VERSION "HNNBNNNYNNNNNNNNNNNNNNNNNNNNNNNNNNNNNNNNNN/4/%%%/4/'%**4NNN///"

NS_ :

BS_:

BU_: Airbag_D4 EPB_D4 ESP_D4 Gateway_D4C7 Getriebe_AL551_951_D4_C7 Getriebe_DL501_C7 Getriebe_VL381_C7 LWS_D4 Motor_EDC17_D4 Motor_ME17_BY Motor_MED17_SIMOS8_D4 Motor_Slave_D4 QSP_D4 SAK_C7 SCR_C7 SCU_D4

BO_ 3221225472 VECTOR__INDEPENDENT_SIG_MSG: 0 Vector__XXX
 SG_ AGA_Charisma_FahrPr : 0|4@1+ (1,0) [0|15] "" Vector__XXX
 SG_ AGA_Charisma_Status : 0|2@1+ (1,0) [0|3] "" Vector__XXX
 SG_ AGA_Verstaerker_Mute : 0|1@1+ (1,0) [0|1] "" Vector__XXX
 SG_ TPS_Airbag_Data : 0|56@1+ (1,0) [0|7.20575940379279E+016] "" Vector__XXX

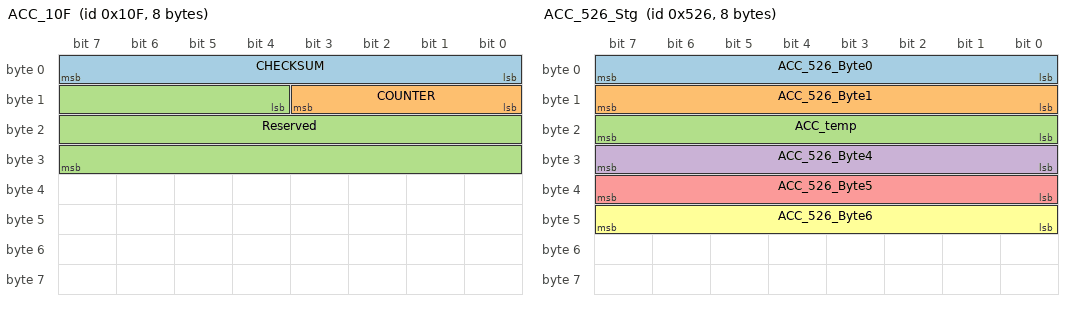
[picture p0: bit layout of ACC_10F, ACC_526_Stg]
BO_ 271 ACC_10F: 8 Gateway_B8
 SG_ CHECKSUM: 0|8@1+ (1,0) [0|255] "" J428
 SG_ COUNTER: 8|4@1+ (1,0) [0|15] "" J428
 SG_ Reserved: 12|20@1+ (1,0) [0|1048575] "" Antrieb

BO_ 785 ACC_311: 8 Gateway_B8
 SG_ CHECKSUM: 0|4@1+ (1,0) [0|15] "" J428
 SG_ COUNTER: 8|4@1+ (1,0) [0|15] "" J428
 SG_ ACC_311_Fahren1: 6|2@1+ (1,0) [0|3] "" J428
 SG_ ACC_311_Meldungen: 16|4@1+ (1,0) [0|15] "" J428
 SG_ ACC_311_Anzeige: 22|2@1+ (1,0) [0|3] "" J428
 SG_ ACC_311_Byte3: 0|8@1+ (1,0) [0|255] "" J428

BO_ 1318 ACC_526_Stg: 8 J428
 SG_ ACC_526_Byte0 : 0|8@1+ (1,0) [0|255] "" J428
 SG_ ACC_526_Byte1 : 8|8@1+ (1,0) [0|255] "" J428
 SG_ ACC_temp : 16|8@1+ (0.5,-30) [-30|90] "°C" J428
 SG_ ACC_526_Byte4 : 24|8@1+ (1,0) [0|255] "" J428
 SG_ ACC_526_Byte5 : 32|8@1+ (1,0) [0|255] "" J428
 SG_ ACC_526_Byte6 : 40|8@1+ (1,0) [0|255] "" J428

VAL_ 1318 ACC_526_Byte0 0 "Fernlicht" 1 "Ausschalten" 4 "Stand" 16 "Ueber_60_kmh" 20 "Unter_50_kmh" 128 "Anschalten";
VAL_ 1318 ACC_526_Byte4 16 "Kein_Objekt" 24 "Objekt_erkannt";

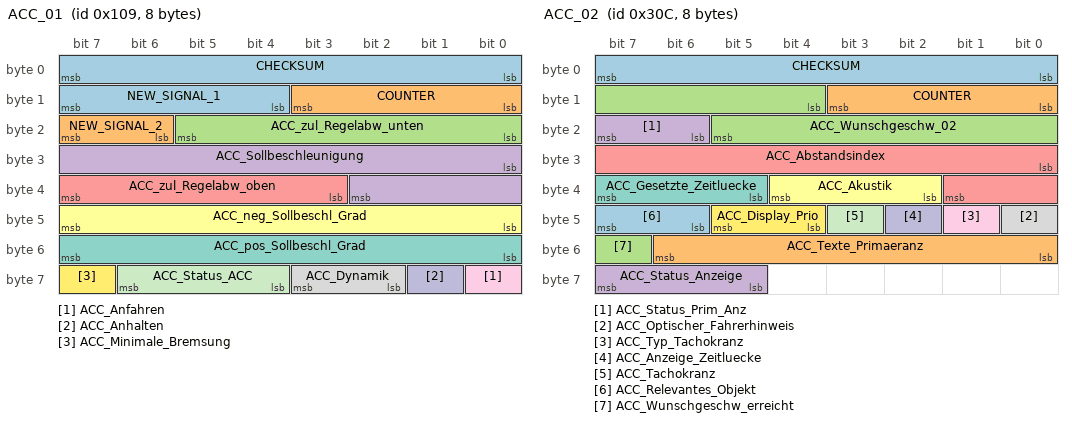
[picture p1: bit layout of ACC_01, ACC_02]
BO_ 265 ACC_01: 8 Gateway_B8
 SG_ CHECKSUM : 0|8@1+ (1,0) [0|255] ""  Magnetic_Ride_LB,Motor_MLB_AU48_AU416_Diesel,Motor_MLB_B8_Q5_Otto,Motor_MLB_Q5_Hybrid
 SG_ COUNTER : 8|4@1+ (1,0) [0|15] ""  Magnetic_Ride_LB,Motor_MLB_AU48_AU416_Diesel,Motor_MLB_B8_Q5_Otto,Motor_MLB_Q5_Hybrid
 SG_ ACC_zul_Regelabw_unten : 16|6@1+ (0.024,0) [0|1.512] "Unit_MeterPerSeconSquar"  Motor_MLB_AU48_AU416_Diesel,Motor_MLB_B8_Q5_Otto,Motor_MLB_Q5_Hybrid
 SG_ ACC_Sollbeschleunigung : 24|11@1+ (0.005,-7.22) [-7.22|3.01] "Unit_MeterPerSeconSquar"  Magnetic_Ride_LB,Motor_MLB_AU48_AU416_Diesel,Motor_MLB_B8_Q5_Otto,Motor_MLB_Q5_Hybrid
 SG_ ACC_zul_Regelabw_oben : 35|5@1+ (0.0625,0) [0|1.9375] "Unit_MeterPerSeconSquar"  Motor_MLB_AU48_AU416_Diesel,Motor_MLB_B8_Q5_Otto,Motor_MLB_Q5_Hybrid
 SG_ ACC_neg_Sollbeschl_Grad : 40|8@1+ (0.05,0) [0|12.7] "Unit_MeterPerCubicSecon"  Motor_MLB_AU48_AU416_Diesel,Motor_MLB_B8_Q5_Otto,Motor_MLB_Q5_Hybrid
 SG_ ACC_pos_Sollbeschl_Grad : 48|8@1+ (0.05,0) [0|12.7] "Unit_MeterPerCubicSecon"  Motor_MLB_AU48_AU416_Diesel,Motor_MLB_B8_Q5_Otto,Motor_MLB_Q5_Hybrid
 SG_ ACC_Dynamik : 58|2@1+ (1,0) [0|3] ""  Motor_MLB_AU48_AU416_Diesel,Motor_MLB_B8_Q5_Otto,Motor_MLB_Q5_Hybrid
 SG_ ACC_Anfahren : 56|1@1+ (1,0) [0|1] ""  XXX
 SG_ ACC_Anhalten : 57|1@1+ (1,0) [0|1] ""  XXX
 SG_ ACC_Status_ACC : 60|3@1+ (1,0) [0|7] ""  XXX
 SG_ ACC_Minimale_Bremsung : 63|1@1+ (1,0) [0|1] ""  Motor_MLB_AU48_AU416_Diesel,Motor_MLB_B8_Q5_Otto,Motor_MLB_Q5_Hybrid
 SG_ NEW_SIGNAL_1 : 15|4@0+ (1,0) [0|15] "" XXX
 SG_ NEW_SIGNAL_2 : 23|2@0+ (1,0) [0|3] "" XXX

BO_ 780 ACC_02: 8 Gateway_D4C7
 SG_ CHECKSUM : 0|8@1+ (1,0) [0|255] ""  HUD_C7,Kombi_D4
 SG_ COUNTER : 8|4@1+ (1,0) [0|15] ""  HUD_C7,Kombi_D4
 SG_ ACC_Wunschgeschw_02 : 12|10@1+ (0.32,0) [0.00|326.72] "Unit_KiloMeterPerHour"  HUD_C7,Kombi_D4
 SG_ ACC_Status_Prim_Anz : 22|2@1+ (1.0,0.0) [0.0|3] ""  HUD_C7,Kombi_D4
 SG_ ACC_Abstandsindex : 24|10@1+ (1,0) [1|1021] ""  HUD_C7,Kombi_D4
 SG_ ACC_Akustik : 34|3@1+ (1.0,0.0) [0.0|7] ""  Kombi_D4
 SG_ ACC_Gesetzte_Zeitluecke : 37|3@1+ (1.0,0.0) [0.0|7] ""  Kombi_D4
 SG_ ACC_Optischer_Fahrerhinweis : 40|1@1+ (1.0,0.0) [0.0|1] ""  Kombi_D4
 SG_ ACC_Typ_Tachokranz : 41|1@1+ (1.0,0.0) [0.0|1] ""  Kombi_D4
 SG_ ACC_Anzeige_Zeitluecke : 42|1@1+ (1.0,0.0) [0.0|1] ""  Kombi_D4
 SG_ ACC_Tachokranz : 43|1@1+ (1.0,0.0) [0.0|1] ""  Kombi_D4
 SG_ ACC_Display_Prio : 44|2@1+ (1.0,0.0) [0.0|3] ""  Vector__XXX
 SG_ ACC_Relevantes_Objekt : 46|2@1+ (1.0,0.0) [0.0|3] ""  HUD_C7,Kombi_D4
 SG_ ACC_Texte_Primaeranz : 48|7@1+ (1.0,0.0) [0.0|127] ""  HUD_C7,Kombi_D4
 SG_ ACC_Wunschgeschw_erreicht : 55|1@1+ (1.0,0.0) [0.0|1] ""  Kombi_D4
 SG_ ACC_Status_Anzeige : 61|3@1+ (1.0,0.0) [0.0|7] ""  APS_D4,Kombi_D4

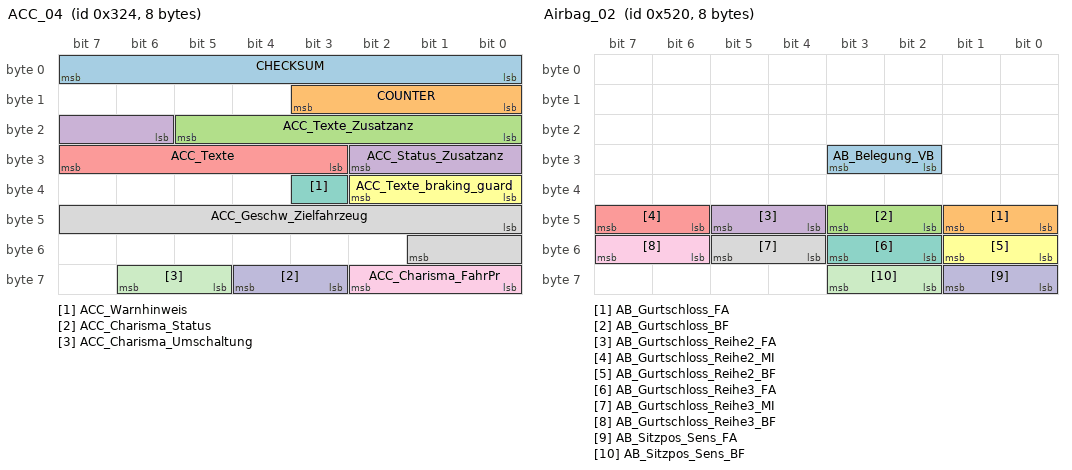
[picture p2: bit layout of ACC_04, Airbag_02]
BO_ 804 ACC_04: 8 Gateway_D4C7
 SG_ CHECKSUM : 0|8@1+ (1,0) [0|255] ""  HUD_C7,Kombi_D4
 SG_ COUNTER : 8|4@1+ (1,0) [0|15] ""  HUD_C7,Kombi_D4
 SG_ ACC_Texte_Zusatzanz : 16|6@1+ (1.0,0.0) [0.0|63] ""  Kombi_D4
 SG_ ACC_Status_Zusatzanz : 22|5@1+ (1.0,0.0) [0.0|31] ""  HUD_C7,Kombi_D4
 SG_ ACC_Texte : 27|5@1+ (1.0,0.0) [0.0|31] ""  Kombi_D4
 SG_ ACC_Texte_braking_guard : 32|3@1+ (1.0,0.0) [0.0|7] ""  HUD_C7,Kombi_D4
 SG_ ACC_Warnhinweis : 35|1@1+ (1.0,0.0) [0.0|1] ""  Vector__XXX
 SG_ ACC_Geschw_Zielfahrzeug : 40|10@1+ (0.32,0) [0.00|326.72] "Unit_KiloMeterPerHour"  Vector__XXX
 SG_ ACC_Charisma_FahrPr : 56|3@1+ (1.0,0.0) [0.0|7] ""  Vector__XXX
 SG_ ACC_Charisma_Status : 59|2@1+ (1.0,0.0) [0.0|3] ""  Vector__XXX
 SG_ ACC_Charisma_Umschaltung : 61|2@1+ (1.0,0.0) [0.0|3] ""  Vector__XXX

BO_ 269 ACC_05: 8 Gateway_D4C7
 SG_ CHECKSUM : 0|8@1+ (1,0) [0|255] ""  EPB_D4,Getriebe_AL551_951_D4_C7,Getriebe_DL501_C7,Getriebe_VL381_C7,Motor_EDC17_D4,Motor_ME17_BY,Motor_MED17_SIMOS8_D4
 SG_ COUNTER : 8|4@1+ (1,0) [0|15] ""  EPB_D4,Getriebe_AL551_951_D4_C7,Getriebe_DL501_C7,Getriebe_VL381_C7,Motor_EDC17_D4,Motor_ME17_BY,Motor_MED17_SIMOS8_D4
 SG_ ACC_Freigabe_Momentenanf : 12|1@1+ (1.0,0.0) [0.0|1] ""  Motor_EDC17_D4,Motor_ME17_BY,Motor_MED17_SIMOS8_D4
 SG_ ACC_Freigabe_Verzanf : 13|1@1+ (1.0,0.0) [0.0|1] ""  Getriebe_AL551_951_D4_C7,Getriebe_DL501_C7,Getriebe_VL381_C7
 SG_ ACC_Getriebestellung_P : 14|1@1+ (1.0,0.0) [0.0|1] ""  Getriebe_AL551_951_D4_C7,Getriebe_DL501_C7,Getriebe_VL381_C7
 SG_ ACC_limitierte_Anfahrdyn : 15|1@1+ (1.0,0.0) [0.0|1] ""  Motor_EDC17_D4,Motor_ME17_BY,Motor_MED17_SIMOS8_D4
 SG_ ACC_Momentenanforderung : 16|10@1+ (1,0) [0|1021] ""  Motor_EDC17_D4,Motor_ME17_BY,Motor_MED17_SIMOS8_D4
 SG_ ACC_zul_Regelabw : 26|6@1+ (0.024,0) [0.000|1.512] "Unit_MeterPerSeconSquar"  Getriebe_AL551_951_D4_C7,Getriebe_DL501_C7,Getriebe_VL381_C7
 SG_ ACC_Verz_anf : 32|11@1+ (0.005,-7.22) [-7.220|3.015] "Unit_MeterPerSeconSquar"  Vector__XXX
 SG_ ACC_Loeseanforderung : 43|1@1+ (1.0,0.0) [0.0|1] ""  Vector__XXX
 SG_ ACC_StartStopp_Info : 44|2@1+ (1.0,0.0) [0.0|3] ""  Motor_EDC17_D4,Motor_ME17_BY,Motor_MED17_SIMOS8_D4
 SG_ ACC_Vorbefuellung_Bremsanlage : 47|1@1+ (1.0,0.0) [0.0|1] ""  Vector__XXX
 SG_ ACC_ax_Getriebe : 48|9@1+ (0.024,-2.016) [-2.016|10.248] "Unit_MeterPerSeconSquar"  Getriebe_AL551_951_D4_C7,Getriebe_DL501_C7,Getriebe_VL381_C7
 SG_ ACC_Status_ACC : 57|3@1+ (1.0,0.0) [0.0|7] ""  EPB_D4,Motor_EDC17_D4,Motor_ME17_BY,Motor_MED17_SIMOS8_D4
 SG_ ACC_Betaetigung_EPB : 60|1@1+ (1.0,0.0) [0.0|1] ""  EPB_D4,Motor_EDC17_D4,Motor_ME17_BY,Motor_MED17_SIMOS8_D4
 SG_ ACC_Beeinflussung_ESP : 61|1@1+ (1.0,0.0) [0.0|1] ""  Vector__XXX
 SG_ ACC_Anhalten : 62|1@1+ (1.0,0.0) [0.0|1] ""  Vector__XXX
 SG_ ACC_KD_Fehler : 63|1@1+ (1.0,0.0) [0.0|1] ""  Vector__XXX

BO_ 64 Airbag_01: 8 Airbag_D4
 SG_ Airbag_01_CHK : 0|8@1+ (1,0) [0|255] ""  Gateway_D4C7,Motor_EDC17_D4,Motor_ME17_BY,Motor_MED17_SIMOS8_D4
 SG_ Airbag_01_BZ : 8|4@1+ (1,0) [0|15] ""  Gateway_D4C7,Motor_EDC17_D4,Motor_ME17_BY,Motor_MED17_SIMOS8_D4
 SG_ AB_RGS_Anst : 12|4@1+ (1.0,0.0) [0.0|15] ""  Gateway_D4C7
 SG_ AB_Front_Crash : 16|1@1+ (1.0,0.0) [0.0|1] ""  Gateway_D4C7
 SG_ AB_Heck_Crash : 17|1@1+ (1.0,0.0) [0.0|1] ""  Gateway_D4C7
 SG_ AB_SF_Crash : 18|1@1+ (1.0,0.0) [0.0|1] ""  Gateway_D4C7
 SG_ AB_SB_Crash : 19|1@1+ (1.0,0.0) [0.0|1] ""  Gateway_D4C7
 SG_ AB_Rollover_Crash : 20|1@1+ (1.0,0.0) [0.0|1] ""  Gateway_D4C7
 SG_ AB_Crash_Int : 21|3@1+ (1.0,0.0) [0.0|7] ""  Gateway_D4C7,Motor_EDC17_D4,Motor_ME17_BY,Motor_MED17_SIMOS8_D4
 SG_ AB_Lampe : 24|1@1+ (1.0,0.0) [0.0|1] ""  Gateway_D4C7
 SG_ AB_Deaktiviert : 25|1@1+ (1.0,0.0) [0.0|1] ""  Gateway_D4C7
 SG_ AB_VB_deaktiviert : 26|1@1+ (1.0,0.0) [0.0|1] ""  Gateway_D4C7
 SG_ AB_Systemfehler : 27|1@1+ (1.0,0.0) [0.0|1] ""  Gateway_D4C7
 SG_ AB_Diagnose : 28|1@1+ (1.0,0.0) [0.0|1] ""  Gateway_D4C7
 SG_ AB_Stellgliedtest : 29|1@1+ (1.0,0.0) [0.0|1] ""  Gateway_D4C7,Motor_EDC17_D4,Motor_ME17_BY,Motor_MED17_SIMOS8_D4
 SG_ AB_Erh_Auf_VB : 30|2@1+ (1.0,0.0) [0.0|3] ""  Gateway_D4C7
 SG_ AB_Gurtwarn_VF : 32|1@1+ (1.0,0.0) [0.0|1] ""  Gateway_D4C7
 SG_ AB_Gurtwarn_VB : 33|1@1+ (1.0,0.0) [0.0|1] ""  Gateway_D4C7
 SG_ AB_Anzeige_Fussg : 34|2@1+ (1.0,0.0) [0.0|3] ""  Gateway_D4C7
 SG_ AB_Texte_AKS : 36|2@1+ (1.0,0.0) [0.0|3] ""  Gateway_D4C7
 SG_ AB_PAO_Leuchte_Anf : 38|1@1+ (1.0,0.0) [0.0|1] ""  Gateway_D4C7
 SG_ AB_MKB_gueltig : 39|1@1+ (1.0,0.0) [0.0|1] ""  Gateway_D4C7
 SG_ AB_MKB_Anforderung : 40|1@1+ (1.0,0.0) [0.0|1] ""  Gateway_D4C7
 SG_ AB_Versorgungsspannung : 41|1@1+ (1.0,0.0) [0.0|1] ""  Gateway_D4C7
 SG_ AB_KD_Fehler : 63|1@1+ (1.0,0.0) [0.0|1] ""  Gateway_D4C7

BO_ 1312 Airbag_02: 8 Airbag_D4
 SG_ AB_Belegung_VB : 26|2@1+ (1.0,0.0) [0.0|3] ""  Gateway_D4C7
 SG_ AB_Gurtschloss_FA : 40|2@1+ (1.0,0.0) [0.0|3] ""  EPB_D4,Gateway_D4C7,Motor_EDC17_D4,Motor_ME17_BY,Motor_MED17_SIMOS8_D4
 SG_ AB_Gurtschloss_BF : 42|2@1+ (1.0,0.0) [0.0|3] ""  Gateway_D4C7
 SG_ AB_Gurtschloss_Reihe2_FA : 44|2@1+ (1.0,0.0) [0.0|3] ""  Gateway_D4C7
 SG_ AB_Gurtschloss_Reihe2_MI : 46|2@1+ (1.0,0.0) [0.0|3] ""  Gateway_D4C7
 SG_ AB_Gurtschloss_Reihe2_BF : 48|2@1+ (1.0,0.0) [0.0|3] ""  Gateway_D4C7
 SG_ AB_Gurtschloss_Reihe3_FA : 50|2@1+ (1.0,0.0) [0.0|3] ""  Gateway_D4C7
 SG_ AB_Gurtschloss_Reihe3_MI : 52|2@1+ (1.0,0.0) [0.0|3] ""  Gateway_D4C7
 SG_ AB_Gurtschloss_Reihe3_BF : 54|2@1+ (1.0,0.0) [0.0|3] ""  Gateway_D4C7
 SG_ AB_Sitzpos_Sens_FA : 56|2@1+ (1.0,0.0) [0.0|3] ""  Gateway_D4C7
 SG_ AB_Sitzpos_Sens_BF : 58|2@1+ (1.0,0.0) [0.0|3] ""  Gateway_D4C7

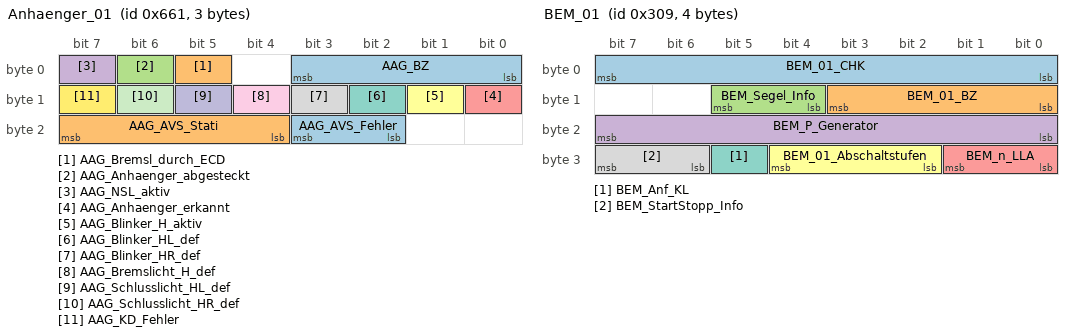
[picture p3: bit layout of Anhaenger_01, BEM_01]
BO_ 1633 Anhaenger_01: 3 Gateway_D4C7
 SG_ AAG_BZ : 0|4@1+ (1,0) [0|15] ""  Getriebe_AL551_951_D4_C7,Motor_EDC17_D4,Motor_ME17_BY,Motor_MED17_SIMOS8_D4
 SG_ AAG_Bremsl_durch_ECD : 5|1@1+ (1.0,0.0) [0.0|1] ""  Motor_EDC17_D4,Motor_ME17_BY,Motor_MED17_SIMOS8_D4
 SG_ AAG_Anhaenger_abgesteckt : 6|1@1+ (1.0,0.0) [0.0|1] ""  Vector__XXX
 SG_ AAG_NSL_aktiv : 7|1@1+ (1.0,0.0) [0.0|1] ""  Vector__XXX
 SG_ AAG_Anhaenger_erkannt : 8|1@1+ (1.0,0.0) [0.0|1] ""  Getriebe_AL551_951_D4_C7,Getriebe_DL501_C7,Getriebe_VL381_C7,Motor_EDC17_D4,Motor_ME17_BY,Motor_MED17_SIMOS8_D4
 SG_ AAG_Blinker_H_aktiv : 9|1@1+ (1.0,0.0) [0.0|1] ""  Vector__XXX
 SG_ AAG_Blinker_HL_def : 10|1@1+ (1.0,0.0) [0.0|1] ""  Vector__XXX
 SG_ AAG_Blinker_HR_def : 11|1@1+ (1.0,0.0) [0.0|1] ""  Vector__XXX
 SG_ AAG_Bremslicht_H_def : 12|1@1+ (1.0,0.0) [0.0|1] ""  Motor_EDC17_D4,Motor_ME17_BY,Motor_MED17_SIMOS8_D4
 SG_ AAG_Schlusslicht_HL_def : 13|1@1+ (1.0,0.0) [0.0|1] ""  Vector__XXX
 SG_ AAG_Schlusslicht_HR_def : 14|1@1+ (1.0,0.0) [0.0|1] ""  Vector__XXX
 SG_ AAG_KD_Fehler : 15|1@1+ (1.0,0.0) [0.0|1] ""  Vector__XXX
 SG_ AAG_AVS_Fehler : 18|2@1+ (1.0,0.0) [0.0|3] ""  Vector__XXX
 SG_ AAG_AVS_Stati : 20|4@1+ (1.0,0.0) [0.0|15] ""  Vector__XXX

BO_ 777 BEM_01: 4 Gateway_D4C7
 SG_ BEM_01_CHK : 0|8@1+ (1,0) [0|255] ""  Motor_EDC17_D4,Motor_ME17_BY,Motor_MED17_SIMOS8_D4
 SG_ BEM_01_BZ : 8|4@1+ (1,0) [0|15] ""  Motor_EDC17_D4,Motor_ME17_BY,Motor_MED17_SIMOS8_D4
 SG_ BEM_Segel_Info : 12|2@1+ (1.0,0.0) [0.0|3] ""  Vector__XXX
 SG_ BEM_P_Generator : 16|8@1+ (50,0) [0|12700] "Unit_Watt"  Motor_EDC17_D4,Motor_ME17_BY,Motor_MED17_SIMOS8_D4
 SG_ BEM_n_LLA : 24|2@1+ (1.0,0.0) [0.0|3] ""  Motor_EDC17_D4,Motor_ME17_BY,Motor_MED17_SIMOS8_D4
 SG_ BEM_01_Abschaltstufen : 26|3@1+ (1.0,0.0) [0.0|7] ""  Vector__XXX
 SG_ BEM_Anf_KL : 29|1@1+ (1.0,0.0) [0.0|1] ""  Motor_EDC17_D4,Motor_ME17_BY,Motor_MED17_SIMOS8_D4
 SG_ BEM_StartStopp_Info : 30|2@1+ (1.0,0.0) [0.0|3] ""  Motor_EDC17_D4,Motor_ME17_BY,Motor_MED17_SIMOS8_D4

BO_ 1635 BEM_02: 8 Gateway
 SG_ BEM_02_Abschaltstufen : 0|3@1+ (1,0) [0|7] "" Vector__XXX
 SG_ BEM_STH_Zielzeit : 3|4@1+ (5,0) [0|60] "Unit_Minut" Vector__XXX
 SG_ BEM_MMI_Vorwarnung : 7|1@1+ (1,0) [0|1] "" Vector__XXX
 SG_ BEM_HL_Kontingentierung : 8|6@1+ (50,-1000) [-1000|1000] "Unit_Watt" Vector__XXX
 SG_ NVEM_Anf_SD_schalten : 15|1@1+ (1,0) [0|1] "" Vector__XXX
 SG_ BEM_Generatordiagnose : 16|2@1+ (1,0) [0|3] "" Vector__XXX
 SG_ BEM_Red_Innengeblaese : 18|2@1+ (1,0) [0|3] "" Vector__XXX
 SG_ BEM_STH_Einschaltverbot : 20|1@1+ (1,0) [0|1] "" Vector__XXX
 SG_ BEM_HL_Regelung_Status : 21|3@1+ (1,0) [0|7] ""  Motor_MLB_AU64_AU57_Diesel
 SG_ BEM_Ladezustand : 24|4@1+ (10,0) [0|100] "Unit_PerCent" Vector__XXX
 SG_ BEM_Batteriediagnose : 28|3@1+ (1,0) [0|7] "" Vector__XXX
 SG_ MIB_Stromsparmodus : 31|1@1+ (1,0) [0|1] "" Vector__XXX
 SG_ BEM_DFM : 32|5@1+ (3.225,0.025) [0.025|100] "" Vector__XXX
 SG_ BEM_REK_aktiv : 37|1@1+ (1,0) [0|1] ""  Motor_MLB_AU64_AU57_Diesel
 SG_ BEM_EMLIN_ungueltig : 38|1@1+ (1,0) [0|1] "" Vector__XXX
 SG_ BEM_Batt_Ab : 39|1@1+ (1,0) [0|1] "" Vector__XXX
 SG_ BEM_UBDM : 40|8@1+ (0.05,5) [5.05|17.7] "Unit_Volt" Vector__XXX
 SG_ BEM_UGenSoll : 48|6@1+ (0.1,10.6) [10.6|16] "Unit_Volt" Vector__XXX
 SG_ BEM_Anf_KL15_schalten : 54|2@1+ (1,0) [0|3] "" Vector__XXX

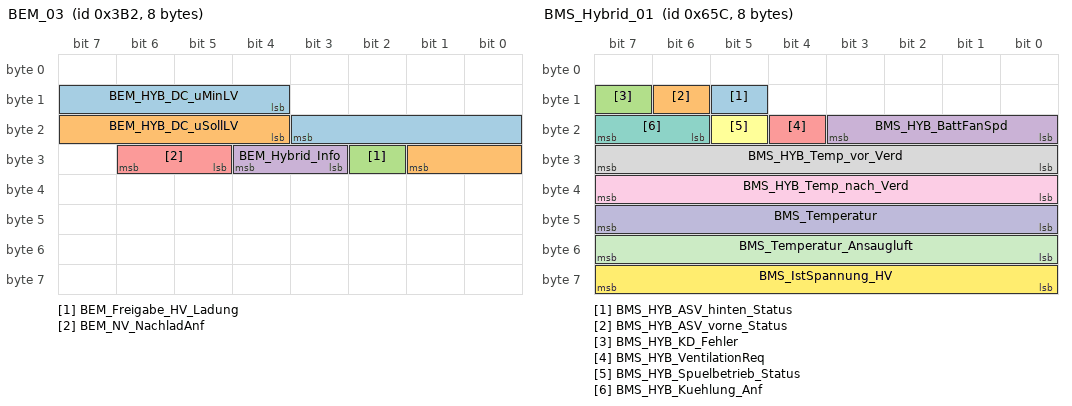
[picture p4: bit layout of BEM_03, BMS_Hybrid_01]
BO_ 946 BEM_03: 8 Gateway
 SG_ BEM_HYB_DC_uMinLV : 12|8@1+ (0.1,0) [0|25.3] "Unit_Volt"  LEH_Hybrid
 SG_ BEM_HYB_DC_uSollLV : 20|6@1+ (0.1,10.6) [10.6|16] "Unit_Volt"  LEH_Hybrid
 SG_ BEM_Freigabe_HV_Ladung : 26|1@1+ (1,0) [0|1] ""  Motor_MLB_C7_PHEV,Motor_MLB_D4_C7_Hybrid
 SG_ BEM_Hybrid_Info : 27|2@1+ (1,0) [0|3] ""  Motor_MLB_C7_PHEV,Motor_MLB_D4_C7_Hybrid
 SG_ BEM_NV_NachladAnf : 29|2@1+ (1,0) [0|3] "" Vector__XXX

BO_ 1628 BMS_Hybrid_01: 8 BMS_Hybrid
 SG_ BMS_HYB_ASV_hinten_Status : 13|1@1+ (1,0) [0|1] ""  Gateway
 SG_ BMS_HYB_ASV_vorne_Status : 14|1@1+ (1,0) [0|1] ""  Gateway
 SG_ BMS_HYB_KD_Fehler : 15|1@1+ (1,0) [0|1] ""  Gateway
 SG_ BMS_HYB_BattFanSpd : 16|4@1+ (10,0) [0|100] "Unit_PerCent"  Gateway
 SG_ BMS_HYB_VentilationReq : 20|1@1+ (1,0) [0|1] ""  Gateway
 SG_ BMS_HYB_Spuelbetrieb_Status : 21|1@1+ (1,0) [0|1] ""  Gateway
 SG_ BMS_HYB_Kuehlung_Anf : 22|2@1+ (1,0) [0|3] ""  Gateway
 SG_ BMS_HYB_Temp_vor_Verd : 24|8@1+ (0.5,-40) [-40|86.5] "Unit_DegreCelsi"  Gateway
 SG_ BMS_HYB_Temp_nach_Verd : 32|8@1+ (0.5,-40) [-40|86.5] "Unit_DegreCelsi"  Gateway
 SG_ BMS_Temperatur : 40|8@1+ (0.5,-40) [-40|86.5] "Unit_DegreCelsi"  Gateway
 SG_ BMS_Temperatur_Ansaugluft : 48|8@1+ (0.5,-40) [-40|86.5] "Unit_DegreCelsi"  Gateway
 SG_ BMS_IstSpannung_HV : 56|8@1+ (1,100) [100|350] "Unit_Volt"  Gateway

BO_ 917 LWR_AFS_01: 8 AFS_MLB
 SG_ AFS_Abbiegelicht_li_Anf : 0|1@1+ (1,0) [0|1] ""  Gateway_B8
 SG_ AFS_Abbiegelicht_re_Anf : 1|1@1+ (1,0) [0|1] ""  Gateway_B8
 SG_ AFS_Abbiegelicht_Dimm_Anf : 2|1@1+ (1,0) [0|1] ""  Gateway_B8
 SG_ AFS_Verfuegbarkeit_GLW : 3|1@1+ (1,0) [0|1] ""  Gateway_B8
 SG_ AFS_Status_adaptive_LV : 4|1@1+ (1,0) [0|1] ""  Gateway_B8
 SG_ AFS_Fernlicht_li_defekt : 5|1@1+ (1,0) [0|1] ""  Gateway_B8
 SG_ AFS_Fernlicht_re_defekt : 6|1@1+ (1,0) [0|1] ""  Gateway_B8
 SG_ AFS_Fernlicht_Status : 7|1@1+ (1,0) [0|1] ""  Gateway_B8
 SG_ LWR_AFS_01_BZ : 8|4@1+ (1,0) [0|15] ""  Gateway_B8
 SG_ AFS_Lampe : 12|1@1+ (1,0) [0|1] ""  Gateway_B8
 SG_ LWR_Lampe : 13|1@1+ (1,0) [0|1] ""  Gateway_B8
 SG_ AFS_Fehlertext : 14|1@1+ (1,0) [0|1] ""  Gateway_B8
 SG_ AFS_LED_Blinkmode : 15|1@1+ (1,0) [0|1] ""  Gateway_B8
 SG_ LWR_Touristenmodus_aktiv : 16|1@1+ (1,0) [0|1] ""  Gateway_B8
 SG_ AFS_Charisma_FahrPr : 17|3@1+ (1,0) [0|7] ""  Gateway_B8
 SG_ AFS_Charisma_Status : 20|2@1+ (1,0) [0|3] ""  Gateway_B8
 SG_ AFS_Charisma_Umschaltung : 22|2@1+ (1,0) [0|3] ""  Gateway_B8
 SG_ AFS_Allwetterlicht : 24|1@1+ (1,0) [0|1] ""  Gateway_B8
 SG_ LWR_Touristenmodus_verbaut : 25|1@1+ (1,0) [0|1] ""  Gateway_B8
 SG_ AFS_adaptive_LV_verbaut : 26|1@1+ (1,0) [0|1] ""  Gateway_B8
 SG_ LWR_Reisemodus_Texte : 27|2@1+ (1,0) [0|3] ""  Gateway_B8
 SG_ GLW_Sensor_blockiert : 29|1@1+ (1,0) [0|1] ""  Gateway_B8
 SG_ LWR_Pos_Schrittmotor : 32|8@1+ (0.4,0) [0|100] "Unit_PerCent"  Gateway_B8
 SG_ LWR_Hoehenwert_VL : 40|8@1+ (1,-127) [-127|126] ""  Gateway_B8
 SG_ LWR_Hoehenwert_HL : 48|8@1+ (1,-127) [-127|126] ""  Gateway_B8
 SG_ AFS_Ersatzlicht_Links : 56|1@1+ (1,0) [0|1] ""  Gateway_B8
 SG_ AFS_Ersatzlicht_Rechts : 57|1@1+ (1,0) [0|1] ""  Gateway_B8
 SG_ LWR_AFS_Grundeinstellung : 58|1@1+ (1,0) [0|1] ""  Gateway_B8
 SG_ LWR_AFS_Parametrisierung : 59|1@1+ (1,0) [0|1] ""  Gateway_B8
 SG_ LWR_Initialisierungslauf : 60|1@1+ (1,0) [0|1] ""  Gateway_B8
 SG_ LWR_Sicherheitsposition : 61|1@1+ (1,0) [0|1] ""  Gateway_B8
 SG_ LWR_Modus : 62|1@1+ (1,0) [0|1] ""  Gateway_B8
 SG_ LWR_KD_Fehler : 63|1@1+ (1,0) [0|1] ""  Gateway_B8

BO_ 867 Blinkmodi_01: 4 Gateway_D4C7
 SG_ BM_ZV_auf : 0|1@1+ (1.0,0.0) [0.0|1] ""  Vector__XXX
 SG_ BM_ZV_zu : 1|1@1+ (1.0,0.0) [0.0|1] ""  Vector__XXX
 SG_ BM_DWA_ein : 2|1@1+ (1.0,0.0) [0.0|1] ""  Vector__XXX
 SG_ BM_DWA_Alarm : 3|1@1+ (1.0,0.0) [0.0|1] ""  Vector__XXX
 SG_ BM_Crash : 4|1@1+ (1.0,0.0) [0.0|1] ""  Vector__XXX
 SG_ BM_Panik : 5|1@1+ (1.0,0.0) [0.0|1] ""  Vector__XXX
 SG_ BM_Not_Bremsung : 6|1@1+ (1.0,0.0) [0.0|1] ""  Vector__XXX
 SG_ BM_GDO : 7|1@1+ (1.0,0.0) [0.0|1] ""  Vector__XXX
 SG_ BM_links : 8|1@1+ (1.0,0.0) [0.0|1] ""  Vector__XXX
 SG_ BM_rechts : 9|1@1+ (1.0,0.0) [0.0|1] ""  Vector__XXX
 SG_ BM_Warnblinken : 10|1@1+ (1.0,0.0) [0.0|1] ""  Vector__XXX
 SG_ BM_Autobahn : 11|1@1+ (1.0,0.0) [0.0|1] ""  Vector__XXX
 SG_ BM_Taxi_Notalarm : 12|1@1+ (1.0,0.0) [0.0|1] ""  Vector__XXX
 SG_ BM_Telematik : 13|1@1+ (1.0,0.0) [0.0|1] ""  Vector__XXX
 SG_ BM_HD_Oeffnung_angelernt : 14|1@1+ (1.0,0.0) [0.0|1] ""  Vector__XXX
 SG_ BM_WBT_Beleuchtung : 15|1@1+ (1.0,0.0) [0.0|1] ""  Vector__XXX
 SG_ Blinken_li_Fzg_Takt : 16|1@1+ (1.0,0.0) [0.0|1] ""  Vector__XXX
 SG_ Blinken_re_Fzg_Takt : 17|1@1+ (1.0,0.0) [0.0|1] ""  Vector__XXX
 SG_ Blinken_li_Kombi_Takt : 18|1@1+ (1.0,0.0) [0.0|1] ""  Kombi_D4
 SG_ Blinken_re_Kombi_Takt : 19|1@1+ (1.0,0.0) [0.0|1] ""  Kombi_D4
 SG_ BM_NBA_n_codiert_n_aktiv : 20|1@1+ (1.0,0.0) [0.0|1] ""  Vector__XXX
 SG_ BM_NBA_Status : 21|2@1+ (1.0,0.0) [0.0|3] ""  Vector__XXX
 SG_ Blinken_FWB_aktiv : 23|1@1+ (1.0,0.0) [0.0|1] ""  Vector__XXX

BO_ 1409 BCM2_02: 8 Gateway
 SG_ BCM_FH_Freigabe : 0|1@1+ (1,0) [0|1] "" Vector__XXX
 SG_ BCM_Komfortfkt_Freigabe : 1|1@1+ (1,0) [0|1] "" Vector__XXX
 SG_ BCM_HSK_Freigabe : 2|1@1+ (1,0) [0|1] "" Vector__XXX
 SG_ BCM_Verdeck_Freigabe : 3|1@1+ (1,0) [0|1] "" Vector__XXX
 SG_ BCM2_Status_Timer_KL15_Abschalt : 4|1@1+ (1,0) [0|1] "" Vector__XXX
 SG_ BCM2_Anford_AbschaltfreigabeKL15 : 5|1@1+ (1,0) [0|1] "" Vector__XXX
 SG_ BCM2_Unterdr_Zuendungsmeldung : 6|1@1+ (1,0) [0|1] "" Vector__XXX
 SG_ BCM2_KL15_Absch_FT : 7|1@1+ (1,0) [0|1] "" Vector__XXX
 SG_ ZV_ist_Zustand_verfuegbar : 8|1@1+ (1,0) [0|1] "" Vector__XXX
 SG_ BCM2_P_verriegelt : 9|1@1+ (1,0) [0|1] "" Vector__XXX
 SG_ ZV_verriegelt_intern_ist : 10|1@1+ (1,0) [0|1] "" Vector__XXX
 SG_ ZV_verriegelt_extern_ist : 11|1@1+ (1,0) [0|1] "" Vector__XXX
 SG_ ZV_verriegelt_intern_soll : 12|1@1+ (1,0) [0|1] "" Vector__XXX
 SG_ ZV_verriegelt_extern_soll : 13|1@1+ (1,0) [0|1] ""  Motor_MLB_C7_PHEV
 SG_ ZV_gesafet_extern_ist : 14|1@1+ (1,0) [0|1] "" Vector__XXX
 SG_ ZV_gesafet_extern_soll : 15|1@1+ (1,0) [0|1] "" Vector__XXX
 SG_ ZV_FT_offen : 16|1@1+ (1,0) [0|1] "" Vector__XXX
 SG_ ZV_BT_offen : 17|1@1+ (1,0) [0|1] "" Vector__XXX
 SG_ ZV_HL_offen : 18|1@1+ (1,0) [0|1] "" Vector__XXX
 SG_ ZV_HR_offen : 19|1@1+ (1,0) [0|1] "" Vector__XXX
 SG_ ZV_HD_offen : 20|1@1+ (1,0) [0|1] "" Vector__XXX
 SG_ ZV_Turen_HD_zu : 21|1@1+ (1,0) [0|1] "" Vector__XXX
 SG_ ZV_Einzeltuerentriegelung : 22|1@1+ (1,0) [0|1] "" Vector__XXX
 SG_ ZV_Heckeinzelentriegelung : 23|1@1+ (1,0) [0|1] "" Vector__XXX
 SG_ BCM_ValetTaster_Fkts_LED : 24|1@1+ (1,0) [0|1] "" Vector__XXX
 SG_ BCM_HHS_aktiv : 25|1@1+ (1,0) [0|1] "" Vector__XXX
 SG_ BCM_Spg_Hzg_Ein : 26|1@1+ (1,0) [0|1] "" Vector__XXX
 SG_ ZV_HS_offen : 27|1@1+ (1,0) [0|1] "" Vector__XXX
 SG_ ZZH_Endlage_oben : 28|1@1+ (1,0) [0|1] "" Vector__XXX
 SG_ ZZH_Endlage_unten : 29|1@1+ (1,0) [0|1] "" Vector__XXX
 SG_ ZZH_Endlage_unplausibel : 30|1@1+ (1,0) [0|1] "" Vector__XXX
 SG_ BCM2_KD_Fehler : 31|1@1+ (1,0) [0|1] "" Vector__XXX
 SG_ NGS_aktiv : 32|1@1+ (1,0) [0|1] "" Vector__XXX
 SG_ IRUE_aktiv : 33|1@1+ (1,0) [0|1] "" Vector__XXX
 SG_ DWA_aktiv : 34|1@1+ (1,0) [0|1] "" Vector__XXX
 SG_ Komp_Schutz_aktiv : 35|1@1+ (1,0) [0|1] "" Vector__XXX
 SG_ NGS_Taster_Fkts_LED : 36|1@1+ (1,0) [0|1] "" Vector__XXX
 SG_ IRUE_Taster_Fkts_LED : 37|1@1+ (1,0) [0|1] "" Vector__XXX
 SG_ HD_Drehfalle_S1 : 38|1@1+ (1,0) [0|1] "" Vector__XXX
 SG_ HD_Sperrklinke_S2 : 39|1@1+ (1,0) [0|1] "" Vector__XXX
 SG_ BCM_Verbau_Heckrollo : 40|1@1+ (1,0) [0|1] "" Vector__XXX
 SG_ BCM2_EZS_gedrueckt : 41|1@1+ (1,0) [0|1] "" Vector__XXX
 SG_ BCM2_SST_gedrueckt : 42|1@1+ (1,0) [0|1] "" Vector__XXX
 SG_ LIM_alt : 43|1@1+ (1,0) [0|1] "" Vector__XXX
 SG_ LIM_Innenbeleuchtung_V_aktiv : 44|1@1+ (1,0) [0|1] "" Vector__XXX
 SG_ LIM_Innenbeleuchtung_aktiv : 45|1@1+ (1,0) [0|1] "" Vector__XXX
 SG_ LIM_Taster_Rollolicht_hl : 46|1@1+ (1,0) [0|1] "" Vector__XXX
 SG_ LIM_Taster_Rollolicht_hr : 47|1@1+ (1,0) [0|1] "" Vector__XXX
 SG_ BCM_Sperrklinke_FT : 48|1@1+ (1,0) [0|1] ""  EPB_MLB
 SG_ LIM_Taster_Rollolicht_V : 49|1@1+ (1,0) [0|1] "" Vector__XXX
 SG_ BCM_Tankwunsch : 50|2@1+ (1,0) [0|3] "" Vector__XXX
 SG_ ZV_Tankklappe_offen : 52|1@1+ (1,0) [0|1] ""  Motor_MLB_C7_PHEV
 SG_ BCM_Tankklappensteller_Fehler : 53|1@1+ (1,0) [0|1] ""  Motor_MLB_C7_PHEV
 SG_ KST_Fahrer_Hinweise : 56|3@1+ (1,0) [0|7] "" Vector__XXX
 SG_ KST_Warn_P1_ZST_def : 59|1@1+ (1,0) [0|1] "" Vector__XXX
 SG_ KST_Warn_P2_ZST_def : 60|1@1+ (1,0) [0|1] "" Vector__XXX
 SG_ KST_Prio_Warn_03 : 61|1@1+ (1,0) [0|1] "" Vector__XXX
 SG_ KST_Prio_Warn_04 : 62|1@1+ (1,0) [0|1] "" Vector__XXX
 SG_ KST_Prio_Warn_05 : 63|1@1+ (1,0) [0|1] "" Vector__XXX

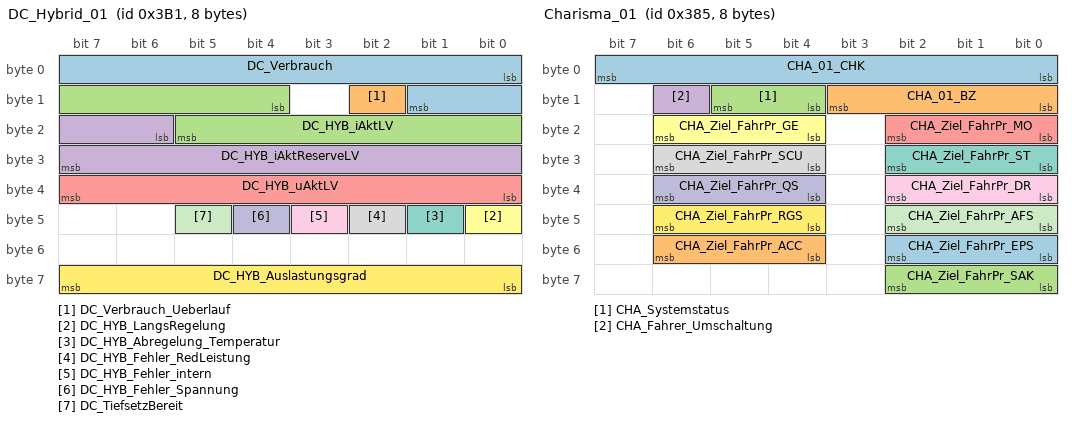
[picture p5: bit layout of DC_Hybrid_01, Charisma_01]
BO_ 945 DC_Hybrid_01: 8 LEH_Hybrid
 SG_ DC_Verbrauch : 0|10@1+ (1,0) [0|1023] "Unit_WattSecond" Vector__XXX
 SG_ DC_Verbrauch_Ueberlauf : 10|1@1+ (1,0) [0|1] "" Vector__XXX
 SG_ DC_HYB_iAktLV : 12|10@1+ (1,-511) [-511|510] "Unit_Amper"  Gateway
 SG_ DC_HYB_iAktReserveLV : 22|10@1+ (1,-511) [-511|510] "Unit_Amper"  Gateway
 SG_ DC_HYB_uAktLV : 32|8@1+ (0.1,0) [0|25.3] "Unit_Volt"  Gateway
 SG_ DC_HYB_LangsRegelung : 40|1@1+ (1,0) [0|1] ""  Gateway
 SG_ DC_HYB_Abregelung_Temperatur : 41|1@1+ (1,0) [0|1] ""  Gateway
 SG_ DC_HYB_Fehler_RedLeistung : 42|1@1+ (1,0) [0|1] ""  Gateway
 SG_ DC_HYB_Fehler_intern : 43|1@1+ (1,0) [0|1] ""  Gateway
 SG_ DC_HYB_Fehler_Spannung : 44|1@1+ (1,0) [0|1] ""  Gateway
 SG_ DC_TiefsetzBereit : 45|1@1+ (1,0) [0|1] "" Vector__XXX
 SG_ DC_HYB_Auslastungsgrad : 56|8@1+ (0.4,0) [0|100] "Unit_PerCent" Vector__XXX

BO_ 482 CCP_GE_CR0_01: 8 Gateway_D4C7
 SG_ CCP_GE_CRO_01_Data : 0|64@1+ (1,0) [0|1] ""  Getriebe_AL551_951_D4_C7,Getriebe_DL501_C7,Getriebe_VL381_C7

BO_ 490 CCP_GE_DTO_01: 8 Getriebe_AL551_951_D4_C7
 SG_ CCP_GE_DTO_01_Data : 0|64@1+ (1,0) [0|1] ""  Gateway_D4C7

BO_ 480 CCP_MO_CRO_01: 8 Gateway_D4C7
 SG_ CCP_MO_CRO_01_Data : 0|64@1+ (1,0) [0|1] ""  Motor_EDC17_D4,Motor_ME17_BY,Motor_MED17_SIMOS8_D4

BO_ 2616986624 CCP_MO_CRO_02: 8 Vector__XXX
 SG_ CCP_MO_CRO_02_Data : 0|64@1+ (1,0) [0|1] ""  Motor_EDC17_D4,Motor_ME17_BY,Motor_MED17_SIMOS8_D4

BO_ 488 CCP_MO_DTO_01: 8 Motor_EDC17_D4
 SG_ CCP_MO_DTO_01_Data : 0|64@1+ (1,0) [0|1] ""  Gateway_D4C7

BO_ 2616986625 CCP_MO_DTO_02: 8 Motor_EDC17_D4
 SG_ CCP_MO_DTO_02_Data : 0|64@1+ (1,0) [0|1] ""  Vector__XXX

BO_ 481 CCP_MOS_CRO_01: 8 Gateway_D4C7
 SG_ CCP_MOS_CRO_01_Data : 0|64@1+ (1,0) [0|1] ""  Motor_Slave_D4

BO_ 2616986629 CCP_MOS_CRO_02: 8 Vector__XXX
 SG_ CCP_MOS_CRO_02_Data : 0|64@1+ (1,0) [0|1] ""  Motor_Slave_D4

BO_ 489 CCP_MOS_DTO_01: 8 Motor_Slave_D4
 SG_ CCP_MOS_DTO_01_Data : 0|64@1+ (1,0) [0|1] ""  Gateway_D4C7

BO_ 2616986630 CCP_MOS_DTO_02: 8 Motor_Slave_D4
 SG_ CCP_MOS_DTO_02_Data : 0|64@1+ (1,0) [0|1] ""  Vector__XXX

BO_ 2617042432 CCP_Soundaktor_CRO_01: 8 Vector__XXX
 SG_ CCP_Soundaktor_CRO_01_Data : 0|64@1+ (1.0,0.0) [0.0|18446744073709551615] ""  SAK_C7

BO_ 2617042433 CCP_Soundaktor_DTO_01: 8 SAK_C7
 SG_ CCP_Soundaktor_DTO_01_Data : 0|64@1+ (1.0,0.0) [0.0|18446744073709551615] ""  Vector__XXX

BO_ 901 Charisma_01: 8 Gateway_D4C7
 SG_ CHA_01_CHK : 0|8@1+ (1,0) [0|255] ""  Getriebe_AL551_951_D4_C7,Getriebe_DL501_C7,Getriebe_VL381_C7,Motor_EDC17_D4,Motor_ME17_BY,Motor_MED17_SIMOS8_D4,SCU_D4
 SG_ CHA_01_BZ : 8|4@1+ (1,0) [0|15] ""  Motor_EDC17_D4,Motor_ME17_BY,Motor_MED17_SIMOS8_D4
 SG_ CHA_Systemstatus : 12|2@1+ (1.0,0.0) [0.0|3] ""  Getriebe_AL551_951_D4_C7,Getriebe_DL501_C7,Getriebe_VL381_C7,Motor_EDC17_D4,Motor_ME17_BY,Motor_MED17_SIMOS8_D4,SCU_D4
 SG_ CHA_Fahrer_Umschaltung : 14|1@1+ (1.0,0.0) [0.0|1] ""  Vector__XXX
 SG_ CHA_Ziel_FahrPr_MO : 16|3@1+ (1.0,0.0) [0.0|7] ""  Motor_EDC17_D4,Motor_ME17_BY,Motor_MED17_SIMOS8_D4
 SG_ CHA_Ziel_FahrPr_GE : 20|3@1+ (1.0,0.0) [0.0|7] ""  Getriebe_AL551_951_D4_C7,Getriebe_DL501_C7,Getriebe_VL381_C7
 SG_ CHA_Ziel_FahrPr_ST : 24|3@1+ (1.0,0.0) [0.0|7] ""  Vector__XXX
 SG_ CHA_Ziel_FahrPr_SCU : 28|3@1+ (1.0,0.0) [0.0|7] ""  SCU_D4
 SG_ CHA_Ziel_FahrPr_DR : 32|3@1+ (1.0,0.0) [0.0|7] ""  Vector__XXX
 SG_ CHA_Ziel_FahrPr_QS : 36|3@1+ (1.0,0.0) [0.0|7] ""  Vector__XXX
 SG_ CHA_Ziel_FahrPr_AFS : 40|3@1+ (1.0,0.0) [0.0|7] ""  Vector__XXX
 SG_ CHA_Ziel_FahrPr_RGS : 44|3@1+ (1.0,0.0) [0.0|7] ""  Vector__XXX
 SG_ CHA_Ziel_FahrPr_EPS : 48|3@1+ (1.0,0.0) [0.0|7] ""  Vector__XXX
 SG_ CHA_Ziel_FahrPr_ACC : 52|3@1+ (1.0,0.0) [0.0|7] ""  Vector__XXX
 SG_ CHA_Ziel_FahrPr_SAK : 56|3@1+ (1.0,0.0) [0.0|7] ""  Vector__XXX

BO_ 2617027072 DEV_Airbag_01: 4 Airbag_D4
 SG_ DEV_Airbag_01 : 0|32@1+ (1.0,0.0) [0.0|4294967295] ""  Vector__XXX

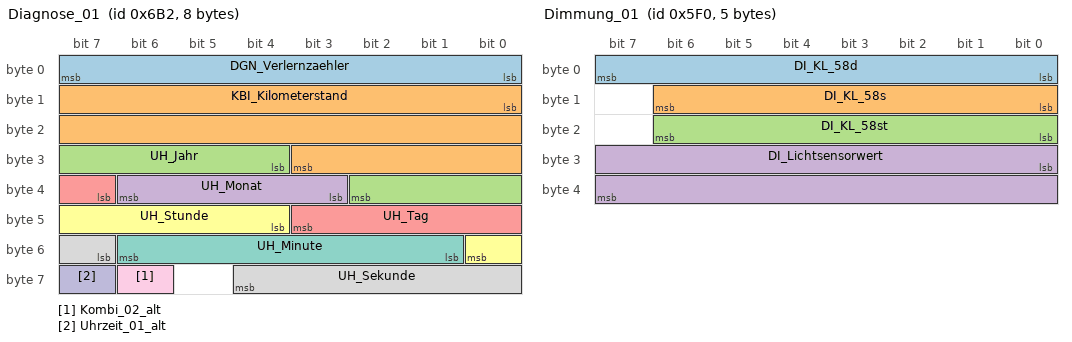
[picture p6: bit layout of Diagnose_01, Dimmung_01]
BO_ 1714 Diagnose_01: 8 Gateway_D4C7
 SG_ DGN_Verlernzaehler : 0|8@1+ (1,0) [0|254] ""  Airbag_D4,EPB_D4,Getriebe_AL551_951_D4_C7,SAK_C7,SCR_C7,SCU_D4
 SG_ KBI_Kilometerstand : 8|20@1+ (1,0) [0|1048573] "Unit_KiloMeter"  Airbag_D4,EPB_D4,Getriebe_AL551_951_D4_C7,Getriebe_DL501_C7,Getriebe_VL381_C7,Motor_EDC17_D4,Motor_ME17_BY,Motor_MED17_SIMOS8_D4,SAK_C7,SCR_C7,SCU_D4
 SG_ UH_Jahr : 28|7@1+ (1,2000) [2000|2127] "Unit_Year"  Airbag_D4,EPB_D4,Getriebe_AL551_951_D4_C7,Getriebe_DL501_C7,Getriebe_VL381_C7,Motor_EDC17_D4,Motor_ME17_BY,Motor_MED17_SIMOS8_D4,SAK_C7,SCR_C7,SCU_D4
 SG_ UH_Monat : 35|4@1+ (1,0) [1|12] "Unit_Month"  Airbag_D4,EPB_D4,Getriebe_AL551_951_D4_C7,Getriebe_DL501_C7,Getriebe_VL381_C7,Motor_EDC17_D4,Motor_ME17_BY,Motor_MED17_SIMOS8_D4,SAK_C7,SCR_C7,SCU_D4
 SG_ UH_Tag : 39|5@1+ (1,0) [1|31] "Unit_Day"  Airbag_D4,EPB_D4,Getriebe_AL551_951_D4_C7,Getriebe_DL501_C7,Getriebe_VL381_C7,Motor_EDC17_D4,Motor_ME17_BY,Motor_MED17_SIMOS8_D4,SAK_C7,SCR_C7,SCU_D4
 SG_ UH_Stunde : 44|5@1+ (1,0) [0|23] "Unit_Hours"  Airbag_D4,EPB_D4,Getriebe_AL551_951_D4_C7,Getriebe_DL501_C7,Getriebe_VL381_C7,Motor_EDC17_D4,Motor_ME17_BY,Motor_MED17_SIMOS8_D4,SAK_C7,SCR_C7,SCU_D4
 SG_ UH_Minute : 49|6@1+ (1,0) [0|59] "Unit_Minut"  Airbag_D4,EPB_D4,Getriebe_AL551_951_D4_C7,Getriebe_DL501_C7,Getriebe_VL381_C7,Motor_EDC17_D4,Motor_ME17_BY,Motor_MED17_SIMOS8_D4,SAK_C7,SCR_C7,SCU_D4
 SG_ UH_Sekunde : 55|6@1+ (1,0) [0|59] "Unit_Secon"  Airbag_D4,EPB_D4,Getriebe_AL551_951_D4_C7,Getriebe_DL501_C7,Getriebe_VL381_C7,Motor_EDC17_D4,Motor_ME17_BY,Motor_MED17_SIMOS8_D4,SAK_C7,SCR_C7,SCU_D4
 SG_ Kombi_02_alt : 62|1@1+ (1.0,0.0) [0.0|1] ""  Airbag_D4,Getriebe_AL551_951_D4_C7,Getriebe_DL501_C7,Getriebe_VL381_C7,SCR_C7,SCU_D4
 SG_ Uhrzeit_01_alt : 63|1@1+ (1.0,0.0) [0.0|1] ""  Airbag_D4,Getriebe_AL551_951_D4_C7,Getriebe_DL501_C7,Getriebe_VL381_C7,SCR_C7,SCU_D4

BO_ 1520 Dimmung_01: 5 Gateway_D4C7
 SG_ DI_KL_58d : 0|8@1+ (1,0) [0|253] ""  Airbag_D4,Getriebe_AL551_951_D4_C7
 SG_ DI_KL_58s : 8|7@1+ (1,0) [0|100] "Unit_PerCent"  Getriebe_AL551_951_D4_C7
 SG_ DI_KL_58st : 16|7@1+ (1,0) [0|100] "Unit_PerCent"  Getriebe_AL551_951_D4_C7
 SG_ DI_Lichtsensorwert : 24|16@1+ (1,0) [0|65535] ""  Airbag_D4,Getriebe_AL551_951_D4_C7

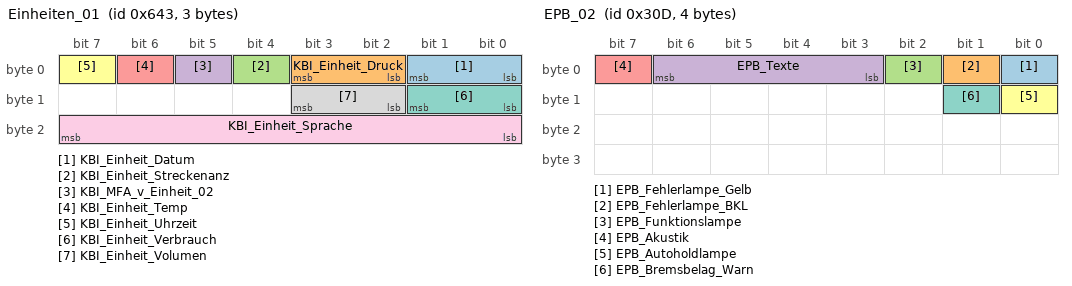
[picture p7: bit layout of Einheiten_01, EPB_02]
BO_ 1603 Einheiten_01: 3 Gateway_D4C7
 SG_ KBI_Einheit_Datum : 0|2@1+ (1.0,0.0) [0.0|3] ""  Vector__XXX
 SG_ KBI_Einheit_Druck : 2|2@1+ (1.0,0.0) [0.0|3] ""  Vector__XXX
 SG_ KBI_Einheit_Streckenanz : 4|1@1+ (1.0,0.0) [0.0|1] ""  Motor_EDC17_D4
 SG_ KBI_MFA_v_Einheit_02 : 5|1@1+ (1.0,0.0) [0.0|1] ""  Vector__XXX
 SG_ KBI_Einheit_Temp : 6|1@1+ (1.0,0.0) [0.0|1] ""  Vector__XXX
 SG_ KBI_Einheit_Uhrzeit : 7|1@1+ (1.0,0.0) [0.0|1] ""  Vector__XXX
 SG_ KBI_Einheit_Verbrauch : 8|2@1+ (1.0,0.0) [0.0|3] ""  Vector__XXX
 SG_ KBI_Einheit_Volumen : 10|2@1+ (1.0,0.0) [0.0|3] ""  Vector__XXX
 SG_ KBI_Einheit_Sprache : 16|8@1+ (1,0) [0|255] ""  Vector__XXX

BO_ 1627 EM_Hybrid_01: 8 LEH_Hybrid
 SG_ EM_HYB_KD_Fehler : 15|1@1+ (1,0) [0|1] ""  Gateway

BO_ 260 EPB_01: 8 EPB_D4
 SG_ EPB_01_CHK : 0|8@1+ (1,0) [0|255] ""  Gateway_D4C7,Motor_EDC17_D4,Motor_ME17_BY,Motor_MED17_SIMOS8_D4
 SG_ EPB_01_BZ : 8|4@1+ (1,0) [0|15] ""  Gateway_D4C7,Motor_EDC17_D4,Motor_ME17_BY,Motor_MED17_SIMOS8_D4
 SG_ EPB_QBit_Laengsbeschleunigung : 12|1@1+ (1.0,0.0) [0.0|1] ""  Gateway_D4C7
 SG_ EPB_QBit_Pedalweg_Kuppl : 13|1@1+ (1.0,0.0) [0.0|1] ""  Gateway_D4C7,Motor_EDC17_D4,Motor_ME17_BY,Motor_MED17_SIMOS8_D4
 SG_ EPB_BCM2_Motor_Wakeup : 14|1@1+ (1.0,0.0) [0.0|1] ""  Gateway_D4C7
 SG_ EPB_Freig_Verzoeg_Anf : 15|1@1+ (1.0,0.0) [0.0|1] ""  Gateway_D4C7,Getriebe_AL551_951_D4_C7,Motor_EDC17_D4,Motor_ME17_BY,Motor_MED17_SIMOS8_D4
 SG_ EPB_Verzoeg_Anf : 16|8@1+ (0.048,-7.968) [-7.968|4.224] "Unit_MeterPerSeconSquar"  Gateway_D4C7
 SG_ EPB_Laengsbeschleunigung : 24|8@1+ (1,-128) [-128|126] "Unit_PerCentOfForceOfGravi"  Gateway_D4C7
 SG_ EPB_Pedalweg_Kuppl : 32|8@1+ (0.4,0) [8.0|92.0] "Unit_PerCent"  Gateway_D4C7,Motor_EDC17_D4,Motor_ME17_BY,Motor_MED17_SIMOS8_D4
 SG_ EPB_Anfahrwunsch_erkannt : 48|1@1+ (1.0,0.0) [0.0|1] ""  Gateway_D4C7
 SG_ EPB_DAA_Randbed_erf : 49|1@1+ (1.0,0.0) [0.0|1] ""  Gateway_D4C7
 SG_ EPB_Fehlerstatus : 50|2@1+ (1.0,0.0) [0.0|3] ""  Gateway_D4C7
 SG_ EPB_Schalterposition : 52|2@1+ (1.0,0.0) [0.0|3] ""  Gateway_D4C7,Getriebe_AL551_951_D4_C7,Motor_EDC17_D4,Motor_ME17_BY,Motor_MED17_SIMOS8_D4
 SG_ EPB_QBit_Schalterpos : 54|1@1+ (1.0,0.0) [0.0|1] ""  Gateway_D4C7,Getriebe_AL551_951_D4_C7,Motor_EDC17_D4,Motor_ME17_BY,Motor_MED17_SIMOS8_D4
 SG_ EPB_Konsistenz_ACC : 55|1@1+ (1.0,0.0) [0.0|1] ""  Gateway_D4C7
 SG_ EPB_Spannkraft : 56|5@1+ (1,0) [0|29] "Unit_KiloNewto"  Gateway_D4C7,Getriebe_AL551_951_D4_C7,Getriebe_DL501_C7,Getriebe_VL381_C7
 SG_ EPB_Status : 61|2@1+ (1.0,0.0) [0.0|3] ""  Gateway_D4C7,Getriebe_AL551_951_D4_C7,Getriebe_DL501_C7,Motor_EDC17_D4,Motor_ME17_BY,Motor_MED17_SIMOS8_D4
 SG_ EPB_KD_Fehler : 63|1@1+ (1.0,0.0) [0.0|1] ""  Gateway_D4C7

BO_ 781 EPB_02: 4 EPB_D4
 SG_ EPB_Fehlerlampe_Gelb : 0|1@1+ (1.0,0.0) [0.0|1] ""  Gateway_D4C7
 SG_ EPB_Fehlerlampe_BKL : 1|1@1+ (1.0,0.0) [0.0|1] ""  Gateway_D4C7
 SG_ EPB_Funktionslampe : 2|1@1+ (1.0,0.0) [0.0|1] ""  Gateway_D4C7
 SG_ EPB_Texte : 3|4@1+ (1.0,0.0) [0.0|15] ""  Gateway_D4C7
 SG_ EPB_Akustik : 7|1@1+ (1.0,0.0) [0.0|1] ""  Gateway_D4C7
 SG_ EPB_Autoholdlampe : 8|1@1+ (1.0,0.0) [0.0|1] ""  Gateway_D4C7
 SG_ EPB_Bremsbelag_Warn : 9|1@1+ (1.0,0.0) [0.0|1] ""  Gateway_D4C7

BO_ 256 ESP_01: 8 Gateway_D4C7
 SG_ ESP_01_CHK : 0|8@1+ (1,0) [0|255] ""  Airbag_D4,EPB_D4,Getriebe_AL551_951_D4_C7,Getriebe_DL501_C7,Getriebe_VL381_C7,Motor_EDC17_D4,Motor_ME17_BY,Motor_MED17_SIMOS8_D4
 SG_ COUNTER : 8|4@1+ (1,0) [0|15] ""  Airbag_D4,EPB_D4,Getriebe_AL551_951_D4_C7,Getriebe_DL501_C7,Getriebe_VL381_C7,Motor_EDC17_D4,Motor_ME17_BY,Motor_MED17_SIMOS8_D4
 SG_ ASR_Moment_langsam : 12|10@1+ (1,0) [0|1021] ""  Airbag_D4,Getriebe_AL551_951_D4_C7,Getriebe_DL501_C7,Motor_EDC17_D4,Motor_ME17_BY,Motor_MED17_SIMOS8_D4
 SG_ ASR_MSR_Moment_schnell : 22|10@1+ (1,0) [0|1021] ""  Airbag_D4,Getriebe_AL551_951_D4_C7,Getriebe_DL501_C7,Motor_EDC17_D4,Motor_ME17_BY,Motor_MED17_SIMOS8_D4
 SG_ ESP_v_Signal : 32|16@1+ (0.01,0) [0.00|655.32] "Unit_KiloMeterPerHour"  Airbag_D4,Getriebe_AL551_951_D4_C7,Getriebe_DL501_C7,Getriebe_VL381_C7,Motor_EDC17_D4,Motor_ME17_BY,Motor_MED17_SIMOS8_D4,SAK_C7,SCR_C7
 SG_ ASR_Tastung_passiv : 48|1@1+ (1.0,0.0) [0.0|1] ""  Airbag_D4,Getriebe_AL551_951_D4_C7,Getriebe_DL501_C7,Getriebe_VL381_C7,Motor_EDC17_D4,Motor_ME17_BY,Motor_MED17_SIMOS8_D4
 SG_ ESP_Tastung_passiv : 49|1@1+ (1.0,0.0) [0.0|1] ""  Airbag_D4,Getriebe_AL551_951_D4_C7,Getriebe_DL501_C7,Getriebe_VL381_C7,Motor_EDC17_D4,Motor_ME17_BY,Motor_MED17_SIMOS8_D4
 SG_ ESP_Systemstatus : 50|1@1+ (1.0,0.0) [0.0|1] ""  Airbag_D4,Motor_EDC17_D4,Motor_ME17_BY,Motor_MED17_SIMOS8_D4
 SG_ ASR_Schalteingriff : 51|2@1+ (1.0,0.0) [0.0|3] ""  Airbag_D4,Getriebe_AL551_951_D4_C7,Getriebe_DL501_C7,Getriebe_VL381_C7
 SG_ OBD_Schlechtweg : 53|1@1+ (1.0,0.0) [0.0|1] ""  Motor_ME17_BY,Motor_MED17_SIMOS8_D4
 SG_ OBD_QBit_Schlechtweg : 54|1@1+ (1.0,0.0) [0.0|1] ""  Motor_ME17_BY,Motor_MED17_SIMOS8_D4
 SG_ ESP_QBit_v_Signal : 55|1@1+ (1.0,0.0) [0.0|1] ""  Airbag_D4,Getriebe_AL551_951_D4_C7,Getriebe_DL501_C7,Getriebe_VL381_C7,Motor_EDC17_D4,Motor_ME17_BY,Motor_MED17_SIMOS8_D4,SCR_C7
 SG_ ABS_Bremsung : 56|1@1+ (1.0,0.0) [0.0|1] ""  Airbag_D4,EPB_D4,Getriebe_AL551_951_D4_C7,Getriebe_DL501_C7,Getriebe_VL381_C7,Motor_EDC17_D4,Motor_ME17_BY,Motor_MED17_SIMOS8_D4
 SG_ ASR_Anf : 57|1@1+ (1.0,0.0) [0.0|1] ""  Airbag_D4,Getriebe_AL551_951_D4_C7,Getriebe_DL501_C7,Getriebe_VL381_C7,Motor_EDC17_D4,Motor_ME17_BY,Motor_MED17_SIMOS8_D4
 SG_ MSR_Anf : 58|1@1+ (1.0,0.0) [0.0|1] ""  Airbag_D4,Getriebe_VL381_C7,Motor_EDC17_D4,Motor_ME17_BY,Motor_MED17_SIMOS8_D4
 SG_ EBV_Eingriff : 59|1@1+ (1.0,0.0) [0.0|1] ""  Airbag_D4,Getriebe_AL551_951_D4_C7,Getriebe_DL501_C7,Motor_EDC17_D4,Motor_ME17_BY,Motor_MED17_SIMOS8_D4
 SG_ EDS_Eingriff : 60|1@1+ (1.0,0.0) [0.0|1] ""  Airbag_D4,Getriebe_AL551_951_D4_C7,Getriebe_DL501_C7,Getriebe_VL381_C7,Motor_EDC17_D4,Motor_ME17_BY,Motor_MED17_SIMOS8_D4
 SG_ ESP_Eingriff : 61|1@1+ (1.0,0.0) [0.0|1] ""  Airbag_D4,Getriebe_AL551_951_D4_C7,Getriebe_DL501_C7,Getriebe_VL381_C7,Motor_EDC17_D4,Motor_ME17_BY,Motor_MED17_SIMOS8_D4
 SG_ ESP_ASP : 62|1@1+ (1.0,0.0) [0.0|1] ""  Motor_EDC17_D4,Motor_ME17_BY,Motor_MED17_SIMOS8_D4
 SG_ ESP_KD_Fehler : 63|1@1+ (1.0,0.0) [0.0|1] ""  Vector__XXX

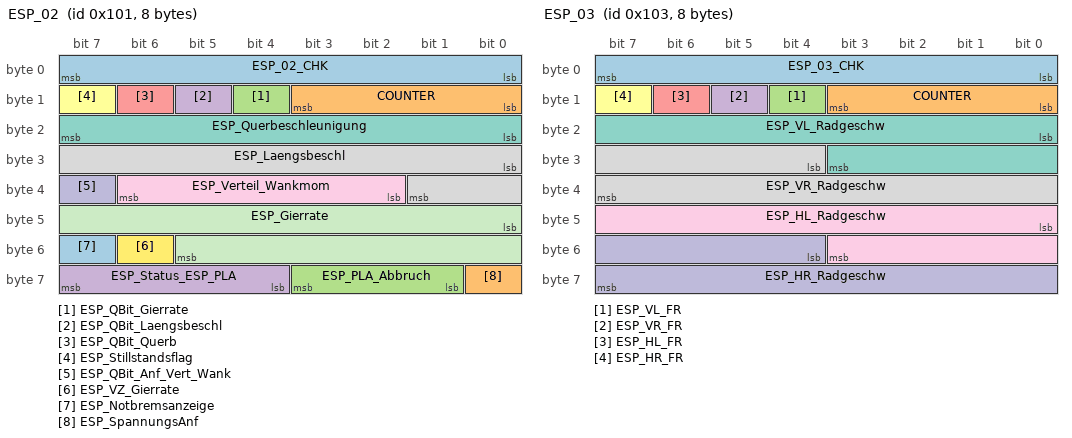
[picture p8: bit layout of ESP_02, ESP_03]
BO_ 257 ESP_02: 8 Gateway_D4C7
 SG_ ESP_02_CHK : 0|8@1+ (1,0) [0|255] ""  Airbag_D4,EPB_D4,Getriebe_AL551_951_D4_C7,Getriebe_DL501_C7,Getriebe_VL381_C7,Motor_EDC17_D4,Motor_ME17_BY,Motor_MED17_SIMOS8_D4
 SG_ COUNTER : 8|4@1+ (1,0) [0|15] ""  Airbag_D4,EPB_D4,Getriebe_AL551_951_D4_C7,Getriebe_DL501_C7,Getriebe_VL381_C7,Motor_EDC17_D4,Motor_ME17_BY,Motor_MED17_SIMOS8_D4
 SG_ ESP_QBit_Gierrate : 12|1@1+ (1.0,0.0) [0.0|1] ""  Airbag_D4
 SG_ ESP_QBit_Laengsbeschl : 13|1@1+ (1.0,0.0) [0.0|1] ""  Airbag_D4,EPB_D4,Getriebe_AL551_951_D4_C7,Getriebe_DL501_C7,Getriebe_VL381_C7,Motor_EDC17_D4,Motor_ME17_BY,Motor_MED17_SIMOS8_D4
 SG_ ESP_QBit_Querb : 14|1@1+ (1.0,0.0) [0.0|1] ""  Airbag_D4,Getriebe_AL551_951_D4_C7,Getriebe_DL501_C7,Motor_EDC17_D4,Motor_ME17_BY,Motor_MED17_SIMOS8_D4
 SG_ ESP_Stillstandsflag : 15|1@1+ (1.0,0.0) [0.0|1] ""  Motor_EDC17_D4,Motor_ME17_BY,Motor_MED17_SIMOS8_D4
 SG_ ESP_Querbeschleunigung : 16|8@1+ (0.01,-1.27) [-1.27|1.27] "Unit_ForceOfGravi"  Airbag_D4,Getriebe_AL551_951_D4_C7,Getriebe_DL501_C7,Motor_EDC17_D4,Motor_ME17_BY,Motor_MED17_SIMOS8_D4
 SG_ ESP_Laengsbeschl : 24|10@1+ (0.03125,-16) [-16.00000|15.90625] "Unit_MeterPerSeconSquar"  Airbag_D4,EPB_D4,Getriebe_AL551_951_D4_C7,Getriebe_DL501_C7,Getriebe_VL381_C7,Motor_EDC17_D4,Motor_ME17_BY,Motor_MED17_SIMOS8_D4
 SG_ ESP_Verteil_Wankmom : 34|5@1+ (0.1,-1) [-1.0|1.0] ""  Vector__XXX
 SG_ ESP_QBit_Anf_Vert_Wank : 39|1@1+ (1.0,0.0) [0.0|1] ""  Vector__XXX
 SG_ ESP_Gierrate : 40|14@1+ (0.01,0) [0.00|163.82] "Unit_DegreOfArcPerSecon"  Airbag_D4
 SG_ ESP_VZ_Gierrate : 54|1@1+ (1.0,0.0) [0.0|1] ""  Airbag_D4
 SG_ ESP_Notbremsanzeige : 55|1@1+ (1.0,0.0) [0.0|1] ""  Vector__XXX
 SG_ ESP_SpannungsAnf : 56|1@1+ (1.0,0.0) [0.0|1] ""  Vector__XXX
 SG_ ESP_PLA_Abbruch : 57|3@1+ (1.0,0.0) [0.0|7] ""  Vector__XXX
 SG_ ESP_Status_ESP_PLA : 60|4@1+ (1.0,0.0) [0.0|15] ""  Vector__XXX

BO_ 259 ESP_03: 8 Gateway_D4C7
 SG_ ESP_03_CHK : 0|8@1+ (1,0) [0|255] ""  Airbag_D4,EPB_D4,Getriebe_AL551_951_D4_C7,Getriebe_DL501_C7,Getriebe_VL381_C7,LWS_D4,Motor_EDC17_D4,Motor_ME17_BY,Motor_MED17_SIMOS8_D4,SCU_D4
 SG_ COUNTER : 8|4@1+ (1,0) [0|15] ""  Airbag_D4,EPB_D4,Getriebe_AL551_951_D4_C7,Getriebe_DL501_C7,Getriebe_VL381_C7,LWS_D4,Motor_EDC17_D4,Motor_ME17_BY,Motor_MED17_SIMOS8_D4,SCU_D4
 SG_ ESP_VL_FR : 12|1@1+ (1.0,0.0) [0.0|1] ""  Airbag_D4,EPB_D4,Getriebe_AL551_951_D4_C7,Getriebe_DL501_C7,Motor_EDC17_D4,Motor_ME17_BY,Motor_MED17_SIMOS8_D4,SCU_D4
 SG_ ESP_VR_FR : 13|1@1+ (1.0,0.0) [0.0|1] ""  Airbag_D4,EPB_D4,Getriebe_AL551_951_D4_C7,Getriebe_DL501_C7,Motor_EDC17_D4,Motor_ME17_BY,Motor_MED17_SIMOS8_D4,SCU_D4
 SG_ ESP_HL_FR : 14|1@1+ (1.0,0.0) [0.0|1] ""  Airbag_D4,EPB_D4,Getriebe_AL551_951_D4_C7,Getriebe_DL501_C7,Motor_EDC17_D4,Motor_ME17_BY,Motor_MED17_SIMOS8_D4,SCU_D4
 SG_ ESP_HR_FR : 15|1@1+ (1.0,0.0) [0.0|1] ""  Airbag_D4,EPB_D4,Getriebe_AL551_951_D4_C7,Getriebe_DL501_C7,Motor_EDC17_D4,Motor_ME17_BY,Motor_MED17_SIMOS8_D4,SCU_D4
 SG_ ESP_VL_Radgeschw : 16|12@1+ (0.1,0) [0.0|409.2] "Unit_KiloMeterPerHour"  Airbag_D4,EPB_D4,Getriebe_AL551_951_D4_C7,Getriebe_DL501_C7,Getriebe_VL381_C7,LWS_D4,SCU_D4
 SG_ ESP_VR_Radgeschw : 28|12@1+ (0.1,0) [0.0|409.2] "Unit_KiloMeterPerHour"  Airbag_D4,EPB_D4,Getriebe_AL551_951_D4_C7,Getriebe_DL501_C7,Getriebe_VL381_C7,LWS_D4,SCU_D4
 SG_ ESP_HL_Radgeschw : 40|12@1+ (0.1,0) [0.0|409.2] "Unit_KiloMeterPerHour"  Airbag_D4,EPB_D4,Getriebe_AL551_951_D4_C7,Getriebe_DL501_C7,Getriebe_VL381_C7,LWS_D4,SCU_D4
 SG_ ESP_HR_Radgeschw : 52|12@1+ (0.1,0) [0.0|409.2] "Unit_KiloMeterPerHour"  Airbag_D4,EPB_D4,Getriebe_AL551_951_D4_C7,Getriebe_DL501_C7,Getriebe_VL381_C7,LWS_D4,SCU_D4

BO_ 776 ESP_04: 8 Gateway_D4C7
 SG_ ESP_Meldungen : 0|3@1+ (1.0,0.0) [0.0|7] ""  Vector__XXX
 SG_ ESP_HDC_FktLampe : 3|1@1+ (1.0,0.0) [0.0|1] ""  Vector__XXX
 SG_ ESP_Lampe : 4|1@1+ (1.0,0.0) [0.0|1] ""  Vector__XXX
 SG_ ABS_Lampe : 5|1@1+ (1.0,0.0) [0.0|1] ""  Vector__XXX
 SG_ BK_Lampe : 6|1@1+ (1.0,0.0) [0.0|1] ""  Vector__XXX
 SG_ ESP_Akustik : 7|2@1+ (1.0,0.0) [0.0|3] ""  Vector__XXX
 SG_ ESP_Diagnose : 9|1@1+ (1.0,0.0) [0.0|1] ""  SCU_D4
 SG_ ESP_Textanzeigen_02 : 10|5@1+ (1.0,0.0) [0.0|31] ""  Vector__XXX
 SG_ ESP_Off_Lampe : 15|1@1+ (1.0,0.0) [0.0|1] ""  Vector__XXX
 SG_ ESP_m_Raddrehz : 16|15@1+ (0.002,0) [0.000|65.278] "Unit_Hertz"  Vector__XXX
 SG_ ESP_ASR_Lampe : 31|1@1+ (1.0,0.0) [0.0|1] ""  Vector__XXX
 SG_ ESP_Wegimp_VA : 32|11@1+ (1,0) [0|2047] ""  Vector__XXX
 SG_ ESP_Fehlerstatus_Wegimp : 43|1@1+ (1.0,0.0) [0.0|1] ""  Vector__XXX
 SG_ ESP_Wegimp_Ueberlauf : 44|1@1+ (1.0,0.0) [0.0|1] ""  Vector__XXX
 SG_ ESP_QBit_Wegimp_VA : 45|1@1+ (1.0,0.0) [0.0|1] ""  Vector__XXX
 SG_ ESP_Displaywarnungen : 46|2@1+ (1.0,0.0) [0.0|3] ""  Vector__XXX
 SG_ ESP_HDC_Regelgeschw : 48|7@1+ (0.32,0) [0.32|39.68] "Unit_KiloMeterPerHour"  Vector__XXX
 SG_ ESP_BKV_Warnung : 55|1@1+ (1.0,0.0) [0.0|1] ""  Vector__XXX
 SG_ ESP_Zaehnezahl : 56|8@1+ (1,0) [0|255] ""  Vector__XXX

BO_ 262 ESP_05: 8 Gateway_D4C7
 SG_ ESP_05_CHK : 0|8@1+ (1,0) [0|255] ""  EPB_D4,Getriebe_AL551_951_D4_C7,Getriebe_DL501_C7,Getriebe_VL381_C7,Motor_EDC17_D4,Motor_ME17_BY,Motor_MED17_SIMOS8_D4,SCU_D4
 SG_ COUNTER : 8|4@1+ (1,0) [0|15] ""  EPB_D4,Getriebe_AL551_951_D4_C7,Getriebe_DL501_C7,Getriebe_VL381_C7,Motor_EDC17_D4,Motor_ME17_BY,Motor_MED17_SIMOS8_D4,SCU_D4
 SG_ ESP_QBit_Bremsdruck : 12|1@1+ (1.0,0.0) [0.0|1] ""  EPB_D4,Getriebe_AL551_951_D4_C7,Getriebe_DL501_C7,Motor_EDC17_D4,Motor_ME17_BY,Motor_MED17_SIMOS8_D4
 SG_ ESP_QBit_Fahrer_bremst : 13|1@1+ (1.0,0.0) [0.0|1] ""  Motor_EDC17_D4,Motor_ME17_BY,Motor_MED17_SIMOS8_D4
 SG_ ESP_Schwelle_Unterdruck : 14|2@1+ (1.0,0.0) [0.0|3] ""  Vector__XXX
 SG_ ESP_Bremsdruck : 16|10@1+ (0.3,-30) [-30.0|276.6] "Unit_Bar"  EPB_D4,Getriebe_AL551_951_D4_C7,Getriebe_DL501_C7,Motor_EDC17_D4,Motor_ME17_BY,Motor_MED17_SIMOS8_D4
 SG_ ESP_Fahrer_bremst : 26|1@1+ (1.0,0.0) [0.0|1] ""  Motor_EDC17_D4,Motor_ME17_BY,Motor_MED17_SIMOS8_D4
 SG_ ESP_Verz_TSK_aktiv : 27|1@1+ (1.0,0.0) [0.0|1] ""  Getriebe_AL551_951_D4_C7,Motor_EDC17_D4,Motor_ME17_BY,Motor_MED17_SIMOS8_D4
 SG_ ESP_Lenkeingriff_ADS : 28|1@1+ (1.0,0.0) [0.0|1] ""  Motor_EDC17_D4,Motor_ME17_BY,Motor_MED17_SIMOS8_D4,SCU_D4
 SG_ ESP_Konsistenz_TSK : 29|1@1+ (1.0,0.0) [0.0|1] ""  Motor_EDC17_D4,Motor_ME17_BY,Motor_MED17_SIMOS8_D4
 SG_ ESP_Bremsruck_AWV2 : 30|1@1+ (1.0,0.0) [0.0|1] ""  Vector__XXX
 SG_ ESP_Konsistenz_AWV2 : 31|1@1+ (1.0,0.0) [0.0|1] ""  Vector__XXX
 SG_ ECD_Fehler : 32|1@1+ (1.0,0.0) [0.0|1] ""  Motor_EDC17_D4,Motor_ME17_BY,Motor_MED17_SIMOS8_D4
 SG_ ECD_nicht_verfuegbar : 33|1@1+ (1.0,0.0) [0.0|1] ""  Motor_EDC17_D4,Motor_ME17_BY,Motor_MED17_SIMOS8_D4
 SG_ ESP_Status_Bremsentemp : 34|1@1+ (1.0,0.0) [0.0|1] ""  Motor_EDC17_D4,Motor_ME17_BY,Motor_MED17_SIMOS8_D4
 SG_ ESP_Autohold_Standby : 35|1@1+ (1.0,0.0) [0.0|1] ""  EPB_D4,Getriebe_AL551_951_D4_C7
 SG_ ESP_HDC_Standby : 36|1@1+ (1.0,0.0) [0.0|1] ""  Vector__XXX
 SG_ ESP_HBA_aktiv : 37|1@1+ (1.0,0.0) [0.0|1] ""  Vector__XXX
 SG_ ESP_Prefill_ausgeloest : 38|1@1+ (1.0,0.0) [0.0|1] ""  Vector__XXX
 SG_ ESP_Rueckwaertsfahrt_erkannt : 39|1@1+ (1.0,0.0) [0.0|1] ""  Motor_EDC17_D4,Motor_ME17_BY,Motor_MED17_SIMOS8_D4
 SG_ ESP_Status_Anfahrhilfe : 40|1@1+ (1.0,0.0) [0.0|1] ""  Motor_EDC17_D4,Motor_MED17_SIMOS8_D4
 SG_ ESP_HDC_aktiv : 41|1@1+ (1.0,0.0) [0.0|1] ""  Vector__XXX
 SG_ ESP_StartStopp_Info : 42|2@1+ (1.0,0.0) [0.0|3] ""  Motor_EDC17_D4,Motor_ME17_BY,Motor_MED17_SIMOS8_D4
 SG_ ESP_Eingr_HL : 44|1@1+ (1.0,0.0) [0.0|1] ""  Vector__XXX
 SG_ ESP_Eingr_HR : 45|1@1+ (1.0,0.0) [0.0|1] ""  Vector__XXX
 SG_ ESP_Eingr_VL : 46|1@1+ (1.0,0.0) [0.0|1] ""  Vector__XXX
 SG_ ESP_Eingr_VR : 47|1@1+ (1.0,0.0) [0.0|1] ""  Vector__XXX
 SG_ ESP_BKV_Unterdruck : 48|8@1+ (4,0) [0|1012] "Unit_MilliBar"  Motor_EDC17_D4,Motor_ME17_BY,Motor_MED17_SIMOS8_D4
 SG_ ESP_Autohold_aktiv : 56|1@1+ (1.0,0.0) [0.0|1] ""  EPB_D4,Getriebe_AL551_951_D4_C7,Getriebe_DL501_C7,Getriebe_VL381_C7,Motor_EDC17_D4,Motor_ME17_BY,Motor_MED17_SIMOS8_D4
 SG_ ESP_FStatus_Anfahrhilfe : 57|1@1+ (1.0,0.0) [0.0|1] ""  Vector__XXX
 SG_ ESP_Verz_EPB_aktiv : 58|1@1+ (1.0,0.0) [0.0|1] ""  EPB_D4,Getriebe_AL551_951_D4_C7
 SG_ ECD_Bremslicht : 59|1@1+ (1.0,0.0) [0.0|1] ""  Motor_EDC17_D4,Motor_ME17_BY,Motor_MED17_SIMOS8_D4
 SG_ ESP_Verzoeg_EPB_verf : 60|1@1+ (1.0,0.0) [0.0|1] ""  EPB_D4
 SG_ ESP_Status_Bremsdruck : 61|1@1+ (1.0,0.0) [0.0|1] ""  EPB_D4,Motor_EDC17_D4,Motor_ME17_BY,Motor_MED17_SIMOS8_D4
 SG_ ESP_Anforderung_EPB : 62|2@1+ (1.0,0.0) [0.0|3] ""  EPB_D4

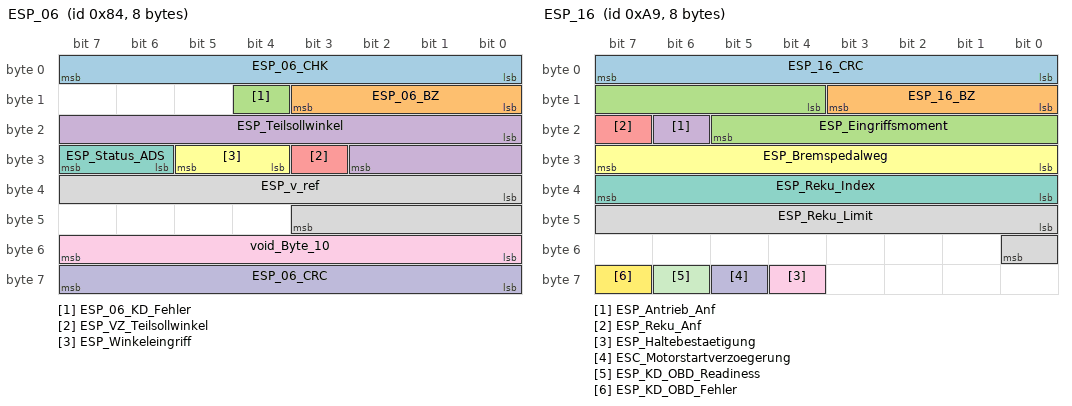
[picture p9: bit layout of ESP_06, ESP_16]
BO_ 132 ESP_06: 8 ESP_D4
 SG_ ESP_06_CHK : 0|8@1+ (1,0) [0|255] ""  SCU_D4
 SG_ ESP_06_BZ : 8|4@1+ (1,0) [0|15] ""  Airbag_D4,SCU_D4
 SG_ ESP_06_KD_Fehler : 12|1@1+ (1.0,0.0) [0.0|1] ""  Gateway_D4C7
 SG_ ESP_Teilsollwinkel : 16|11@1+ (0.1,0) [0.0|204.7] "Unit_DegreOfArc"  SCU_D4
 SG_ ESP_VZ_Teilsollwinkel : 27|1@1+ (1.0,0.0) [0.0|1] ""  SCU_D4
 SG_ ESP_Winkeleingriff : 28|2@1+ (1.0,0.0) [0.0|3] ""  SCU_D4
 SG_ ESP_Status_ADS : 30|2@1+ (1.0,0.0) [0.0|3] ""  SCU_D4
 SG_ ESP_v_ref : 32|12@1+ (0.125,0) [0.000|511.500] "Unit_KiloMeterPerHour"  Airbag_D4
 SG_ void_Byte_10 : 48|8@1+ (1,0) [0|255] ""  Vector__XXX
 SG_ ESP_06_CRC : 56|8@1+ (1,0) [0|255] ""  Airbag_D4,SCU_D4

BO_ 914 ESP_07_FR: 8 Gateway_D4C7
 SG_ ESP_07_CHK : 0|8@1+ (1,0) [0|255] ""  LWS_D4,Motor_EDC17_D4,Motor_ME17_BY,Motor_MED17_SIMOS8_D4
 SG_ ESP_07_BZ : 8|4@1+ (1,0) [0|15] ""  LWS_D4,Motor_EDC17_D4,Motor_ME17_BY,Motor_MED17_SIMOS8_D4
 SG_ ESP_ACC_LDE : 12|1@1+ (1.0,0.0) [0.0|1] ""  Vector__XXX
 SG_ ESP_Quattro_Antrieb : 13|1@1+ (1.0,0.0) [0.0|1] ""  Vector__XXX
 SG_ ESP_Codierung_ADS : 14|2@1+ (1.0,0.0) [0.0|3] ""  LWS_D4
 SG_ ESP_RTA_HL : 16|8@1+ (0.048828125,-6.20117) [-6.201170000|6.152345625] "Unit_PerCent"  Vector__XXX
 SG_ ESP_RTA_HR : 24|8@1+ (0.048828125,-6.20117) [-6.201170000|6.152345625] "Unit_PerCent"  Vector__XXX
 SG_ ESP_RTA_VR : 32|8@1+ (0.048828125,-6.20117) [-6.201170000|6.152345625] "Unit_PerCent"  Vector__XXX
 SG_ OBD_Fehler_Radsensor_HL : 40|4@1+ (1.0,0.0) [0.0|15] ""  Motor_EDC17_D4,Motor_ME17_BY,Motor_MED17_SIMOS8_D4
 SG_ OBD_Fehler_Radsensor_HR : 44|4@1+ (1.0,0.0) [0.0|15] ""  Motor_EDC17_D4,Motor_ME17_BY,Motor_MED17_SIMOS8_D4
 SG_ OBD_Fehler_Radsensor_VL : 48|4@1+ (1.0,0.0) [0.0|15] ""  Motor_EDC17_D4,Motor_ME17_BY,Motor_MED17_SIMOS8_D4
 SG_ OBD_Fehler_Radsensor_VR : 52|4@1+ (1.0,0.0) [0.0|15] ""  Motor_EDC17_D4,Motor_ME17_BY,Motor_MED17_SIMOS8_D4
 SG_ ESP_Qualifizierung_Antriebsart : 56|1@1+ (1.0,0.0) [0.0|1] ""  Vector__XXX
 SG_ ESP_Offroad_Modus : 57|1@1+ (1.0,0.0) [0.0|1] ""  Vector__XXX
 SG_ ESP_MKB_ausloesbar : 58|1@1+ (1.0,0.0) [0.0|1] ""  Vector__XXX
 SG_ ESP_MKB_Status : 59|1@1+ (1.0,0.0) [0.0|1] ""  Vector__XXX
 SG_ ESP_CM_Variante : 60|1@1+ (1.0,0.0) [0.0|1] ""  Vector__XXX
 SG_ ESP_OBD_Status : 61|1@1+ (1.0,0.0) [0.0|1] ""  Vector__XXX

BO_ 169 ESP_16: 8 Gateway
 SG_ ESP_16_CRC : 0|8@1+ (1,0) [0|255] ""  Motor_MLB_C7_PHEV,Motor_MLB_D4_C7_Hybrid
 SG_ ESP_16_BZ : 8|4@1+ (1,0) [0|15] ""  Motor_MLB_C7_PHEV,Motor_MLB_D4_C7_Hybrid
 SG_ ESP_Eingriffsmoment : 12|10@1+ (1,-509) [-509|509] ""  Motor_MLB_C7_PHEV,Motor_MLB_D4_C7_Hybrid
 SG_ ESP_Antrieb_Anf : 22|1@1+ (1,0) [0|1] "" Vector__XXX
 SG_ ESP_Reku_Anf : 23|1@1+ (1,0) [0|1] "" Vector__XXX
 SG_ ESP_Bremspedalweg : 24|8@1+ (0.4,-0.4) [0|100] "Unit_PerCent" Vector__XXX
 SG_ ESP_Reku_Index : 32|8@1+ (1,0) [0|255] ""  Motor_MLB_C7_PHEV,Motor_MLB_D4_C7_Hybrid
 SG_ ESP_Reku_Limit : 40|9@1+ (1,-509) [-509|0] "Unit_NewtoMeter" Vector__XXX
 SG_ ESP_Haltebestaetigung : 60|1@1+ (1,0) [0|1] ""  Motor_MLB_AU64_AU57_Diesel,Motor_MLB_BY_Otto,Motor_MLB_C7_PHEV,Motor_MLB_D4_C7_Hybrid,Motor_MLB_D4_C7_Otto
 SG_ ESC_Motorstartverzoegerung : 61|1@1+ (1,0) [0|1] ""  Motor_MLB_AU64_AU57_Diesel,Motor_MLB_BY_Otto,Motor_MLB_C7_PHEV,Motor_MLB_D4_C7_Hybrid,Motor_MLB_D4_C7_Otto
 SG_ ESP_KD_OBD_Readiness : 62|1@1+ (1,0) [0|1] ""  Motor_MLB_C7_PHEV,Motor_MLB_D4_C7_Hybrid
 SG_ ESP_KD_OBD_Fehler : 63|1@1+ (1,0) [0|1] ""  Motor_MLB_C7_PHEV,Motor_MLB_D4_C7_Hybrid

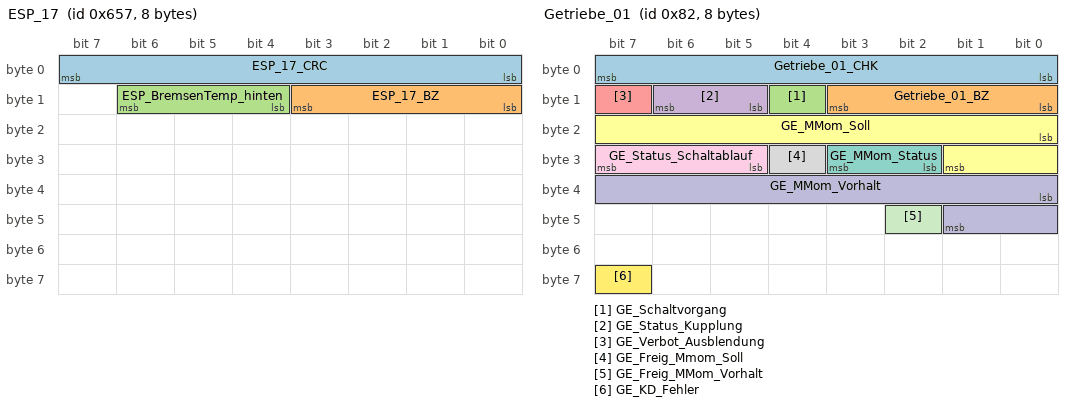
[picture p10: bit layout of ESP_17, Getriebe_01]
BO_ 1623 ESP_17: 8 ESP_D4
 SG_ ESP_17_CRC : 0|8@1+ (1,0) [0|255] ""  EPB_D4
 SG_ ESP_17_BZ : 8|4@1+ (1,0) [0|15] ""  EPB_D4
 SG_ ESP_BremsenTemp_hinten : 12|3@1+ (1.0,0.0) [0.0|7] ""  EPB_D4

BO_ 924 Gateway_05: 8 Gateway_D4C7
 SG_ BCM1_02_alt : 0|1@1+ (1.0,0.0) [0.0|1] ""  Motor_EDC17_D4,Motor_ME17_BY,Motor_MED17_SIMOS8_D4
 SG_ Wischer_01_alt : 1|1@1+ (1.0,0.0) [0.0|1] ""  Motor_EDC17_D4,Motor_ME17_BY,Motor_MED17_SIMOS8_D4
 SG_ Klima_02_alt : 2|1@1+ (1.0,0.0) [0.0|1] ""  Vector__XXX
 SG_ BCM1_01_alt : 3|1@1+ (1.0,0.0) [0.0|1] ""  EPB_D4,Motor_EDC17_D4,Motor_ME17_BY,Motor_MED17_SIMOS8_D4
 SG_ ESP_07_alt : 4|1@1+ (1.0,0.0) [0.0|1] ""  Airbag_D4,Motor_EDC17_D4,Motor_ME17_BY,Motor_MED17_SIMOS8_D4
 SG_ TSG_BT_1_alt : 5|1@1+ (1.0,0.0) [0.0|1] ""  Motor_EDC17_D4,Motor_ME17_BY,Motor_MED17_SIMOS8_D4
 SG_ TSG_HL_1_alt : 6|1@1+ (1.0,0.0) [0.0|1] ""  Motor_EDC17_D4,Motor_ME17_BY,Motor_MED17_SIMOS8_D4
 SG_ TSG_HR_1_alt : 7|1@1+ (1.0,0.0) [0.0|1] ""  Motor_EDC17_D4,Motor_ME17_BY,Motor_MED17_SIMOS8_D4
 SG_ Motor_02_alt : 8|1@1+ (1.0,0.0) [0.0|1] ""  Vector__XXX
 SG_ Klima_Sensor_02_alt : 9|1@1+ (1.0,0.0) [0.0|1] ""  Motor_EDC17_D4,Motor_ME17_BY,Motor_MED17_SIMOS8_D4,SCR_C7
 SG_ TSG_FT_1_alt : 10|1@1+ (1.0,0.0) [0.0|1] ""  Getriebe_AL551_951_D4_C7,Motor_EDC17_D4,Motor_ME17_BY,Motor_MED17_SIMOS8_D4
 SG_ Motor_05_alt : 11|1@1+ (1.0,0.0) [0.0|1] ""  Vector__XXX
 SG_ QSP_01_alt : 12|1@1+ (1.0,0.0) [0.0|1] ""  Motor_EDC17_D4,Motor_ME17_BY,Motor_MED17_SIMOS8_D4
 SG_ Parkhilfe_01_alt : 13|1@1+ (1.0,0.0) [0.0|1] ""  Motor_EDC17_D4,Motor_ME17_BY,Motor_MED17_SIMOS8_D4
 SG_ Fahrwerk_02_alt : 14|1@1+ (1.0,0.0) [0.0|1] ""  Motor_EDC17_D4,Motor_ME17_BY,Motor_MED17_SIMOS8_D4
 SG_ GW_05_va_27 : 15|1@1+ (1,0) [0|1] ""  Vector__XXX
 SG_ BCM1_MH_WIV_Schalter : 16|1@1+ (1.0,0.0) [0.0|1] ""  Motor_EDC17_D4,Motor_ME17_BY,Motor_MED17_SIMOS8_D4
 SG_ Wischer_vorne_aktiv : 17|1@1+ (1.0,0.0) [0.0|1] ""  Motor_EDC17_D4,Motor_ME17_BY,Motor_MED17_SIMOS8_D4
 SG_ BCM1_Rueckfahrlicht_Schalter : 18|1@1+ (1.0,0.0) [0.0|1] ""  EPB_D4,Motor_EDC17_D4,Motor_ME17_BY,Motor_MED17_SIMOS8_D4
 SG_ MO_Status_Normalbetrieb_01 : 19|1@1+ (1.0,0.0) [0.0|1] ""  Vector__XXX
 SG_ KL_Zuheizer_Freigabe : 20|1@1+ (1.0,0.0) [0.0|1] ""  Vector__XXX
 SG_ BCM1_Vorwaertsgang_eingelegt : 21|1@1+ (1.0,0.0) [0.0|1] ""  EPB_D4
 SG_ ESP_Codierung_ADS : 22|2@1+ (1.0,0.0) [0.0|3] ""  Airbag_D4,Motor_EDC17_D4,Motor_ME17_BY,Motor_MED17_SIMOS8_D4
 SG_ QSP_StartStopp_Info : 24|2@1+ (1.0,0.0) [0.0|3] ""  Motor_EDC17_D4,Motor_ME17_BY,Motor_MED17_SIMOS8_D4
 SG_ FA_StartStopp_Info : 26|2@1+ (1.0,0.0) [0.0|3] ""  Motor_EDC17_D4,Motor_ME17_BY,Motor_MED17_SIMOS8_D4
 SG_ PH_StartStopp_Info : 28|2@1+ (1.0,0.0) [0.0|3] ""  Motor_EDC17_D4,Motor_ME17_BY,Motor_MED17_SIMOS8_D4
 SG_ KL_Beschlagsgefahr : 30|1@1+ (1.0,0.0) [0.0|1] ""  Vector__XXX
 SG_ BCM1_GLW_Fernlicht_Anf : 31|1@1+ (1.0,0.0) [0.0|1] ""  Vector__XXX
 SG_ BCM1_RFahrlicht_Fzg_Anf : 32|1@1+ (1.0,0.0) [0.0|1] ""  Vector__XXX
 SG_ FT_Tuer_geoeffnet : 33|1@1+ (1.0,0.0) [0.0|1] ""  Getriebe_AL551_951_D4_C7,Motor_EDC17_D4,Motor_ME17_BY,Motor_MED17_SIMOS8_D4
 SG_ MO_Handshake_STH : 34|1@1+ (1.0,0.0) [0.0|1] ""  Vector__XXX
 SG_ FT_Sperrklinke : 35|1@1+ (1.0,0.0) [0.0|1] ""  Motor_EDC17_D4,Motor_ME17_BY,Motor_MED17_SIMOS8_D4
 SG_ BCM1_OBD_FStatus_ATemp : 36|4@1+ (1.0,0.0) [0.0|15] ""  Airbag_D4,Motor_EDC17_D4,Motor_ME17_BY,Motor_MED17_SIMOS8_D4,SCR_C7
 SG_ BCM1_Aussen_Temp_ungef : 40|8@1+ (0.5,-50) [-50.0|76.0] "Unit_DegreCelsi"  Airbag_D4,Motor_EDC17_D4,Motor_ME17_BY,Motor_MED17_SIMOS8_D4,SCR_C7
 SG_ BCM1_Oeldruck_Schalter : 48|1@1+ (1.0,0.0) [0.0|1] ""  Vector__XXX
 SG_ BCM1_Oeldruck_Schalter_2 : 49|1@1+ (1.0,0.0) [0.0|1] ""  Vector__XXX
 SG_ BT_Tuer_geoeffnet : 50|1@1+ (1.0,0.0) [0.0|1] ""  Motor_EDC17_D4,Motor_ME17_BY,Motor_MED17_SIMOS8_D4
 SG_ HL_Tuer_geoeffnet : 51|1@1+ (1.0,0.0) [0.0|1] ""  Motor_EDC17_D4,Motor_ME17_BY,Motor_MED17_SIMOS8_D4
 SG_ HR_Tuer_geoeffnet : 52|1@1+ (1.0,0.0) [0.0|1] ""  Motor_EDC17_D4,Motor_ME17_BY,Motor_MED17_SIMOS8_D4
 SG_ BCM1_Adaptive_Lichtvert_Anf : 53|1@1+ (1.0,0.0) [0.0|1] ""  Vector__XXX
 SG_ BCM1_Gleitende_Leuchtw_Anf : 54|1@1+ (1.0,0.0) [0.0|1] ""  Vector__XXX
 SG_ BCM1_Schalter_StartStopp : 55|1@1+ (1.0,0.0) [0.0|1] ""  Motor_EDC17_D4,Motor_ME17_BY,Motor_MED17_SIMOS8_D4
 SG_ ESP_Offroad_Modus : 56|1@1+ (1.0,0.0) [0.0|1] ""  Vector__XXX
 SG_ MO_Freig_Reku : 57|2@1+ (1.0,0.0) [0.0|3] ""  Vector__XXX

BO_ 1604 Gateway_11: 8 Gateway_D4C7
 SG_ SMLS_01_alt : 0|1@1+ (1.0,0.0) [0.0|1] ""  Motor_EDC17_D4,Motor_ME17_BY,Motor_MED17_SIMOS8_D4
 SG_ HUD_01_alt : 1|1@1+ (1,0) [0|1] ""  Vector__XXX
 SG_ BCM1_01_alt : 2|1@1+ (1.0,0.0) [0.0|1] ""  Vector__XXX
 SG_ BCM1_02_alt : 3|1@1+ (1.0,0.0) [0.0|1] ""  Motor_EDC17_D4,Motor_ME17_BY,Motor_MED17_SIMOS8_D4
 SG_ BCM2_02_alt : 4|1@1+ (1.0,0.0) [0.0|1] ""  Getriebe_VL381_C7
 SG_ HYB_Anf_E_Mode_alt : 5|1@1+ (1.0,0.0) [0.0|1] ""  Vector__XXX
 SG_ BCM1_04_alt : 6|1@1+ (1,0) [0|1] ""  Vector__XXX
 SG_ ESP_04_alt : 7|1@1+ (1.0,0.0) [0.0|1] ""  SCU_D4
 SG_ GW_11_va_20 : 8|1@1+ (1,0) [0|1] ""  Vector__XXX
 SG_ GW_11_va_21 : 9|1@1+ (1,0) [0|1] ""  Vector__XXX
 SG_ GW_11_va_22 : 10|1@1+ (1,0) [0|1] ""  Vector__XXX
 SG_ GW_11_va_23 : 11|1@1+ (1,0) [0|1] ""  Vector__XXX
 SG_ GW_11_va_24 : 12|1@1+ (1,0) [0|1] ""  Vector__XXX
 SG_ GW_11_va_25 : 13|1@1+ (1,0) [0|1] ""  Vector__XXX
 SG_ GW_11_va_26 : 14|1@1+ (1,0) [0|1] ""  Vector__XXX
 SG_ GW_11_va_27 : 15|1@1+ (1,0) [0|1] ""  Vector__XXX
 SG_ BH_Blinker_li : 16|1@1+ (1.0,0.0) [0.0|1] ""  Motor_EDC17_D4,Motor_ME17_BY,Motor_MED17_SIMOS8_D4
 SG_ BH_Blinker_re : 17|1@1+ (1.0,0.0) [0.0|1] ""  Motor_EDC17_D4,Motor_ME17_BY,Motor_MED17_SIMOS8_D4
 SG_ BM_Autobahn : 18|1@1+ (1.0,0.0) [0.0|1] ""  Vector__XXX
 SG_ BH_Fernlicht : 19|1@1+ (1.0,0.0) [0.0|1] ""  Vector__XXX
 SG_ BH_Lichthupe : 20|1@1+ (1.0,0.0) [0.0|1] ""  Vector__XXX
 SG_ BCM1_MH_Schalter : 21|1@1+ (1.0,0.0) [0.0|1] ""  Motor_EDC17_D4,Motor_ME17_BY,Motor_MED17_SIMOS8_D4
 SG_ HYB_Anf_E_Mode : 22|1@1+ (1.0,0.0) [0.0|1] ""  Vector__XXX
 SG_ HUD_NV_in_Anzeige : 23|1@1+ (1.0,0.0) [0.0|1] ""  Vector__XXX
 SG_ BCM1_Touristen_Licht_Anf : 24|1@1+ (1.0,0.0) [0.0|1] ""  Vector__XXX
 SG_ LV_Abblendlicht_li_def : 25|1@1+ (1.0,0.0) [0.0|1] ""  Vector__XXX
 SG_ LV_Abblendlicht_re_def : 26|1@1+ (1.0,0.0) [0.0|1] ""  Vector__XXX
 SG_ LV_Abblendlicht_Anzeige : 27|1@1+ (1.0,0.0) [0.0|1] ""  Vector__XXX
 SG_ LV_AFL_aktiv_Anzeige : 28|1@1+ (1.0,0.0) [0.0|1] ""  Vector__XXX
 SG_ BCM1_Licht_Dunkelheit_aktiv : 29|1@1+ (1.0,0.0) [0.0|1] ""  Vector__XXX
 SG_ LV_Nebelschlusslicht_Anzeige : 30|1@1+ (1.0,0.0) [0.0|1] ""  Vector__XXX
 SG_ BCM1_Linksverkehr : 31|1@1+ (1.0,0.0) [0.0|1] ""  Vector__XXX
 SG_ BCM2_P_verriegelt : 32|1@1+ (1.0,0.0) [0.0|1] ""  Getriebe_VL381_C7
 SG_ BCM1_LDS_Stellung : 33|3@1+ (1.0,0.0) [0.0|7] ""  Vector__XXX
 SG_ BCM1_Allwetterlicht_Anf : 36|1@1+ (1.0,0.0) [0.0|1] ""  Vector__XXX
 SG_ HUD_Anzeigefehler_NV : 37|1@1+ (1.0,0.0) [0.0|1] ""  Vector__XXX
 SG_ ESP_Diagnose : 38|1@1+ (1.0,0.0) [0.0|1] ""  SCU_D4

BO_ 130 Getriebe_01: 8 Getriebe_AL551_951_D4_C7
 SG_ Getriebe_01_CHK : 0|8@1+ (1,0) [0|255] ""  Gateway_D4C7,Motor_EDC17_D4,Motor_ME17_BY,Motor_MED17_SIMOS8_D4
 SG_ Getriebe_01_BZ : 8|4@1+ (1,0) [0|15] ""  Gateway_D4C7,Motor_EDC17_D4,Motor_ME17_BY,Motor_MED17_SIMOS8_D4
 SG_ GE_Schaltvorgang : 12|1@1+ (1.0,0.0) [0.0|1] ""  Gateway_D4C7,Motor_EDC17_D4,Motor_ME17_BY,Motor_MED17_SIMOS8_D4
 SG_ GE_Status_Kupplung : 13|2@1+ (1.0,0.0) [0.0|3] ""  Gateway_D4C7,Motor_EDC17_D4,Motor_ME17_BY,Motor_MED17_SIMOS8_D4
 SG_ GE_Verbot_Ausblendung : 15|1@1+ (1.0,0.0) [0.0|1] ""  Gateway_D4C7,Motor_EDC17_D4,Motor_ME17_BY,Motor_MED17_SIMOS8_D4
 SG_ GE_MMom_Soll : 16|10@1+ (1,0) [0|1021] ""  Gateway_D4C7,Motor_EDC17_D4,Motor_ME17_BY,Motor_MED17_SIMOS8_D4
 SG_ GE_MMom_Status : 26|2@1+ (1.0,0.0) [0.0|3] ""  Gateway_D4C7,Motor_EDC17_D4,Motor_ME17_BY,Motor_MED17_SIMOS8_D4
 SG_ GE_Freig_Mmom_Soll : 28|1@1+ (1,0) [0|1] ""  Gateway_D4C7
 SG_ GE_Status_Schaltablauf : 29|3@1+ (1,0) [0|7] ""  Gateway_D4C7
 SG_ GE_MMom_Vorhalt : 32|10@1+ (1,0) [0|1021] ""  Gateway_D4C7,Motor_EDC17_D4,Motor_ME17_BY,Motor_MED17_SIMOS8_D4
 SG_ GE_Freig_MMom_Vorhalt : 42|1@1+ (1.0,0.0) [0.0|1] ""  Gateway_D4C7,Motor_EDC17_D4,Motor_ME17_BY,Motor_MED17_SIMOS8_D4
 SG_ GE_KD_Fehler : 63|1@1+ (1.0,0.0) [0.0|1] ""  Gateway_D4C7

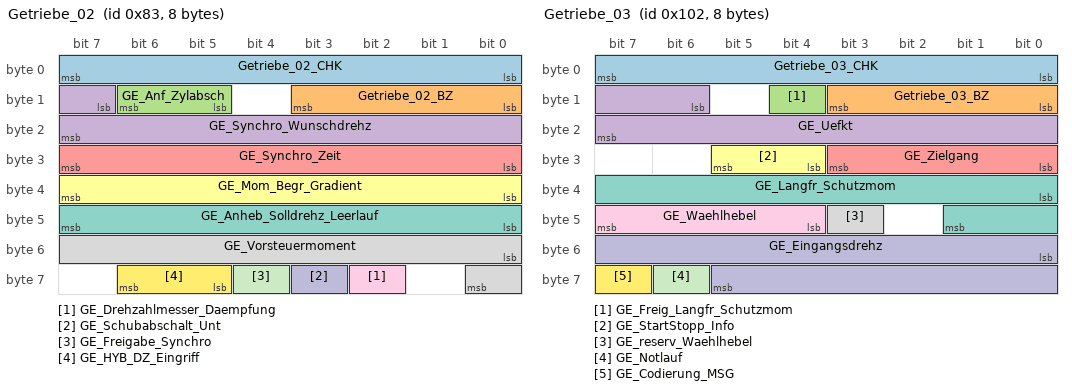
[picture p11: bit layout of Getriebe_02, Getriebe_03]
BO_ 131 Getriebe_02: 8 Getriebe_AL551_951_D4_C7
 SG_ Getriebe_02_CHK : 0|8@1+ (1,0) [0|255] ""  Motor_EDC17_D4,Motor_ME17_BY,Motor_MED17_SIMOS8_D4
 SG_ Getriebe_02_BZ : 8|4@1+ (1,0) [0|15] ""  Motor_EDC17_D4,Motor_ME17_BY,Motor_MED17_SIMOS8_D4
 SG_ GE_Anf_Zylabsch : 13|2@1+ (1.0,0.0) [0.0|3] ""  Motor_ME17_BY,Motor_MED17_SIMOS8_D4
 SG_ GE_Synchro_Wunschdrehz : 15|9@1+ (25,0) [0|12750] "Unit_MinutInver"  Motor_EDC17_D4,Motor_ME17_BY,Motor_MED17_SIMOS8_D4
 SG_ GE_Synchro_Zeit : 24|8@1+ (20,0) [0|5080] "Unit_MilliSecon"  Motor_EDC17_D4,Motor_ME17_BY,Motor_MED17_SIMOS8_D4
 SG_ GE_Mom_Begr_Gradient : 32|8@1+ (10,0) [0|2540] "Unit_NewtoMeterPerSecon"  Motor_EDC17_D4,Motor_ME17_BY,Motor_MED17_SIMOS8_D4
 SG_ GE_Anheb_Solldrehz_Leerlauf : 40|8@1+ (10,0) [0|2540] "Unit_MinutInver"  Motor_EDC17_D4,Motor_ME17_BY,Motor_MED17_SIMOS8_D4
 SG_ GE_Vorsteuermoment : 48|9@1+ (1,0) [0|509] ""  Motor_EDC17_D4,Motor_ME17_BY,Motor_MED17_SIMOS8_D4
 SG_ GE_Drehzahlmesser_Daempfung : 58|1@1+ (1.0,0.0) [0.0|1] ""  Motor_EDC17_D4,Motor_ME17_BY,Motor_MED17_SIMOS8_D4
 SG_ GE_Schubabschalt_Unt : 59|1@1+ (1.0,0.0) [0.0|1] ""  Motor_EDC17_D4,Motor_ME17_BY,Motor_MED17_SIMOS8_D4
 SG_ GE_Freigabe_Synchro : 60|1@1+ (1.0,0.0) [0.0|1] ""  Motor_EDC17_D4,Motor_ME17_BY,Motor_MED17_SIMOS8_D4
 SG_ GE_HYB_DZ_Eingriff : 61|2@1+ (1.0,0.0) [0.0|3] ""  Vector__XXX

BO_ 258 Getriebe_03: 8 Getriebe_AL551_951_D4_C7
 SG_ Getriebe_03_CHK : 0|8@1+ (1,0) [0|255] ""  EPB_D4,Gateway_D4C7,Motor_EDC17_D4,Motor_ME17_BY,Motor_MED17_SIMOS8_D4
 SG_ Getriebe_03_BZ : 8|4@1+ (1,0) [0|15] ""  EPB_D4,Gateway_D4C7,Motor_EDC17_D4,Motor_ME17_BY,Motor_MED17_SIMOS8_D4
 SG_ GE_Freig_Langfr_Schutzmom : 12|1@1+ (1.0,0.0) [0.0|1] ""  Gateway_D4C7,Motor_EDC17_D4,Motor_ME17_BY,Motor_MED17_SIMOS8_D4
 SG_ GE_Uefkt : 14|10@1+ (0.1,0) [0.0|102.2] ""  EPB_D4,Gateway_D4C7,Motor_EDC17_D4,Motor_ME17_BY,Motor_MED17_SIMOS8_D4
 SG_ GE_Zielgang : 24|4@1+ (1.0,0.0) [0.0|15] ""  Gateway_D4C7,Motor_EDC17_D4,Motor_ME17_BY,Motor_MED17_SIMOS8_D4
 SG_ GE_StartStopp_Info : 28|2@1+ (1.0,0.0) [0.0|3] ""  Gateway_D4C7,Motor_EDC17_D4,Motor_ME17_BY,Motor_MED17_SIMOS8_D4
 SG_ GE_Langfr_Schutzmom : 32|10@1+ (1,0) [0|1021] ""  Gateway_D4C7,Motor_EDC17_D4,Motor_ME17_BY,Motor_MED17_SIMOS8_D4
 SG_ GE_reserv_Waehlhebel : 43|1@1+ (1,0) [0|1] ""  Gateway_D4C7
 SG_ GE_Waehlhebel : 44|4@1+ (1.0,0.0) [0.0|15] ""  EPB_D4,Gateway_D4C7,Motor_EDC17_D4,Motor_ME17_BY,Motor_MED17_SIMOS8_D4
 SG_ GE_Eingangsdrehz : 48|14@1+ (1,0) [0|16381] "Unit_MinutInver"  Gateway_D4C7,Motor_EDC17_D4,Motor_ME17_BY,Motor_MED17_SIMOS8_D4
 SG_ GE_Notlauf : 62|1@1+ (1.0,0.0) [0.0|1] ""  Gateway_D4C7,Motor_EDC17_D4,Motor_ME17_BY,Motor_MED17_SIMOS8_D4
 SG_ GE_Codierung_MSG : 63|1@1+ (1.0,0.0) [0.0|1] ""  Gateway_D4C7

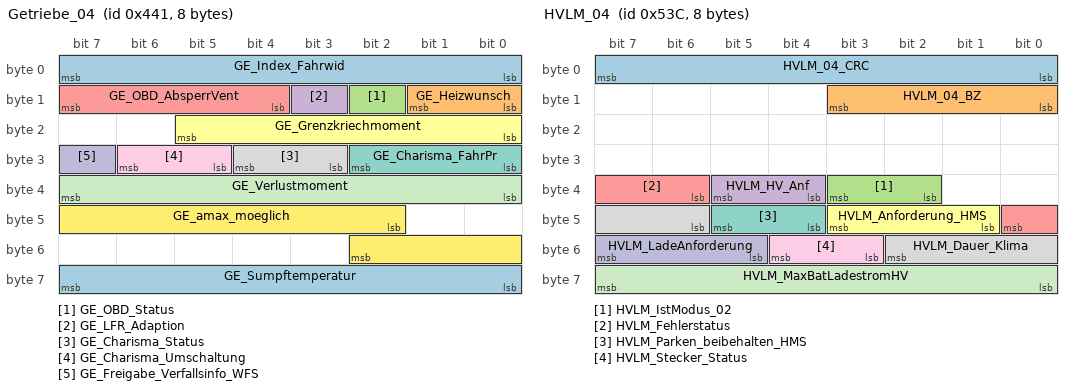
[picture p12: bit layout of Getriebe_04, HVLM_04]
BO_ 1089 Getriebe_04: 8 Getriebe_AL551_951_D4_C7
 SG_ GE_Index_Fahrwid : 0|8@1+ (0.249,-31.623) [-31.623|31.623] ""  Gateway_D4C7,Motor_EDC17_D4,Motor_ME17_BY,Motor_MED17_SIMOS8_D4
 SG_ GE_Heizwunsch : 8|2@1+ (1.0,0.0) [0.0|3] ""  Gateway_D4C7,Motor_EDC17_D4,Motor_ME17_BY,Motor_MED17_SIMOS8_D4
 SG_ GE_OBD_Status : 10|1@1+ (1.0,0.0) [0.0|1] ""  Gateway_D4C7,Motor_EDC17_D4,Motor_ME17_BY,Motor_MED17_SIMOS8_D4
 SG_ GE_LFR_Adaption : 11|1@1+ (1,0) [0|1] ""  Gateway_D4C7,Motor_EDC17_D4,Motor_ME17_BY,Motor_MED17_SIMOS8_D4
 SG_ GE_OBD_AbsperrVent : 12|4@1+ (1.0,0.0) [0.0|15] ""  Gateway_D4C7
 SG_ GE_Grenzkriechmoment : 16|6@1+ (2,0) [0|122] ""  Gateway_D4C7
 SG_ GE_Charisma_FahrPr : 24|3@1+ (1.0,0.0) [0.0|7] ""  Gateway_D4C7
 SG_ GE_Charisma_Status : 27|2@1+ (1.0,0.0) [0.0|3] ""  Gateway_D4C7
 SG_ GE_Charisma_Umschaltung : 29|2@1+ (1.0,0.0) [0.0|3] ""  Gateway_D4C7
 SG_ GE_Freigabe_Verfallsinfo_WFS : 31|1@1+ (1.0,0.0) [0.0|1] ""  Gateway_D4C7,Motor_EDC17_D4,Motor_ME17_BY,Motor_MED17_SIMOS8_D4
 SG_ GE_Verlustmoment : 32|8@1+ (1,0) [0|254] ""  EPB_D4,Gateway_D4C7,Motor_EDC17_D4,Motor_ME17_BY,Motor_MED17_SIMOS8_D4
 SG_ GE_amax_moeglich : 42|9@1+ (0.024,-2.016) [-2.016|10.224] "Unit_MeterPerSeconSquar"  Gateway_D4C7,Motor_EDC17_D4,Motor_ME17_BY,Motor_MED17_SIMOS8_D4
 SG_ GE_Sumpftemperatur : 56|8@1+ (1,-58) [-58|196] "Unit_DegreCelsi"  Gateway_D4C7,Motor_EDC17_D4,Motor_ME17_BY,Motor_MED17_SIMOS8_D4

BO_ 1340 HVLM_04: 8 Gateway
 SG_ HVLM_04_CRC : 0|8@1+ (1,0) [0|255] ""  EPB_MLB
 SG_ HVLM_04_BZ : 8|4@1+ (1,0) [0|15] ""  EPB_MLB
 SG_ HVLM_IstModus_02 : 34|2@1+ (1,0) [0|3] "" Vector__XXX
 SG_ HVLM_HV_Anf : 36|2@1+ (1,0) [0|3] "" Vector__XXX
 SG_ HVLM_Fehlerstatus : 38|3@1+ (1,0) [0|7] "" Vector__XXX
 SG_ HVLM_Anforderung_HMS : 41|3@1+ (1,0) [0|7] ""  EPB_MLB
 SG_ HVLM_Parken_beibehalten_HMS : 44|2@1+ (1,0) [0|3] ""  EPB_MLB
 SG_ HVLM_Dauer_Klima : 46|5@1+ (1,0) [0|30] "Unit_Minut" Vector__XXX
 SG_ HVLM_Stecker_Status : 51|2@1+ (1,0) [0|3] "" Vector__XXX
 SG_ HVLM_LadeAnforderung : 53|3@1+ (1,0) [0|7] "" Vector__XXX
 SG_ HVLM_MaxBatLadestromHV : 56|8@1+ (1,0) [0|253] "Unit_Amper" Vector__XXX

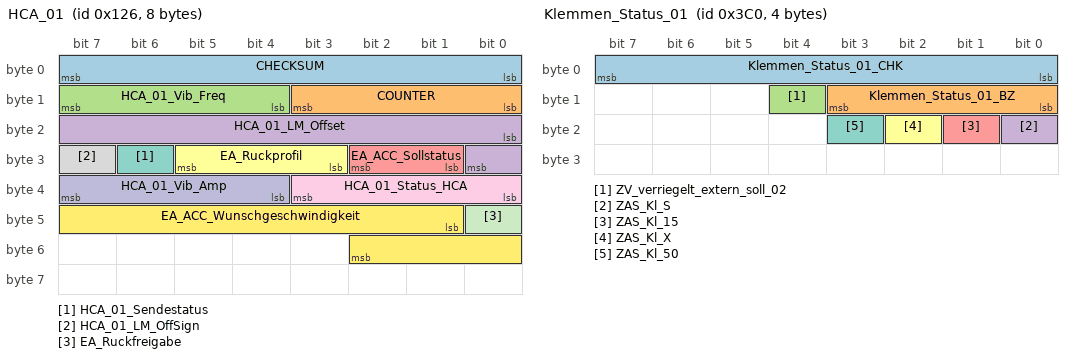
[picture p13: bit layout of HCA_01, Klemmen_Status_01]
BO_ 294 HCA_01: 8 Frontsensorik
 SG_ CHECKSUM : 0|8@1+ (1,0) [0|255] "" Vector__XXX
 SG_ COUNTER : 8|4@1+ (1,0) [0|15] "" Vector__XXX
 SG_ HCA_01_Vib_Freq : 12|4@1+ (1,15) [15|30] "Unit_Hertz" Vector__XXX
 SG_ HCA_01_LM_Offset : 16|9@1+ (1,0) [0|511] "Unit_centiNewtoMeter" Vector__XXX
 SG_ EA_ACC_Sollstatus : 25|2@1+ (1,0) [0|3] ""  Frontradar
 SG_ EA_Ruckprofil : 27|3@1+ (1,0) [0|7] "" Vector__XXX
 SG_ HCA_01_Sendestatus : 30|1@1+ (1,0) [0|1] "" Vector__XXX
 SG_ HCA_01_LM_OffSign : 31|1@1+ (1,0) [0|1] "" Vector__XXX
 SG_ HCA_01_Status_HCA : 32|4@1+ (1,0) [0|15] "" Vector__XXX
 SG_ HCA_01_Vib_Amp : 36|4@1+ (0.2,0) [0|3] "Unit_NewtoMeter" Vector__XXX
 SG_ EA_Ruckfreigabe : 40|1@1+ (1,0) [0|1] "" Vector__XXX
 SG_ EA_ACC_Wunschgeschwindigkeit : 41|10@1+ (0.32,0) [0|327.04] "Unit_KiloMeterPerHour"  Frontradar

BO_ 1811 ISO_ABS_Req: 8 Gateway_D4C7
 SG_ ISO_ABS_Req_Data : 0|64@1+ (1.0,0.0) [0.0|18446744073709551615] ""  ESP_D4

BO_ 1917 ISO_ABS_Resp: 8 ESP_D4
 SG_ ISO_ABS_Resp_Data : 0|64@1+ (1.0,0.0) [0.0|18446744073709551615] ""  Gateway_D4C7

BO_ 1813 ISO_Airbag_01_Req: 8 Gateway_D4C7
 SG_ ISO_Airbag_01_Req_Data : 0|64@1+ (1.0,0.0) [0.0|18446744073709551615] ""  Airbag_D4

BO_ 1919 ISO_Airbag_01_Resp: 8 Airbag_D4
 SG_ ISO_Airbag_01_Resp_Data : 0|64@1+ (1.0,0.0) [0.0|18446744073709551615] ""  Gateway_D4C7

BO_ 1874 ISO_EPB_Req: 8 Gateway_D4C7
 SG_ ISO_EPB_Req_Data : 0|64@1+ (1.0,0.0) [0.0|18446744073709551615] ""  EPB_D4

BO_ 1980 ISO_EPB_Resp: 8 EPB_D4
 SG_ ISO_EPB_Resp_Data : 0|64@1+ (1.0,0.0) [0.0|18446744073709551615] ""  Gateway_D4C7

BO_ 1795 ISO_Funktionaler_Req_Aggregate: 8 Gateway_D4C7
 SG_ ISO_Functionaler_Req_Aggregate : 0|64@1+ (1.0,0.0) [0.0|18446744073709551615] ""  Getriebe_AL551_951_D4_C7,Getriebe_DL501_C7,Getriebe_VL381_C7,Motor_EDC17_D4,Motor_ME17_BY,Motor_MED17_SIMOS8_D4,Motor_Slave_D4,SCR_C7

BO_ 1792 ISO_Funktionaler_Req_All: 8 Gateway_D4C7
 SG_ ISO_ALL_01_Req_Data : 0|64@1+ (1.0,0.0) [0.0|18446744073709551615] ""  Airbag_D4,EPB_D4,ESP_D4,Getriebe_AL551_951_D4_C7,Getriebe_DL501_C7,Getriebe_VL381_C7,Motor_EDC17_D4,Motor_ME17_BY,Motor_MED17_SIMOS8_D4,Motor_Slave_D4,SAK_C7,SCR_C7

BO_ 2015 ISO_Funktionaler_Req_OBD: 8 Gateway_D4C7
 SG_ ISO_OBD_Funktionaler_Req_Data : 0|64@1+ (1.0,0.0) [0.0|18446744073709551615] ""  Getriebe_AL551_951_D4_C7,Getriebe_DL501_C7,Getriebe_VL381_C7,Motor_EDC17_D4,Motor_ME17_BY,Motor_MED17_SIMOS8_D4,Motor_Slave_D4,SCR_C7

BO_ 2017 ISO_Getriebe_01_Req: 8 Gateway_D4C7
 SG_ ISO_Getriebe_01_Req_Data : 0|64@1+ (1.0,0.0) [0.0|18446744073709551615] ""  Getriebe_AL551_951_D4_C7,Getriebe_DL501_C7,Getriebe_VL381_C7

BO_ 2025 ISO_Getriebe_01_Resp: 8 Getriebe_AL551_951_D4_C7
 SG_ ISO_Getriebe_01_Resp_Data : 0|64@1+ (1.0,0.0) [0.0|18446744073709551615] ""  Gateway_D4C7

BO_ 2016 ISO_MO_01_Req: 8 Gateway_D4C7
 SG_ ISO_MO_01_Req_Data : 0|64@1+ (1.0,0.0) [0.0|18446744073709551615] ""  Motor_EDC17_D4,Motor_ME17_BY,Motor_MED17_SIMOS8_D4

BO_ 2024 ISO_MO_01_Resp: 8 Motor_EDC17_D4
 SG_ ISO_MO_01_Resp_Data : 0|64@1+ (1.0,0.0) [0.0|18446744073709551615] ""  Gateway_D4C7

BO_ 2018 ISO_MOS_01_Req: 8 Gateway_D4C7
 SG_ ISO_MOS_01_Req_Data : 0|64@1+ (1.0,0.0) [0.0|18446744073709551615] ""  Motor_Slave_D4

BO_ 2026 ISO_MOS_01_Resp: 8 Motor_Slave_D4
 SG_ ISO_MOS_01_Resp_Data : 0|64@1+ (1.0,0.0) [0.0|18446744073709551615] ""  Gateway_D4C7

BO_ 2019 ISO_OBD_reserv5_Req: 8 Gateway_D4C7
 SG_ ISO_OBD_reserv5_Req_Data : 0|64@1+ (1.0,0.0) [0.0|18446744073709551615] ""  Vector__XXX

BO_ 2027 ISO_OBD_reserv5_Resp: 8 Vector__XXX
 SG_ ISO_OBD_reserv5_Resp_Data : 0|64@1+ (1.0,0.0) [0.0|18446744073709551615] ""  Gateway_D4C7

BO_ 1834 ISO_SCR_Req: 8 Gateway_D4C7
 SG_ ISO_SCR_Req_Data : 0|64@1+ (1.0,0.0) [0.0|18446744073709551615] ""  SCR_C7

BO_ 1940 ISO_SCR_Resp: 8 SCR_C7
 SG_ ISO_SCR_Resp_Data : 0|64@1+ (1.0,0.0) [0.0|18446744073709551615] ""  Gateway_D4C7

BO_ 1814 ISO_SCU_Req: 8 Gateway_D4C7
 SG_ ISO_SCU_Req_Data : 0|64@1+ (1.0,0.0) [0.0|18446744073709551615] ""  Vector__XXX

BO_ 1920 ISO_SCU_Resp: 8 Vector__XXX
 SG_ ISO_SCU_Resp_Data : 0|64@1+ (1.0,0.0) [0.0|18446744073709551615] ""  Gateway_D4C7

BO_ 1820 ISO_Soundaktor_Req: 8 Gateway_D4C7
 SG_ ISO_Soundaktor_Req_Data : 0|64@1+ (1.0,0.0) [0.0|18446744073709551615] ""  SAK_C7

BO_ 1926 ISO_Soundaktor_Resp: 8 SAK_C7
 SG_ ISO_Soundaktor_Resp_Data : 0|64@1+ (1.0,0.0) [0.0|18446744073709551615] ""  Gateway_D4C7

BO_ 1875 ISO_Waehlhebel_Req: 8 Gateway_D4C7
 SG_ ISO_Waehlhebel_Req_Data : 0|64@1+ (1.0,0.0) [0.0|18446744073709551615] ""  Getriebe_AL551_951_D4_C7

BO_ 1981 ISO_Waehlhebel_Resp: 8 Getriebe_AL551_951_D4_C7
 SG_ ISO_Waehlhebel_Resp_Data : 0|64@1+ (1.0,0.0) [0.0|18446744073709551615] ""  Gateway_D4C7

BO_ 1424 Kessy_02: 8 Gateway_D4C7
 SG_ KY_Funkschl_Nr : 0|4@1+ (1.0,0.0) [0.0|15] ""  Vector__XXX
 SG_ KY_ID_Geb_autorisiert : 4|1@1+ (1.0,0.0) [0.0|1] ""  Vector__XXX
 SG_ KY_ID_Geb_steckt : 5|1@1+ (1.0,0.0) [0.0|1] ""  Vector__XXX
 SG_ KY_FFB_Frequenz : 6|2@1+ (1.0,0.0) [0.0|3] ""  Vector__XXX
 SG_ KY_HF_Aktiv : 8|1@1+ (1.0,0.0) [0.0|1] ""  Vector__XXX
 SG_ KY_LF_Aktiv : 9|1@1+ (1.0,0.0) [0.0|1] ""  Vector__XXX
 SG_ KY_ELV_verr : 10|1@1+ (1.0,0.0) [0.0|1] ""  EPB_D4
 SG_ KY_ELV_entr : 11|1@1+ (1.0,0.0) [0.0|1] ""  Vector__XXX
 SG_ KY_ELV_enable_Anforderung : 12|1@1+ (1.0,0.0) [0.0|1] ""  Vector__XXX
 SG_ KY_Valet_Parking : 14|1@1+ (1.0,0.0) [0.0|1] ""  Vector__XXX
 SG_ KY_Keyless_Verbau : 15|1@1+ (1.0,0.0) [0.0|1] ""  Vector__XXX
 SG_ KY_FBS_Fahrer_Hinweise : 16|3@1+ (1.0,0.0) [0.0|7] ""  Vector__XXX
 SG_ FBS_Warn_Lenkung_def : 19|1@1+ (1.0,0.0) [0.0|1] ""  Vector__XXX
 SG_ FBS_Warn_LenkVerriegelung_def : 20|1@1+ (1.0,0.0) [0.0|1] ""  Vector__XXX
 SG_ FBS_Warn_Schluessel_Batt : 21|1@1+ (1.0,0.0) [0.0|1] ""  Vector__XXX
 SG_ FBS_Prio_Warn_04 : 22|1@1+ (1.0,0.0) [0.0|1] ""  Vector__XXX
 SG_ FBS_Prio_Warn_05 : 23|1@1+ (1.0,0.0) [0.0|1] ""  Vector__XXX
 SG_ KY_KYL_Fahrer_Hinweise : 24|3@1+ (1.0,0.0) [0.0|7] ""  Vector__XXX
 SG_ KYL_Warn_kein_Schluessel : 27|1@1+ (1.0,0.0) [0.0|1] ""  Vector__XXX
 SG_ KYL_Warn_Kessy_defekt : 28|1@1+ (1.0,0.0) [0.0|1] ""  Vector__XXX
 SG_ KY_KYL_Prio_Warn_03 : 29|1@1+ (1.0,0.0) [0.0|1] ""  Vector__XXX
 SG_ KY_KYL_Prio_Warn_04 : 30|1@1+ (1.0,0.0) [0.0|1] ""  Vector__XXX
 SG_ KY_KYL_Prio_Warn_05 : 31|1@1+ (1.0,0.0) [0.0|1] ""  Vector__XXX
 SG_ KY_Schluessel_Soll : 32|4@1+ (1.0,0.0) [0.0|15] ""  Vector__XXX
 SG_ KY_Schluessel_Ist : 36|4@1+ (1.0,0.0) [0.0|15] ""  Vector__XXX
 SG_ KY_WFS_Safe : 40|1@1+ (1.0,0.0) [0.0|1] ""  Vector__XXX
 SG_ KY_WFS_LZ : 41|2@1+ (1.0,0.0) [0.0|3] ""  Vector__XXX
 SG_ KY_StartStopp_Info : 43|2@1+ (1.0,0.0) [0.0|3] ""  Motor_EDC17_D4,Motor_ME17_BY,Motor_MED17_SIMOS8_D4
 SG_ KYL_Notzuendschloss : 45|1@1+ (1.0,0.0) [0.0|1] ""  Vector__XXX
 SG_ KYL_Warn_Notzuendschloss : 46|1@1+ (1.0,0.0) [0.0|1] ""  Vector__XXX
 SG_ FBS_KD_Fehler : 47|1@1+ (1.0,0.0) [0.0|1] ""  Vector__XXX

BO_ 960 Klemmen_Status_01: 4 Gateway_D4C7
 SG_ Klemmen_Status_01_CHK : 0|8@1+ (1,0) [0|255] ""  EPB_D4,Getriebe_AL551_951_D4_C7,Motor_EDC17_D4,Motor_ME17_BY,Motor_MED17_SIMOS8_D4
 SG_ Klemmen_Status_01_BZ : 8|4@1+ (1,0) [0|15] ""  EPB_D4,Getriebe_AL551_951_D4_C7,Motor_EDC17_D4,Motor_ME17_BY,Motor_MED17_SIMOS8_D4
 SG_ ZV_verriegelt_extern_soll_02 : 12|1@1+ (1.0,0.0) [0.0|1] ""  Getriebe_AL551_951_D4_C7
 SG_ ZAS_Kl_S : 16|1@1+ (1.0,0.0) [0.0|1] ""  EPB_D4,Getriebe_AL551_951_D4_C7
 SG_ ZAS_Kl_15 : 17|1@1+ (1.0,0.0) [0.0|1] ""  EPB_D4,Getriebe_AL551_951_D4_C7,Getriebe_DL501_C7,Motor_EDC17_D4,Motor_ME17_BY,Motor_MED17_SIMOS8_D4,SCU_D4
 SG_ ZAS_Kl_X : 18|1@1+ (1.0,0.0) [0.0|1] ""  EPB_D4,SCU_D4
 SG_ ZAS_Kl_50 : 19|1@1+ (1.0,0.0) [0.0|1] ""  EPB_D4,Motor_EDC17_D4,Motor_ME17_BY,Motor_MED17_SIMOS8_D4

BO_ 959 Klima_01: 8 Gateway_D4C7
 SG_ KL_Drehz_Anh : 0|1@1+ (1.0,0.0) [0.0|1] ""  Motor_EDC17_D4,Motor_ME17_BY,Motor_MED17_SIMOS8_D4
 SG_ KL_Vorwarn_Komp_ein : 1|1@1+ (1.0,0.0) [0.0|1] ""  Motor_EDC17_D4,Motor_ME17_BY,Motor_MED17_SIMOS8_D4
 SG_ KL_Handshake_BEM : 2|1@1+ (1.0,0.0) [0.0|1] ""  Vector__XXX
 SG_ KL_Komp_Moment_alt : 3|1@1+ (1.0,0.0) [0.0|1] ""  Vector__XXX
 SG_ KL_Vorwarn_HHS_ein : 4|1@1+ (1.0,0.0) [0.0|1] ""  Motor_EDC17_D4,Motor_ME17_BY,Motor_MED17_SIMOS8_D4
 SG_ KL_Vorwarn_HFS_ein : 5|1@1+ (1.0,0.0) [0.0|1] ""  Motor_EDC17_D4,Motor_ME17_BY,Motor_MED17_SIMOS8_D4
 SG_ KL_Vorwarn_Zuheizer_ein : 6|1@1+ (1.0,0.0) [0.0|1] ""  Vector__XXX
 SG_ KL_KD_Fehler : 7|1@1+ (1.0,0.0) [0.0|1] ""  Vector__XXX
 SG_ KL_Comp_rev_rq : 8|8@1+ (50,0) [0|8600] "Unit_MinutInver"  Vector__XXX
 SG_ KL_Charisma_FahrPr : 16|3@1+ (1.0,0.0) [0.0|7] ""  Vector__XXX
 SG_ KL_Charisma_Status : 19|2@1+ (1.0,0.0) [0.0|3] ""  Vector__XXX
 SG_ KL_Charisma_Umschaltung : 21|2@1+ (1.0,0.0) [0.0|3] ""  Vector__XXX
 SG_ KL_Last_Kompr : 24|8@1+ (0.25,0) [0.00|63.50] "Unit_NewtoMeter"  Motor_EDC17_D4,Motor_ME17_BY,Motor_MED17_SIMOS8_D4
 SG_ KL_Leistung_Hzg_Soll : 32|8@1+ (11,0) [0|2805] "Unit_Watt"  Vector__XXX
 SG_ KL_Anf_KL : 40|8@1+ (0.4,0) [0.0|101.6] "Unit_PerCent"  Motor_EDC17_D4,Motor_ME17_BY,Motor_MED17_SIMOS8_D4
 SG_ KL_4_Zonen : 48|1@1+ (1.0,0.0) [0.0|1] ""  Motor_EDC17_D4,Motor_ME17_BY,Motor_MED17_SIMOS8_D4
 SG_ KL_AC_Schalter : 49|1@1+ (1.0,0.0) [0.0|1] ""  Getriebe_AL551_951_D4_C7
 SG_ KL_Zustand : 50|1@1+ (1.0,0.0) [0.0|1] ""  Getriebe_AL551_951_D4_C7,Motor_EDC17_D4,Motor_ME17_BY,Motor_MED17_SIMOS8_D4
 SG_ KL_Thermomanagement : 51|2@1+ (1.0,0.0) [0.0|3] ""  Motor_EDC17_D4,Motor_ME17_BY,Motor_MED17_SIMOS8_D4
 SG_ KL_Comp_enable : 53|1@1+ (1.0,0.0) [0.0|1] ""  Vector__XXX
 SG_ KL_StartStopp_Info : 54|2@1+ (1.0,0.0) [0.0|3] ""  Motor_EDC17_D4,Motor_ME17_BY,Motor_MED17_SIMOS8_D4
 SG_ KL_el_Zuheizer_Stufe : 56|3@1+ (1.0,0.0) [0.0|7] ""  Motor_EDC17_D4
 SG_ KL_Diag_Absperrvent : 59|4@1+ (1.0,0.0) [0.0|15] ""  Vector__XXX

BO_ 1636 Klima_02: 8 Gateway
 SG_ KL_Stromsparmodus : 0|1@1+ (1,0) [0|1] "" Vector__XXX
 SG_ KL_Spg_Hzg_aus : 1|1@1+ (1,0) [0|1] "" Vector__XXX
 SG_ KL_AQS_Empfindlichkeit : 2|3@1+ (1,0) [0|7] "" Vector__XXX
 SG_ KL_SIH_Soll_li : 8|3@1+ (1,0) [0|7] "" Vector__XXX
 SG_ KL_SIH_Takt_li : 11|1@1+ (1,0) [0|1] "" Vector__XXX
 SG_ KL_SIL_Soll_li : 12|3@1+ (1,0) [0|7] "" Vector__XXX
 SG_ KL_LRH_aus : 15|1@1+ (1,0) [0|1] "" Vector__XXX
 SG_ KL_SIH_Soll_re : 16|3@1+ (1,0) [0|7] "" Vector__XXX
 SG_ KL_SIH_Takt_re : 19|1@1+ (1,0) [0|1] "" Vector__XXX
 SG_ KL_SIL_Soll_re : 20|3@1+ (1,0) [0|7] "" Vector__XXX
 SG_ KL_Beschlagsgefahr : 23|1@1+ (1,0) [0|1] "" Vector__XXX
 SG_ KL_HSH_ein_Soll : 24|1@1+ (1,0) [0|1] "" Vector__XXX
 SG_ KL_HSH_Taktung : 25|1@1+ (1,0) [0|1] "" Vector__XXX
 SG_ KL_Zuheizer_Freigabe : 26|1@1+ (1,0) [0|1] "" Vector__XXX
 SG_ KL_ZHE_Status : 27|1@1+ (1,0) [0|1] "" Vector__XXX
 SG_ KL_FSH_Status : 28|2@1+ (1,0) [0|3] "" Vector__XXX
 SG_ KL_LRH_on_off : 30|1@1+ (1,0) [0|1] "" Vector__XXX
 SG_ KL_Umluftklappe_Status : 32|4@1+ (1,0) [0|15] "" Vector__XXX
 SG_ KL_Geblaese_Status : 36|4@1+ (1,0) [0|15] ""  BMS_Hybrid
 SG_ KL_I_Geblaese : 40|8@1+ (0.25,0) [0|63.5] "Unit_Amper" Vector__XXX
 SG_ KL_Kompressorstrom_soll : 48|10@1+ (1,0) [0|1021] "" Vector__XXX
 SG_ KL_FSH_P_Soll : 58|6@1+ (20,0) [0|1240] "Unit_Watt" Vector__XXX

BO_ 1646 Klima_03: 7 Gateway
 SG_ KL_STL_aktiv : 0|1@1+ (1,0) [0|1] "" Vector__XXX
 SG_ KL_STH_aktiv : 1|1@1+ (1,0) [0|1] "" Vector__XXX
 SG_ KL_Solarluefter_aktiv : 2|1@1+ (1,0) [0|1] "" Vector__XXX
 SG_ KL_Umluft_Taste : 3|1@1+ (1,0) [0|1] "" Vector__XXX
 SG_ KL_Geblaese_Fond_Status : 4|4@1+ (1,0) [0|15] "" Vector__XXX
 SG_ KL_STH_Ansteuerung : 8|2@1+ (1,0) [0|3] "" Vector__XXX
 SG_ KL_STH_Betriebsdauer : 10|6@1+ (1,0) [0|60] "Unit_Minut" Vector__XXX
 SG_ KL_Magnetventil : 16|1@1+ (1,0) [0|1] "" Vector__XXX
 SG_ KL_WaPu : 17|1@1+ (1,0) [0|1] "" Vector__XXX
 SG_ KL_Freigabe_KRH_li : 18|3@1+ (1,0) [0|7] "" Vector__XXX
 SG_ KL_Freigabe_KRH_re : 21|3@1+ (1,0) [0|7] "" Vector__XXX
 SG_ KL_BCmE_Livetip_Freigabe : 24|1@1+ (1,0) [0|1] "" Vector__XXX
 SG_ KL_HYB_ASV_hinten_schliessen_Anf : 25|1@1+ (1,0) [0|1] ""  BMS_Hybrid
 SG_ KL_HYB_ASV_vorne_schliessen_Anf : 26|1@1+ (1,0) [0|1] ""  BMS_Hybrid
 SG_ KL_HYB_Spuelbetrieb_Freigabe : 27|1@1+ (1,0) [0|1] ""  BMS_Hybrid
 SG_ KL_Fehler_ElWaPu : 28|1@1+ (1,0) [0|1] ""  Motor_MLB_AU64_AU57_Diesel,Motor_MLB_BY_Otto,Motor_MLB_C7_PHEV,Motor_MLB_D4_C7_Hybrid,Motor_MLB_D4_C7_Otto
 SG_ KL_Innen_Temp : 32|8@1+ (0.5,-50) [-50|76] "Unit_DegreCelsi"  BMS_Hybrid
 SG_ KL_Sonnenintensitaet : 40|8@1+ (10,0) [0|1000] "Unit_WattPerMeterSquar" Vector__XXX
 SG_ KL_AussenTemp_WK : 48|8@1+ (0.5,-50) [-50|76] "Unit_DegreCelsi" Vector__XXX

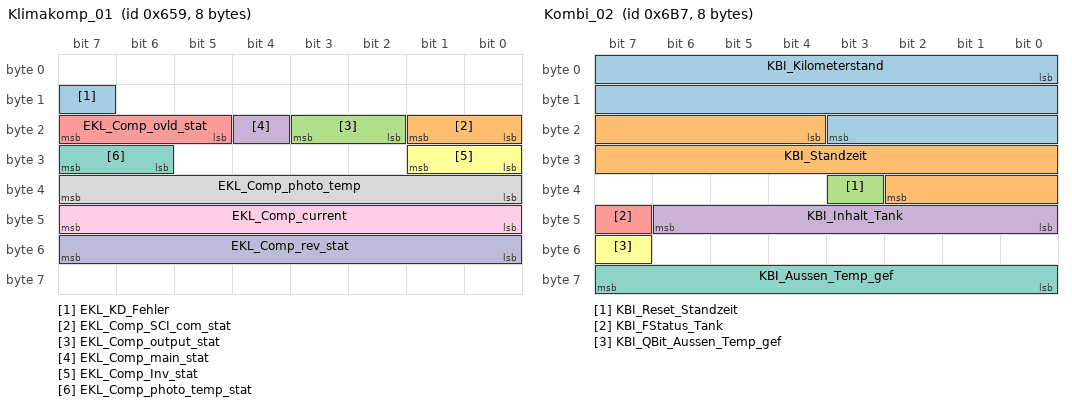
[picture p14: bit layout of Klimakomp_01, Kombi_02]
BO_ 1625 Klimakomp_01: 8 Gateway
 SG_ EKL_KD_Fehler : 15|1@1+ (1,0) [0|1] "" Vector__XXX
 SG_ EKL_Comp_SCI_com_stat : 16|2@1+ (1,0) [0|3] "" Vector__XXX
 SG_ EKL_Comp_output_stat : 18|2@1+ (1,0) [0|3] "" Vector__XXX
 SG_ EKL_Comp_main_stat : 20|1@1+ (1,0) [0|1] "" Vector__XXX
 SG_ EKL_Comp_ovld_stat : 21|3@1+ (1,0) [0|7] "" Vector__XXX
 SG_ EKL_Comp_Inv_stat : 24|2@1+ (1,0) [0|3] "" Vector__XXX
 SG_ EKL_Comp_photo_temp_stat : 30|2@1+ (1,0) [0|3] "" Vector__XXX
 SG_ EKL_Comp_photo_temp : 32|8@1+ (1,0) [0|254] "Unit_DegreCelsi" Vector__XXX
 SG_ EKL_Comp_current : 40|8@1+ (0.1,0) [0|25.4] "Unit_Amper"  Motor_MLB_C7_PHEV,Motor_MLB_D4_C7_Hybrid
 SG_ EKL_Comp_rev_stat : 48|8@1+ (50,0) [0|8600] "Unit_MinutInver" Vector__XXX

BO_ 779 Kombi_01: 8 Gateway_D4C7
 SG_ KBI_ABS_Lampe : 0|1@1+ (1.0,0.0) [0.0|1] ""  Getriebe_AL551_951_D4_C7
 SG_ KBI_ESP_Lampe : 1|1@1+ (1.0,0.0) [0.0|1] ""  Getriebe_AL551_951_D4_C7
 SG_ KBI_BKL_Lampe : 2|1@1+ (1.0,0.0) [0.0|1] ""  Getriebe_AL551_951_D4_C7
 SG_ KBI_Airbag_Lampe : 3|1@1+ (1.0,0.0) [0.0|1] ""  Getriebe_AL551_951_D4_C7
 SG_ KBI_SILA_gueltig : 4|1@1+ (1.0,0.0) [0.0|1] ""  Getriebe_AL551_951_D4_C7
 SG_ KBI_Lenkung_Lampe : 5|1@1+ (1,0) [0|1] ""  Getriebe_AL551_951_D4_C7
 SG_ KBI_Vorglueh_System_Lampe : 6|1@1+ (1.0,0.0) [0.0|1] ""  Getriebe_AL551_951_D4_C7,Motor_EDC17_D4
 SG_ KBI_NV_in_Anzeige : 7|1@1+ (1.0,0.0) [0.0|1] ""  Getriebe_AL551_951_D4_C7
 SG_ COUNTER : 8|4@1+ (1,0) [0|15] ""  Getriebe_AL551_951_D4_C7
 SG_ KBI_Anzeigestatus_ACC : 12|1@1+ (1.0,0.0) [0.0|1] ""  Getriebe_AL551_951_D4_C7
 SG_ KBI_Oeldruck_Schalter : 15|1@1+ (1.0,0.0) [0.0|1] ""  Getriebe_AL551_951_D4_C7
 SG_ KBI_Tankwarnung : 16|1@1+ (1.0,0.0) [0.0|1] ""  Getriebe_AL551_951_D4_C7,Motor_EDC17_D4,Motor_ME17_BY,Motor_MED17_SIMOS8_D4
 SG_ KBI_MFA_v_Einheit_01 : 17|1@1+ (1.0,0.0) [0.0|1] ""  Getriebe_AL551_951_D4_C7,Motor_EDC17_D4,Motor_ME17_BY,Motor_MED17_SIMOS8_D4
 SG_ KBI_im_Stellgliedtest : 18|1@1+ (1.0,0.0) [0.0|1] ""  Getriebe_AL551_951_D4_C7
 SG_ KBI_Anzeigefehler_LDW : 19|2@1+ (1.0,0.0) [0.0|3] ""  Getriebe_AL551_951_D4_C7
 SG_ KBI_Variante_USA : 21|1@1+ (1.0,0.0) [0.0|1] ""  Getriebe_AL551_951_D4_C7
 SG_ KBI_Oeldruckwarnung : 22|1@1+ (1.0,0.0) [0.0|1] ""  Getriebe_AL551_951_D4_C7
 SG_ KBI_Handbremse : 23|1@1+ (1.0,0.0) [0.0|1] ""  Getriebe_AL551_951_D4_C7
 SG_ KBI_V_Digital : 24|9@1+ (1,0) [0|511] ""  Getriebe_AL551_951_D4_C7
 SG_ KBI_PLA_in_Anzeige : 33|1@1+ (1.0,0.0) [0.0|1] ""  Getriebe_AL551_951_D4_C7
 SG_ KBI_Anzeigefehler_NV : 34|1@1+ (1.0,0.0) [0.0|1] ""  Getriebe_AL551_951_D4_C7
 SG_ KBI_angez_Geschw : 48|10@1+ (0.32,0) [0.00|325.12] "Unit_KiloMeterPerHour"  Getriebe_AL551_951_D4_C7,Getriebe_DL501_C7,Getriebe_VL381_C7,Motor_EDC17_D4,Motor_ME17_BY,Motor_MED17_SIMOS8_D4
 SG_ KBI_Einheit_Tacho : 58|1@1+ (1.0,0.0) [0.0|1] ""  Getriebe_AL551_951_D4_C7,Motor_EDC17_D4,Motor_ME17_BY,Motor_MED17_SIMOS8_D4
 SG_ KBI_Konsistenz_ACC : 59|1@1+ (1.0,0.0) [0.0|1] ""  Getriebe_AL551_951_D4_C7
 SG_ KBI_Fehler_Anzeige_ACC : 60|1@1+ (1.0,0.0) [0.0|1] ""  Getriebe_AL551_951_D4_C7
 SG_ KBI_Anzeigefehler_SWA : 61|2@1+ (1.0,0.0) [0.0|3] ""  Getriebe_AL551_951_D4_C7
 SG_ KBI_KD_Fehler : 63|1@1+ (1.0,0.0) [0.0|1] ""  Getriebe_AL551_951_D4_C7

BO_ 1719 Kombi_02: 8 Gateway_D4C7
 SG_ KBI_Kilometerstand : 0|20@1+ (1,0) [0|1048573] "Unit_KiloMeter"  Vector__XXX
 SG_ KBI_Standzeit : 20|15@1+ (4,0) [0|131068] "Unit_Secon"  Getriebe_AL551_951_D4_C7,Getriebe_DL501_C7,Getriebe_VL381_C7,Motor_EDC17_D4,Motor_ME17_BY,Motor_MED17_SIMOS8_D4
 SG_ KBI_Reset_Standzeit : 35|1@1+ (1.0,0.0) [0.0|1] ""  Getriebe_AL551_951_D4_C7,Getriebe_DL501_C7,Getriebe_VL381_C7,Motor_EDC17_D4,Motor_ME17_BY,Motor_MED17_SIMOS8_D4
 SG_ KBI_Inhalt_Tank : 40|7@1+ (1,0) [0|126] "Unit_Liter"  Motor_EDC17_D4,Motor_ME17_BY,Motor_MED17_SIMOS8_D4
 SG_ KBI_FStatus_Tank : 47|1@1+ (1.0,0.0) [0.0|1] ""  Motor_EDC17_D4,Motor_ME17_BY,Motor_MED17_SIMOS8_D4
 SG_ KBI_QBit_Aussen_Temp_gef : 55|1@1+ (1.0,0.0) [0.0|1] ""  EPB_D4,Getriebe_AL551_951_D4_C7,Getriebe_DL501_C7,Getriebe_VL381_C7,Motor_EDC17_D4,Motor_ME17_BY,Motor_MED17_SIMOS8_D4,SCR_C7
 SG_ KBI_Aussen_Temp_gef : 56|8@1+ (0.5,-50) [-50.0|75.0] "Unit_DegreCelsi"  EPB_D4,Getriebe_AL551_951_D4_C7,Getriebe_DL501_C7,Getriebe_VL381_C7,Motor_EDC17_D4,Motor_ME17_BY,Motor_MED17_SIMOS8_D4,SCR_C7

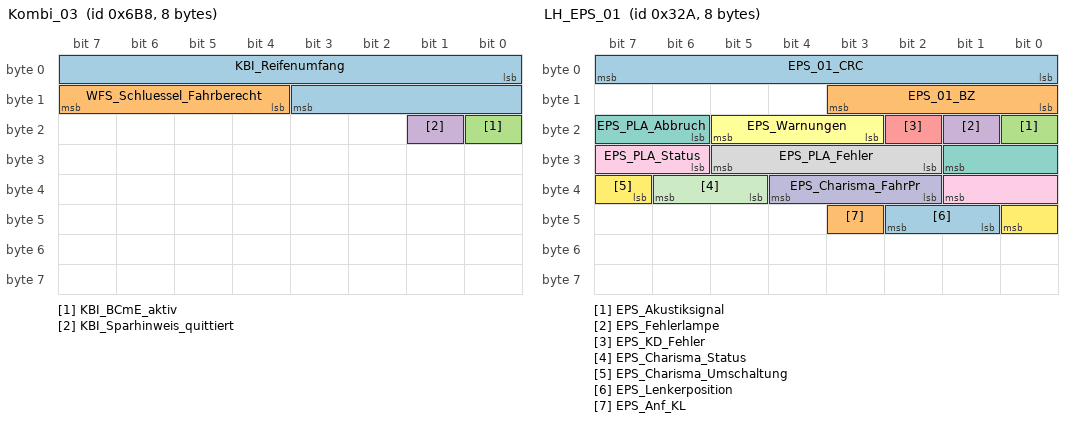
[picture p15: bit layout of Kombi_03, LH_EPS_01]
BO_ 1720 Kombi_03: 8 Gateway_D4C7
 SG_ KBI_Reifenumfang : 0|12@1+ (1,0) [0|4095] "Unit_MilliMeter"  Getriebe_AL551_951_D4_C7,Getriebe_DL501_C7,Getriebe_VL381_C7
 SG_ WFS_Schluessel_Fahrberecht : 12|4@1+ (1.0,0.0) [0.0|15] ""  Vector__XXX
 SG_ KBI_BCmE_aktiv : 16|1@1+ (1.0,0.0) [0.0|1] ""  Vector__XXX
 SG_ KBI_Sparhinweis_quittiert : 17|1@1+ (1.0,0.0) [0.0|1] ""  Vector__XXX

BO_ 517 KS_Airbag: 8 Airbag_D4
 SG_ KS_Airbag_Data : 0|64@1+ (1.0,0.0) [0.0|18446744073709551615] ""  Gateway_D4C7

BO_ 640 KS_Master: 8 Gateway_D4C7
 SG_ KS_Master_Data : 0|64@1+ (1.0,0.0) [0.0|18446744073709551615] ""  Airbag_D4

BO_ 919 LDW_02: 8 Gateway_D4C7
 SG_ LDW_Gong : 12|2@1+ (1.0,0.0) [0.0|3] ""  Kombi_D4
 SG_ LDW_SW_Warnung_links : 14|1@1+ (1.0,0.0) [0.0|1] ""  Vector__XXX
 SG_ LDW_SW_Warnung_rechts : 15|1@1+ (1.0,0.0) [0.0|1] ""  Vector__XXX
 SG_ LDW_Texte : 16|4@1+ (1.0,0.0) [0.0|15] ""  Kombi_D4
 SG_ LDW_Seite_DLCTLC : 20|1@1+ (1.0,0.0) [0.0|1] ""  Vector__XXX
 SG_ LDW_Lernmodus : 21|3@1+ (1.0,0.0) [0.0|7] ""  HUD_C7
 SG_ LDW_Anlaufsp_VLR : 24|4@1+ (1,0) [0|15] ""  SMLS_D4
 SG_ LDW_Vib_Amp_VLR : 28|4@1+ (1,0) [0|15] ""  SMLS_D4
 SG_ LDW_Anlaufzeit_VLR : 32|4@1+ (1,0) [0|15] ""  SMLS_D4
 SG_ LDW_Lernmodus_rechts : 36|2@1+ (1,0) [0|3] ""  XXX
 SG_ LDW_Lernmodus_links : 38|2@1+ (1,0) [0|3] ""  XXX
 SG_ LDW_DLC : 40|8@1+ (0.01,-1.25) [-1.25|1.25] "Unit_Meter"  Vector__XXX
 SG_ LDW_TLC : 48|5@1+ (0.1,0) [0.0|3.0] "Unit_Secon"  Vector__XXX
 SG_ LDW_Warnung_links : 56|1@1+ (1.0,0.0) [0.0|1] ""  SMLS_D4
 SG_ LDW_Warnung_rechts : 57|1@1+ (1.0,0.0) [0.0|1] ""  SMLS_D4
 SG_ LDW_Codierinfo_fuer_VLR : 58|2@1+ (1.0,0.0) [0.0|3] ""  SMLS_D4
 SG_ LDW_Frontscheibenheizung_aktiv : 60|1@1+ (1.0,0.0) [0.0|1] ""  Klima_D4_C7,SMLS_D4
 SG_ LDW_Status_LED_gelb : 61|1@1+ (1.0,0.0) [0.0|1] ""  APS_D4,Kombi_D4
 SG_ LDW_Status_LED_gruen : 62|1@1+ (1.0,0.0) [0.0|1] ""  APS_D4,Kombi_D4
 SG_ LDW_KD_Fehler : 63|1@1+ (1.0,0.0) [0.0|1] ""  Vector__XXX

BO_ 810 LH_EPS_01: 8 Gateway_D4C7
 SG_ EPS_01_CRC : 0|8@1+ (1,0) [0|255] ""  APS_D4
 SG_ EPS_01_BZ : 8|4@1+ (1,0) [0|15] ""  APS_D4
 SG_ EPS_Akustiksignal : 16|1@1+ (1.0,0.0) [0.0|1] ""  Kombi_D4
 SG_ EPS_Fehlerlampe : 17|1@1+ (1.0,0.0) [0.0|1] ""  Vector__XXX
 SG_ EPS_KD_Fehler : 18|1@1+ (1.0,0.0) [0.0|1] ""  Vector__XXX
 SG_ EPS_Warnungen : 19|3@1+ (1.0,0.0) [0.0|7] ""  Kombi_D4
 SG_ EPS_PLA_Abbruch : 22|4@1+ (1,0) [0|15] ""  APS_D4
 SG_ EPS_PLA_Fehler : 26|4@1+ (1,0) [0|15] ""  APS_D4
 SG_ EPS_PLA_Status : 30|4@1+ (1,0) [0|15] ""  APS_D4
 SG_ EPS_Charisma_FahrPr : 34|3@1+ (1.0,0.0) [0.0|7] ""  Vector__XXX
 SG_ EPS_Charisma_Status : 37|2@1+ (1.0,0.0) [0.0|3] ""  Vector__XXX
 SG_ EPS_Charisma_Umschaltung : 39|2@1+ (1.0,0.0) [0.0|3] ""  Vector__XXX
 SG_ EPS_Lenkerposition : 41|2@1+ (1.0,0.0) [0.0|3] ""  Vector__XXX
 SG_ EPS_Anf_KL : 43|1@1+ (1.0,0.0) [0.0|1] ""  Vector__XXX

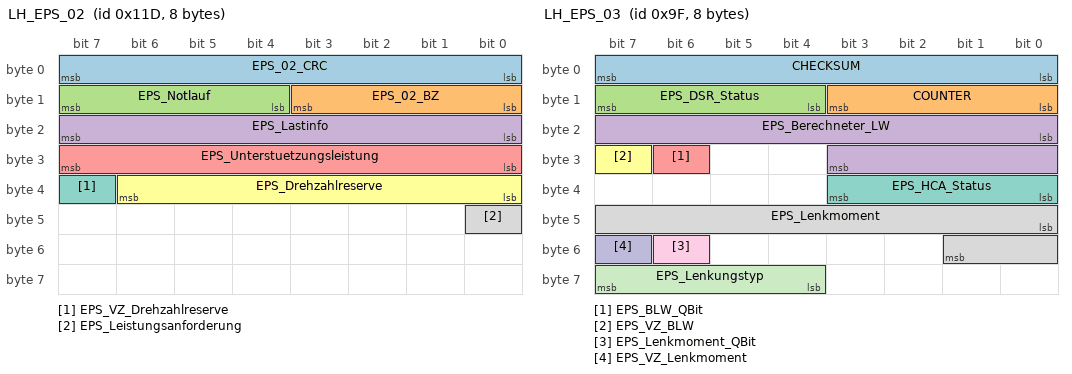
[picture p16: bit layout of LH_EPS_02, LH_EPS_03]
BO_ 285 LH_EPS_02: 8 Gateway_D4C7
 SG_ EPS_02_CRC : 0|8@1+ (1,0) [0|255] ""  SCU_D4
 SG_ EPS_02_BZ : 8|4@1+ (1,0) [0|15] ""  SCU_D4
 SG_ EPS_Notlauf : 12|4@1+ (1.0,0.0) [0.0|15] ""  Vector__XXX
 SG_ EPS_Lastinfo : 16|8@1+ (1,0) [0|253] "Unit_Amper"  Vector__XXX
 SG_ EPS_Unterstuetzungsleistung : 24|8@1+ (0.5,0) [0.0|100.0] "Unit_PerCent"  SCU_D4
 SG_ EPS_Drehzahlreserve : 32|7@1+ (10,0) [0|1000] "Unit_DegreOfArcPerSecon"  SCU_D4
 SG_ EPS_VZ_Drehzahlreserve : 39|1@1+ (1.0,0.0) [0.0|1] ""  SCU_D4
 SG_ EPS_Leistungsanforderung : 40|1@1+ (1.0,0.0) [0.0|1] ""  Vector__XXX

BO_ 159 LH_EPS_03: 8 XXX
 SG_ CHECKSUM : 0|8@1+ (1,0) [0|255] ""  XXX
 SG_ COUNTER : 8|4@1+ (1,0) [0|15] ""  XXX
 SG_ EPS_DSR_Status : 12|4@1+ (1,0) [0|15] ""  XXX
 SG_ EPS_Berechneter_LW : 16|12@1+ (0.15,0) [0|613.95] "Unit_DegreOfArc"  XXX
 SG_ EPS_BLW_QBit : 30|1@1+ (1,0) [0|1] ""  XXX
 SG_ EPS_VZ_BLW : 31|1@1+ (1,0) [0|1] ""  XXX
 SG_ EPS_HCA_Status : 32|4@1+ (1,0) [0|15] ""  XXX
 SG_ EPS_Lenkmoment : 40|10@1+ (1,0) [0|8] "Unit_centiNewtoMeter"  XXX
 SG_ EPS_Lenkmoment_QBit : 54|1@1+ (1,0) [0|1] ""  XXX
 SG_ EPS_VZ_Lenkmoment : 55|1@1+ (1,0) [0|1] ""  XXX
 SG_ EPS_Lenkungstyp : 60|4@1+ (1,0) [0|15] ""  XXX

BO_ 1137 Licht_hinten_01: 8 Gateway_D4C7
 SG_ Licht_hinten_01_BZ : 0|4@1+ (1,0) [0|15] ""  Motor_EDC17_D4,Motor_ME17_BY,Motor_MED17_SIMOS8_D4
 SG_ BCM2_Bremsl_durch_ECD : 5|1@1+ (1.0,0.0) [0.0|1] ""  Motor_EDC17_D4,Motor_ME17_BY,Motor_MED17_SIMOS8_D4
 SG_ LH_Aussenlicht_def : 7|1@1+ (1.0,0.0) [0.0|1] ""  Vector__XXX
 SG_ LH_Standlicht_H_aktiv : 8|1@1+ (1.0,0.0) [0.0|1] ""  Vector__XXX
 SG_ LH_Parklicht_HL_aktiv : 9|1@1+ (1.0,0.0) [0.0|1] ""  Vector__XXX
 SG_ LH_Parklicht_HR_aktiv : 10|1@1+ (1.0,0.0) [0.0|1] ""  Vector__XXX
 SG_ LH_Bremslicht_H_aktiv : 11|1@1+ (1.0,0.0) [0.0|1] ""  Vector__XXX
 SG_ LH_Nebelschluss_aktiv : 12|1@1+ (1.0,0.0) [0.0|1] ""  Vector__XXX
 SG_ LH_Rueckfahrlicht_aktiv : 13|1@1+ (1.0,0.0) [0.0|1] ""  Vector__XXX
 SG_ LH_Blinker_HL_akt : 14|1@1+ (1.0,0.0) [0.0|1] ""  Vector__XXX
 SG_ LH_Blinker_HR_akt : 15|1@1+ (1.0,0.0) [0.0|1] ""  Vector__XXX
 SG_ LH_Blinker_li_def : 16|1@1+ (1.0,0.0) [0.0|1] ""  Vector__XXX
 SG_ LH_Bremsl_li_def : 17|1@1+ (1.0,0.0) [0.0|1] ""  Vector__XXX
 SG_ LH_Schlusslicht_li_def : 18|1@1+ (1.0,0.0) [0.0|1] ""  Vector__XXX
 SG_ LH_Rueckf_li_def : 19|1@1+ (1.0,0.0) [0.0|1] ""  Vector__XXX
 SG_ LH_Nebel_li_def : 20|1@1+ (1.0,0.0) [0.0|1] ""  Vector__XXX
 SG_ LH_Schluss_Brems_Nebel_li_def : 21|1@1+ (1.0,0.0) [0.0|1] ""  Vector__XXX
 SG_ LH_Schluss_Brems_Nebel_re_def : 22|1@1+ (1.0,0.0) [0.0|1] ""  Vector__XXX
 SG_ LH_Schluss_Brems_li_def : 24|1@1+ (1.0,0.0) [0.0|1] ""  Vector__XXX
 SG_ LH_Schluss_Nebel_li_def : 25|1@1+ (1.0,0.0) [0.0|1] ""  Vector__XXX
 SG_ LH_SL_BRL_BLK_li_def : 26|1@1+ (1.0,0.0) [0.0|1] ""  Vector__XXX
 SG_ LH_Brems_Blk_li_def : 27|1@1+ (1.0,0.0) [0.0|1] ""  Vector__XXX
 SG_ LH_Blinker_re_def : 32|1@1+ (1.0,0.0) [0.0|1] ""  Vector__XXX
 SG_ LH_Bremsl_re_def : 33|1@1+ (1.0,0.0) [0.0|1] ""  Vector__XXX
 SG_ LH_Schlusslicht_re_def : 34|1@1+ (1.0,0.0) [0.0|1] ""  Vector__XXX
 SG_ LH_Rueckf_re_def : 35|1@1+ (1.0,0.0) [0.0|1] ""  Vector__XXX
 SG_ LH_Nebel_re_def : 36|1@1+ (1.0,0.0) [0.0|1] ""  Vector__XXX
 SG_ LH_Schluss_Brems_re_def : 40|1@1+ (1.0,0.0) [0.0|1] ""  Vector__XXX
 SG_ LH_Schluss_Nebel_re_def : 41|1@1+ (1.0,0.0) [0.0|1] ""  Vector__XXX
 SG_ LH_SL_BRL_BLK_re_def : 42|1@1+ (1.0,0.0) [0.0|1] ""  Vector__XXX
 SG_ LH_Brems_Blk_re_def : 43|1@1+ (1.0,0.0) [0.0|1] ""  Vector__XXX
 SG_ LH_Kennzl_def : 48|1@1+ (1.0,0.0) [0.0|1] ""  Vector__XXX
 SG_ LH_3_Bremsl_def : 49|1@1+ (1.0,0.0) [0.0|1] ""  Motor_EDC17_D4,Motor_ME17_BY,Motor_MED17_SIMOS8_D4
 SG_ LH_Nebel_mi_def : 50|1@1+ (1.0,0.0) [0.0|1] ""  Vector__XXX
 SG_ LH_Rueckf_mi_def : 51|1@1+ (1.0,0.0) [0.0|1] ""  Vector__XXX
 SG_ LH_Bremsl_li_ges_def : 54|1@1+ (1.0,0.0) [0.0|1] ""  Motor_EDC17_D4,Motor_ME17_BY,Motor_MED17_SIMOS8_D4
 SG_ LH_Bremsl_re_ges_def : 55|1@1+ (1.0,0.0) [0.0|1] ""  Motor_EDC17_D4,Motor_ME17_BY,Motor_MED17_SIMOS8_D4

VAL_ 159 EPS_HCA_Status 0 "disabled" 1 "initializing" 2 "fault" 3 "ready" 4 "rejected" 5 "active" ;
VAL_ 269 ACC_Freigabe_Momentenanf 0 "Momanf_nicht_freigegeben" 1 "Momanf_freigegeben" ;
VAL_ 269 ACC_Freigabe_Verzanf 0 "Verzanf_nicht_freigegeben" 1 "Verzanf_freigegeben" ;
VAL_ 269 ACC_Getriebestellung_P 0 "P_Stellung_nicht_angefordert" 1 "Anforderung_P_Stellung" ;
VAL_ 269 ACC_limitierte_Anfahrdyn 0 "keine_Limitierung" 1 "Limitierung_Anfahrdynamik_angefordert" ;
VAL_ 269 ACC_Loeseanforderung 0 "keine_Anforderung" 1 "Loeseanforderung" ;
VAL_ 269 ACC_StartStopp_Info 0 "Motorlauf_langfristig_nicht_notwendig_Stoppfreigabe" 1 "Motoranlauf_nicht_zwingend_notwendig_Stoppverbot_keine_Startanforderung" 2 "Motoranlauf_zwingend_notwendig_Startanforderung" 3 "Systemfehler" ;
VAL_ 269 ACC_Vorbefuellung_Bremsanlage 0 "Vorbefuellung_AUS" 1 "Vorbefuellung_EIN" ;
VAL_ 269 ACC_Status_ACC 0 "ACC_OFF_Hauptschalter_aus" 1 "ACC_INIT" 2 "ACC_STANDBY" 3 "ACC_AKTIV_regelt" 4 "ACC_OVERRIDE" 5 "nicht_definiert" 6 "reversibler_Fehler_im_ACC_System" 7 "irreversibler_Fehler_im_ACC_System" ;
VAL_ 269 ACC_Betaetigung_EPB 0 "keine_EPB_Anforderung" 1 "EPB_Aktuator_schliessen" ;
VAL_ 269 ACC_Beeinflussung_ESP 0 "keine_Zwangszuschaltung" 1 "ESP_Zwangszuschaltung" ;
VAL_ 269 ACC_Anhalten 0 "kein_Anhalten_gewuenscht" 1 "Anhalten_gewuenscht" ;
VAL_ 269 ACC_KD_Fehler 0 "kein_KD_Fehler" 1 "KD_Fehler" ;
VAL_ 64 AB_RGS_Anst 4 "aktiv_Niveau_1" 5 "aktiv_Niveau_2" 6 "aktiv_Niveau_3" 7 "aktiv_Niveau_4" 8 "deaktiviert" ;
VAL_ 64 AB_Front_Crash 0 "kein_Front_Crash" 1 "Front_Crash" ;
VAL_ 64 AB_Heck_Crash 0 "kein_Heck_Crash" 1 "Heck_Crash" ;
VAL_ 64 AB_SF_Crash 0 "kein_Seiten_Crash_Fahrer" 1 "Seiten_Crash_Fahrer" ;
VAL_ 64 AB_SB_Crash 0 "kein_Seiten_Crash_Beifahrer" 1 "Seiten_Crash_Beifahrer" ;
VAL_ 64 AB_Rollover_Crash 0 "kein_Rollover" 1 "Rollover" ;
VAL_ 64 AB_Crash_Int 0 "kein_Crash" 1 "Crash_Intensitaet_1" 2 "Crash_Intensitaet_2_(nur_Stellgliedtest_B8)" 3 "Crash_Intensitaet_2_(nur_D4_C7_Colorado_NF_PAG__Crash_im_B8)" 4 "Crash_Intensitaet_3_(alt_VW/AUDI__Stellgiedtest_B8)" 5 "Crash_Intensitaet_3_(alt_PAG)" 7 "Crash_Intensitaet_3" ;
VAL_ 64 AB_Lampe 0 "Aus" 1 "Ein" ;
VAL_ 64 AB_Deaktiviert 0 "aktiv" 1 "deaktiviert" ;
VAL_ 64 AB_VB_deaktiviert 0 "Beifahrerairbag_aktiv" 1 "Beifahrerairbag_deaktiviert" ;
VAL_ 64 AB_Systemfehler 0 "kein_Fehler" 1 "Airbag_Systemfehler" ;
VAL_ 64 AB_Diagnose 0 "nicht_in_Diagnose" 1 "in_Diagnose" ;
VAL_ 64 AB_Stellgliedtest 0 "nicht_im_Stellgliedtest" 1 "Airbag_im_Stellgliedtest" ;
VAL_ 64 AB_Erh_Auf_VB 0 "keine_Anzeige" 1 "Beifahrerairbag_deaktiviert" 2 "Beifahrerairbag_aktiviert" 3 "nicht_definiert" ;
VAL_ 64 AB_Gurtwarn_VF 0 "keine_Warnung" 1 "Gurtwarnung_ausloesen" ;
VAL_ 64 AB_Gurtwarn_VB 0 "keine_Warnung" 1 "Gurtwarnung_ausloesen" ;
VAL_ 64 AB_Anzeige_Fussg 0 "keine_FSG_Aktion_ausgeloest" 1 "Motorhaube_offen" 2 "Systemfehler" ;
VAL_ 64 AB_Texte_AKS 0 "keine_AKS_Ausloesung" 1 "AKS_ausgeloest" 2 "AKS_Systemfehler" ;
VAL_ 64 AB_PAO_Leuchte_Anf 0 "Leuchte_ausschalten" 1 "Leuchte_einschalten" ;
VAL_ 64 AB_MKB_gueltig 0 "Multikollisionsbremsung_nicht_freigeschaltet" 1 "Multikollisionsbremsung_freigeschaltet" ;
VAL_ 64 AB_MKB_Anforderung 0 "Multikollisionsbremsung_nicht_angefordert" 1 "Multikollisionsbremsung_angefordert" ;
VAL_ 64 AB_Versorgungsspannung 0 "plausibel" 1 "unplausibel" ;
VAL_ 64 AB_KD_Fehler 0 "kein_KD_Fehler" 1 "KD_Fehler" ;
VAL_ 1312 AB_Belegung_VB 0 "nicht_verfuegbar" 1 "Fehler" 2 "nicht_belegt" 3 "belegt" ;
VAL_ 1312 AB_Gurtschloss_FA 0 "nicht_verbaut" 1 "nicht_verf�gbar (Fehler oder Init)" 2 "nicht_gesteckt" 3 "gesteckt" ;
VAL_ 1312 AB_Gurtschloss_BF 0 "nicht_verbaut" 1 "nicht_verf�gbar (Fehler oder Init)" 2 "nicht_gesteckt" 3 "gesteckt" ;
VAL_ 1312 AB_Gurtschloss_Reihe2_FA 0 "nicht_verbaut" 1 "nicht_verf�gbar (Fehler oder Init)" 2 "nicht_gesteckt" 3 "gesteckt" ;
VAL_ 1312 AB_Gurtschloss_Reihe2_MI 0 "nicht_verbaut" 1 "nicht_verf�gbar (Fehler oder Init)" 2 "nicht_gesteckt" 3 "gesteckt" ;
VAL_ 1312 AB_Gurtschloss_Reihe2_BF 0 "nicht_verbaut" 1 "nicht_verf�gbar (Fehler oder Init)" 2 "nicht_gesteckt" 3 "gesteckt" ;
VAL_ 1312 AB_Gurtschloss_Reihe3_FA 0 "nicht_verbaut" 1 "nicht_verf�gbar (Fehler oder Init)" 2 "nicht_gesteckt" 3 "gesteckt" ;
VAL_ 1312 AB_Gurtschloss_Reihe3_MI 0 "nicht_verbaut" 1 "nicht_verf�gbar (Fehler oder Init)" 2 "nicht_gesteckt" 3 "gesteckt" ;
VAL_ 1312 AB_Gurtschloss_Reihe3_BF 0 "nicht_verbaut" 1 "nicht_verf�gbar (Fehler oder Init)" 2 "nicht_gesteckt" 3 "gesteckt" ;
VAL_ 1312 AB_Sitzpos_Sens_FA 0 "nicht verf�gbar" 1 "Fehler" 2 "Sitz nicht vorne" 3 "Sitz vorne" ;
VAL_ 1312 AB_Sitzpos_Sens_BF 0 "nicht verf�gbar" 1 "Fehler" 2 "Sitz nicht vorne" 3 "Sitz vorne" ;
VAL_ 1633 AAG_Bremsl_durch_ECD 0 "Bremslicht_ist_aus" 1 "Bremslicht_durch_ECD_aktiv" ;
VAL_ 1633 AAG_Anhaenger_abgesteckt 1 "Anhaenger_wurde_bei_KL15_aus_abgesteckt" ;
VAL_ 1633 AAG_NSL_aktiv 1 "Anhaenger_Nebelschusslicht_aktiv" ;
VAL_ 1633 AAG_Anhaenger_erkannt 0 "kein_Anhaenger_erkannt" 1 "AAG_Anhaenger_erkannt" ;
VAL_ 1633 AAG_Blinker_H_aktiv 1 "Anhaenger_Blinker_aktiv" ;
VAL_ 1633 AAG_Blinker_HL_def 1 "Anhaenger_Blinker_links_defekt" ;
VAL_ 1633 AAG_Blinker_HR_def 1 "Anhaenger_Blinker_rechts_defekt" ;
VAL_ 1633 AAG_Bremslicht_H_def 1 "Anhaenger_Bremslicht_defekt" ;
VAL_ 1633 AAG_Schlusslicht_HL_def 1 "Anhaenger_Schlusslicht_links_defekt" ;
VAL_ 1633 AAG_Schlusslicht_HR_def 1 "Anhaenger_Schlusslicht_rechts_defekt" ;
VAL_ 1633 AAG_KD_Fehler 0 "kein_KD_Fehler" 1 "KD_Fehler" ;
VAL_ 1633 AAG_AVS_Fehler 0 "iO" 1 "niO" 2 "niO_Fahrzeugstopp_erforderlich" 3 "tbd" ;
VAL_ 1633 AAG_AVS_Stati 0 "endlage eingefahren erreicht" 1 "endlage ausgefahren erreicht" 2 "ausfahren automatik " 3 "einfahren automatik" 4 "ausfahren manuell " 5 "einfahren manuell" 6 "zwischenposition" 7 "nicht initialisiert" ;
VAL_ 777 BEM_Segel_Info 0 "keine_Anforderung" 1 "Mindestdrehzahl_1" 2 "Mindestdrehzahl_2" 3 "Segelveto" ;
VAL_ 777 BEM_P_Generator 255 "Fehler" ;
VAL_ 777 BEM_n_LLA 0 "keine_Erhoehung" 1 "Stufe_1" 2 "Stufe_2" 3 "Stufe_3" ;
VAL_ 777 BEM_01_Abschaltstufen 0 "Stufe_0_keine_Einschraenkung" 1 "Stufe_1" 2 "Stufe_2" 3 "Stufe_3" 4 "Transportmodus" 7 "Ruhestrommessmodus" ;
VAL_ 777 BEM_Anf_KL 0 "keine Anforderung" 1 "Anforderung K�hlerl�fter Ansteuerung" ;
VAL_ 777 BEM_StartStopp_Info 0 "Motorlauf_nicht_notwendig_(Stoppfreigabe)" 1 "Motoranlauf_nicht_zwingend_notwendig_(Stoppverbot,keine_Startanforderung)" 2 "Motoranlauf_zwingend_notwendig_(Startanforderung)" 3 "Systemfehler" ;
VAL_ 901 CHA_Systemstatus 0 "Status in Ordnung" 1 "reserviert" 2 "reserviert" 3 "reserviert" ;
VAL_ 901 CHA_Fahrer_Umschaltung 0 "keine_oder_automatische Umschaltung" 1 "manuelle_Umschaltung" ;
VAL_ 901 CHA_Ziel_FahrPr_MO 0 "nicht_belegt" 1 "Programm_1" 2 "Programm_2" 3 "Programm_3" 4 "Programm_4" 5 "Programm_5" 6 "Programm_6" 7 "Programm_7" ;
VAL_ 901 CHA_Ziel_FahrPr_GE 0 "nicht_belegt" 1 "Programm_1" 2 "Programm_2" 3 "Programm_3" 4 "Programm_4" 5 "Programm_5" 6 "Programm_6" 7 "Programm_7" ;
VAL_ 901 CHA_Ziel_FahrPr_ST 0 "nicht_belegt" 1 "Programm_1" 2 "Programm_2" 3 "Programm_3" 4 "Programm_4" 5 "Programm_5" 6 "Programm_6" 7 "Programm_7" ;
VAL_ 901 CHA_Ziel_FahrPr_SCU 0 "nicht_belegt" 1 "Programm_1" 2 "Programm_2" 3 "Programm_3" 4 "Programm_4" 5 "Programm_5" 6 "Programm_6" 7 "Programm_7" ;
VAL_ 901 CHA_Ziel_FahrPr_DR 0 "nicht_belegt" 1 "Programm_1" 2 "Programm_2" 3 "Programm_3" 4 "Programm_4" 5 "Programm_5" 6 "Programm_6" 7 "Programm_7" ;
VAL_ 901 CHA_Ziel_FahrPr_QS 0 "nicht_belegt" 1 "Programm_1" 2 "Programm_2" 3 "Programm_3" 4 "Programm_4" 5 "Programm_5" 6 "Programm_6" 7 "Programm_7" ;
VAL_ 901 CHA_Ziel_FahrPr_AFS 0 "nicht_belegt" 1 "Programm_1" 2 "Programm_2" 3 "Programm_3" 4 "Programm_4" 5 "Programm_5" 6 "Programm_6" 7 "Programm_7" ;
VAL_ 901 CHA_Ziel_FahrPr_RGS 0 "nicht_belegt" 1 "Programm_1" 2 "Programm_2" 3 "Programm_3" 4 "Programm_4" 5 "Programm_5" 6 "Programm_6" 7 "Programm_7" ;
VAL_ 901 CHA_Ziel_FahrPr_EPS 0 "nicht_belegt" 1 "Programm_1" 2 "Programm_2" 3 "Programm_3" 4 "Programm_4" 5 "Programm_5" 6 "Programm_6" 7 "Programm_7" ;
VAL_ 901 CHA_Ziel_FahrPr_ACC 0 "nicht_belegt" 1 "Programm_1" 2 "Programm_2" 3 "Programm_3" 4 "Programm_4" 5 "Programm_5" 6 "Programm_6" 7 "Programm_7" ;
VAL_ 901 CHA_Ziel_FahrPr_SAK 0 "nicht_belegt" 1 "Programm_1" 2 "Programm_2" 3 "Programm_3" 4 "Programm_4" 5 "Programm_5" 6 "Programm_6" 7 "Programm_7" ;
VAL_ 1714 DGN_Verlernzaehler 255 "ung�ltiger Z�hlerstand oder kein g�ltiger Fahrzyklus" ;
VAL_ 1714 KBI_Kilometerstand 1048574 "Init" 1048575 "Fehler" ;
VAL_ 1714 UH_Monat 14 "reserviert" ;
VAL_ 1714 UH_Tag 0 "reserviert" ;
VAL_ 1714 Kombi_02_alt 0 "aktuell" 1 "veraltet" ;
VAL_ 1714 Uhrzeit_01_alt 0 "aktuell" 1 "veraltet" ;
VAL_ 1520 DI_KL_58d 254 "Init" 255 "Fehler" ;
VAL_ 1520 DI_KL_58s 126 "Init" 127 "Fehler" ;
VAL_ 1520 DI_KL_58st 126 "Init" 127 "Fehler" ;
VAL_ 1603 KBI_Einheit_Datum 0 "Tag/Monat/Jahr" 1 "Monat/Tag/Jahr" 2 "Jahr/Monat/Tag" 3 "reserviert" ;
VAL_ 1603 KBI_Einheit_Druck 0 "Druckangabe in bar" 1 "Druckangabe in psi" 2 "Druckangabe in kPa" 3 "tbd." ;
VAL_ 1603 KBI_Einheit_Streckenanz 0 "Kilometer" 1 "Meilen" ;
VAL_ 1603 KBI_MFA_v_Einheit_02 0 "kmh" 1 "mph" ;
VAL_ 1603 KBI_Einheit_Temp 0 "Grad Celsius �C" 1 "Grad Fahrenheit �F" ;
VAL_ 1603 KBI_Einheit_Uhrzeit 0 "24h" 1 " 12h AM/PM" ;
VAL_ 1603 KBI_Einheit_Verbrauch 0 "mpg UK" 1 "mpg USA" 2 "Liter/100km" 3 "km/Liter" ;
VAL_ 1603 KBI_Einheit_Volumen 0 "Liter" 1 "Gallonen UK" 2 "Gallonen USA" 3 "reserviert" ;
VAL_ 260 EPB_QBit_Laengsbeschleunigung 0 "g�ltiger Wert" 1 "Ersatz-, Init- oder Fehlerwert" ;
VAL_ 260 EPB_QBit_Pedalweg_Kuppl 0 "g�ltiger Wert" 1 "Ersatz-, Init- oder Fehlerwert" ;
VAL_ 260 EPB_BCM2_Motor_Wakeup 0 "keine Anforderung" 1 "Anforderung an BCM2 Wakeupleitung zum Motor hochzuziehen aufgrund von Car-Wakeup" ;
VAL_ 260 EPB_Freig_Verzoeg_Anf 0 "nicht freigegeben" 1 "freigegeben" ;
VAL_ 260 EPB_Laengsbeschleunigung 255 "Fehler" ;
VAL_ 260 EPB_Pedalweg_Kuppl 0 "Init" 255 "Fehler" ;
VAL_ 260 EPB_Anfahrwunsch_erkannt 0 "kein Anfahrwunsch erkannt" 1 "Anfahrwunsch erkannt" ;
VAL_ 260 EPB_DAA_Randbed_erf 0 "Randbed_nicht_erfuellt" 1 "Randbed_erfuellt" ;
VAL_ 260 EPB_Fehlerstatus 0 "kein Fehler in EPB - AVH darf von ESP ausgef�hrt werden" 1 "nur VW526: tempor�rer Fehler" 2 "nur VW526: EPB in Diagnose" 3 "Fehler in EPB - AVH darf von ESP nicht ausgef�hrt werden" ;
VAL_ 260 EPB_Schalterposition 0 "keine Fahreranforderung" 1 "Fahreranforderung �ffnen" 2 "Fahreranforderung Schlie�en" 3 "Fehler" ;
VAL_ 260 EPB_QBit_Schalterpos 0 "g�ltiger Wert (volle Funktion)" 1 " Ersatz-, Init- oder Fehlerwert (Schalter ausser Funktion)" ;
VAL_ 260 EPB_Konsistenz_ACC 0 "kein Fehler erkannt" 1 "Fehler erkannt" ;
VAL_ 260 EPB_Spannkraft 30 "Init" 31 "Fehler" ;
VAL_ 260 EPB_Status 0 "offen" 1 "Bremse_geschl_(Spannkraft_voll/reduziert)" 2 "Aktuator im Lauf" 3 "Fehler" ;
VAL_ 260 EPB_KD_Fehler 0 "kein_KD_Fehler" 1 "KD_Fehler" ;
VAL_ 781 EPB_Fehlerlampe_Gelb 0 "Aus" 1 "Ein" ;
VAL_ 781 EPB_Fehlerlampe_BKL 0 "BKL aus" 1 "BKL an" ;
VAL_ 781 EPB_Funktionslampe 0 "Aus" 1 "Ein" ;
VAL_ 781 EPB_Texte 0 "keine_Anzeige" 1 "Neigungswinkel_zu_gross" 2 "Parkbremse_von_Hand_oeffnen" 3 "EPB_in_Diagnose" 4 "Bremspedal_betaetigen" 5 "tbd." 6 "tbd." 7 "St�rung Anfahrassistent" 8 "Abschleppschutz blockiert" ;
VAL_ 781 EPB_Akustik 0 "Warnton aus" 1 "Warnton an" ;
VAL_ 781 EPB_Autoholdlampe 0 "Lampe aus (Autohold inaktiv)" 1 "Lampe ein (Autohold aktiv)" ;
VAL_ 781 EPB_Bremsbelag_Warn 0 "Bremsbelag_ok" 1 "Bremsbelag_unter_Minimum" ;
VAL_ 256 ASR_Moment_langsam 1022 "Init" 1023 "Fehler" ;
VAL_ 256 ASR_MSR_Moment_schnell 1022 "Init" 1023 "Fehler" ;
VAL_ 256 ESP_v_Signal 65533 "Unterspannung" 65534 "Init" 65535 "Fehler" ;
VAL_ 256 ASR_Tastung_passiv 0 "ASR_aktiviert" 1 "ASR_passiv_getastet_oder_Schwellen_geaendert" ;
VAL_ 256 ESP_Tastung_passiv 0 "ESP_aktiviert" 1 "ESP_passiv_getastet_oder_Schwellen_geaendert" ;
VAL_ 256 ESP_Systemstatus 0 "iO" 1 "Fehler" ;
VAL_ 256 ASR_Schalteingriff 0 "keine Anforderung" 1 "ASR_Schaltkennfeld" 2 "R�ckschaltung" 3 "Schaltverbot" ;
VAL_ 256 OBD_Schlechtweg 0 "kein Schlechtweg erkannt" 1 "Schlechtweg erkannt" ;
VAL_ 256 OBD_QBit_Schlechtweg 0 "gueltiger_Wert" 1 "Ersatz_Init_oder_Fehlerwert" ;
VAL_ 256 ESP_QBit_v_Signal 0 "gueltiger_Wert" 1 "Ersatz_Init_oder_Fehlerwert" ;
VAL_ 256 ABS_Bremsung 0 "keine_ABS_Regelung" 1 "ABS_Regelung_aktiv" ;
VAL_ 256 ASR_Anf 0 "keine_Anforderung" 1 "ASR_Anforderung" ;
VAL_ 256 MSR_Anf 0 "keine Anfoderung" 1 "MSR-Anforderung" ;
VAL_ 256 EBV_Eingriff 0 "kein EBV-Eingriff" 1 "EBV-Eingriff" ;
VAL_ 256 EDS_Eingriff 0 "kein_EDS_Eingriff" 1 "EDS_Eingriff" ;
VAL_ 256 ESP_Eingriff 0 "kein_ESP_Eingriff" 1 "ESP_Eingriff_aktiv" ;
VAL_ 256 ESP_ASP 0 "inaktiv" 1 "aktiv" ;
VAL_ 256 ESP_KD_Fehler 0 "kein_KD_Fehler" 1 "KD_Fehler" ;
VAL_ 257 ESP_QBit_Gierrate 0 "gueltiger_Wert" 1 "Ersatz_Init_oder_Fehlerwert" ;
VAL_ 257 ESP_QBit_Laengsbeschl 0 "gueltiger_Wert" 1 "Ersatz_Init_oder_Fehlerwert" ;
VAL_ 257 ESP_QBit_Querb 0 "gueltiger_Wert" 1 "Ersatz_Init_oder_Fehlerwert" ;
VAL_ 257 ESP_Stillstandsflag 0 "kein_Stillstand_erkannt" 1 "Stillstand_erkannt" ;
VAL_ 257 ESP_Querbeschleunigung 255 "Fehler" ;
VAL_ 257 ESP_Laengsbeschl 1022 "Signal_nicht_vorhanden" 1023 "Fehler" ;
VAL_ 257 ESP_Verteil_Wankmom 30 "Init" 31 "Fehler" ;
VAL_ 257 ESP_QBit_Anf_Vert_Wank 0 "gueltiger_Wert" 1 "Ersatz_Init_oder_Fehlerwert" ;
VAL_ 257 ESP_Gierrate 16383 "Fehler" ;
VAL_ 257 ESP_VZ_Gierrate 0 "positiv" 1 "negativ" ;
VAL_ 257 ESP_Notbremsanzeige 0 "keine_Notbremsung_erkannt" 1 "Notbremsung_erkannt" ;
VAL_ 257 ESP_SpannungsAnf 0 "keine_Anforderung" 1 "Anforderung_Spannungswert_1" ;
VAL_ 257 ESP_PLA_Abbruch 0 "Init" 1 "Geschwindigkeitsueberschreitung" 2 "Falscher_PLA_Status" 3 "Deaktivierung_durch_Abbruch_Lenkung" 4 "PLA_Bremsanforderung_nach_Stillstand" 5 "Abbruch_durch_Kl15_aus" 6 "Abbruch_durch_FT_offen" ;
VAL_ 257 ESP_Status_ESP_PLA 0 "ESP_PLA_deaktiv" 1 "ESP_PLA_Init" 2 "ESP_PLA_Fehler" 4 "ESP_PLA_aktivierbar" 6 "ESP_PLA_Bremse_aktiv" 8 "ESP_PLA_funktionsbereit" 9 "ESP_PLA_Neustart" 10 "ESP_PLA_Abbruch" ;
VAL_ 259 ESP_VL_FR 0 "Vorwaerts" 1 "Rueckwaerts" ;
VAL_ 259 ESP_VR_FR 0 "Vorwaerts" 1 "Rueckwaerts" ;
VAL_ 259 ESP_HL_FR 0 "Vorwaerts" 1 "Rueckwaerts" ;
VAL_ 259 ESP_HR_FR 0 "Vorwaerts" 1 "Rueckwaerts" ;
VAL_ 259 ESP_VL_Radgeschw 4093 "Unterspannung" 4094 "Init" 4095 "Fehler" ;
VAL_ 259 ESP_VR_Radgeschw 4093 "Unterspannung" 4094 "Init" 4095 "Fehler" ;
VAL_ 259 ESP_HL_Radgeschw 4093 "Unterspannung" 4094 "Init" 4095 "Fehler" ;
VAL_ 259 ESP_HR_Radgeschw 4093 "Unterspannung" 4094 "Init" 4095 "Fehler" ;
VAL_ 776 ESP_Meldungen 0 "keine_Anzeige_kein_Gong" 1 "Autohold_Hinweis_1_und_kein_Gong" 2 "Stoerung_Autohold_und_1x_Gong" 3 "Stoerung_Hillholder_und_1x_Gong" 4 "Uebernehmen_und_1x_Gong" ;
VAL_ 776 ESP_HDC_FktLampe 0 "Aus" 1 "Ein" ;
VAL_ 776 ESP_Lampe 0 "Aus" 1 "Ein" ;
VAL_ 776 ABS_Lampe 0 "Aus" 1 "Ein" ;
VAL_ 776 BK_Lampe 0 "Aus" 1 "Ein" ;
VAL_ 776 ESP_Akustik 0 "keine_Akustik" 1 "1x_Beep" ;
VAL_ 776 ESP_Diagnose 0 "ESP_nicht_in_Diagnose" 1 "ESP_in_Diagnose" ;
VAL_ 776 ESP_Textanzeigen_02 0 "kein_Text" 1 "ESP_Stoerung" 2 "ABS_Stoerung" 3 "ESP_ABS_Stoerung" 4 "nicht_definiert" 5 "ASR_Stoerung" 6 "ESP_switched_off" 7 "ASR_off" 8 "ESP_ASR_on" 9 "Stoerung_Hillholder" 10 "keine_Bremskraftverstaerkung" 11 "ASR_aktiviert" 12 "ABS_ASR_Stoerung" 13 "bitte_Reifen_pruefen" 14 "Stoerung_Autohold" 15 "ESP_offroad" 16 "Autohold_Hinweis_1" 17 "ESP_sport" 18 "ESP_Zwangsaktivierung" ;
VAL_ 776 ESP_Off_Lampe 0 "Lampe_aus" 1 "Lampe_ein" ;
VAL_ 776 ESP_m_Raddrehz 32765 "Unterspannung" 32766 "Init" 32767 "Fehler" ;
VAL_ 776 ESP_ASR_Lampe 0 "ESP_ASR_Lampe_aus" 1 "ESP_ASR_Lampe_an" ;
VAL_ 776 ESP_Fehlerstatus_Wegimp 0 "Wegimpulse_iO" 1 "Fehler" ;
VAL_ 776 ESP_Wegimp_Ueberlauf 0 "Reset und kein �berlauf" 1 "mindestens 1x �berlauf" ;
VAL_ 776 ESP_QBit_Wegimp_VA 0 "gueltiger_Wert" 1 "Ersatz_Init_oder_Fehlerwert" ;
VAL_ 776 ESP_Displaywarnungen 0 "keine_Warnung" 1 "BKL_Display_Warnung" ;
VAL_ 776 ESP_HDC_Regelgeschw 0 "nicht_verbaut" 125 "HDC_Standby" 127 "Fehler" ;
VAL_ 776 ESP_BKV_Warnung 0 "keine_Anzeige_kein_Gong" 1 "keine_Bremskraftverstaerkung_plus_1x_Gong" ;
VAL_ 262 ESP_QBit_Bremsdruck 0 "gueltiger_Wert" 1 "Ersatz_Init_oder_Fehlerwert" ;
VAL_ 262 ESP_QBit_Fahrer_bremst 0 "gueltiger_Wert" 1 "Ersatz_Init_oder_Fehlerwert" ;
VAL_ 262 ESP_Schwelle_Unterdruck 0 "kein_Signal" 1 "Unterdruck_kleiner_gleich_450_mbar" 2 "Unterdruck_groesser_450_mbar" 3 "Fehler_Unterdrucksensor" ;
VAL_ 262 ESP_Bremsdruck 1023 "Fehler" ;
VAL_ 262 ESP_Fahrer_bremst 0 "Bremsdruckschwelle_nicht_ueberschritten" 1 "Bremsdruckschwelle_ueberschritten" ;
VAL_ 262 ESP_Verz_TSK_aktiv 0 "TSK_Verzoegerung_inaktiv" 1 "TSK_Verzoegerung_aktiv" ;
VAL_ 262 ESP_Lenkeingriff_ADS 0 "kein_Lenkeingriff" 1 "stabilisierender_Lenkeingriff" ;
VAL_ 262 ESP_Konsistenz_TSK 0 "Botschaft_fuer_Verzoegerungsanforderung_konsistent" 1 "Botschaft_fuer_Verzoegerungsanforderung_nicht_konsistent" ;
VAL_ 262 ESP_Bremsruck_AWV2 0 "kein_Bremsruck_ausgefuehrt" 1 "Bremsruck_ausgefuehrt" ;
VAL_ 262 ESP_Konsistenz_AWV2 0 "Botschaft_fuer_AWV2_konsistent" 1 "Botschaft_fuer_AWV2_nicht_konsistent" ;
VAL_ 262 ECD_Fehler 0 "ECD_iO" 1 "ECD_Fehler" ;
VAL_ 262 ECD_nicht_verfuegbar 0 "ECD_Funktion_verfuegbar" 1 "ECD_Funktion_nicht_verfuegbar" ;
VAL_ 262 ESP_Status_Bremsentemp 0 "Bremse nicht �berhitzt" 1 "Bremse �berhitzt" ;
VAL_ 262 ESP_Autohold_Standby 0 "Autohold_nicht_im_Standby" 1 "Autohold_im_Standby" ;
VAL_ 262 ESP_HDC_Standby 0 "HDC_Funktion_nicht_im_Standby" 1 "HDC_Funktion_im_Standby" ;
VAL_ 262 ESP_HBA_aktiv 0 "HBA_nicht_aktiv" 1 "HBA_aktiv" ;
VAL_ 262 ESP_Prefill_ausgeloest 0 "nicht_ausgeloest" 1 "Prefill_ausgeloest" ;
VAL_ 262 ESP_Rueckwaertsfahrt_erkannt 0 "keine_Rueckwaetsfahrt" 1 "Rueckwaertsfahrt_erkannt" ;
VAL_ 262 ESP_Status_Anfahrhilfe 0 "Aus" 1 "Ein" ;
VAL_ 262 ESP_HDC_aktiv 0 "inaktiv" 1 "aktiv" ;
VAL_ 262 ESP_StartStopp_Info 0 "Motorlauf_nicht_notwendig_(Stoppfreigabe)" 1 "Motoranlauf_nicht_zwingend_notwendig_(Stoppverbot,keine_Startanforderung)" 2 "Motoranlauf_zwingend_notwendig_(Startanforderung)" 3 "Systemfehler" ;
VAL_ 262 ESP_Eingr_HL 0 "kein_Eingriff" 1 "ESP_Eingriff_HL" ;
VAL_ 262 ESP_Eingr_HR 0 "kein_Eingriff" 1 "ESP_Eingriff_HR" ;
VAL_ 262 ESP_Eingr_VL 0 "kein_Eingriff" 1 "ESP_Eingriff_VL" ;
VAL_ 262 ESP_Eingr_VR 0 "kein_Eingriff" 1 "ESP_Eingriff_VR" ;
VAL_ 262 ESP_BKV_Unterdruck 255 "Fehler" ;
VAL_ 262 ESP_Autohold_aktiv 0 "Autohold inaktiv" 1 "Autohold aktiv" ;
VAL_ 262 ESP_FStatus_Anfahrhilfe 0 "kein_Fehler" 1 "Fehler" ;
VAL_ 262 ESP_Verz_EPB_aktiv 0 "nicht aktiviert" 1 "aktiviert" ;
VAL_ 262 ECD_Bremslicht 0 "Aus" 1 "Ein" ;
VAL_ 262 ESP_Verzoeg_EPB_verf 0 "nicht verfuegbar" 1 "System verfuegbar" ;
VAL_ 262 ESP_Status_Bremsdruck 0 "Bremse drucklos" 1 "mit Bremsdruck" ;
VAL_ 262 ESP_Anforderung_EPB 0 "keine_Anforderung" 1 "Anforderung_Oeffnen" 2 "Anforderung_Schliessen" 3 "reserviert" ;
VAL_ 132 ESP_06_KD_Fehler 0 "kein_KD_Fehler" 1 "KD_Fehler" ;
VAL_ 132 ESP_VZ_Teilsollwinkel 0 "positiv" 1 "negativ" ;
VAL_ 132 ESP_Winkeleingriff 0 "kein Eingriff" 1 "Eingriff mit langsamer R�ckf�hrung" 2 "Eingriff mit mittlerer R�ckf�hrung" 3 "Eingriff mit schneller R�ckf�hrung" ;
VAL_ 132 ESP_Status_ADS 0 "ADS iO" 1 "ADS noch nicht verf�gbar" 2 "ADS tempor�r nicht verf�gbar" ;
VAL_ 132 ESP_v_ref 4093 "Unterspannung" 4095 "Fehler" ;
VAL_ 914 ESP_ACC_LDE 0 "Lebensdauerende_nicht_erreicht" 1 "Lebensdauerende_erreicht" ;
VAL_ 914 ESP_Quattro_Antrieb 0 "Front" 1 "Allrad" ;
VAL_ 914 ESP_Codierung_ADS 0 "Init" 1 "ESP_nicht_ADS_codiert" 2 "ADS_codiert" 3 "tbd" ;
VAL_ 914 ESP_RTA_HL 254 "Abgleich_nocht_nicht_genuegend_konvergent" 255 "Fehler" ;
VAL_ 914 ESP_RTA_HR 254 "Abgleich_nocht_nicht_genuegend_konvergent" 255 "Fehler" ;
VAL_ 914 ESP_RTA_VR 254 "Abgleich_nocht_nicht_genuegend_konvergent" 255 "Fehler" ;
VAL_ 914 OBD_Fehler_Radsensor_HL 0 "kein_Fehler" 1 "KS-" 2 "KS+" 3 "OC" 4 "OOR+" 5 "OOR-" 6 "RC+" 7 "RC-" 8 "KS+/OC" 9 "KS-/OC" 10 "KS-/KS+" 11 "KS-/KS+/OC" 12 "frei" 13 "frei" 14 "frei" 15 "frei" ;
VAL_ 914 OBD_Fehler_Radsensor_HR 0 "kein_Fehler" 1 "KS-" 2 "KS+" 3 "OC" 4 "OOR+" 5 "OOR-" 6 "RC+" 7 "RC-" 8 "KS+/OC" 9 "KS-/OC" 10 "KS-/KS+" 11 "KS-/KS+/OC" 12 "frei" 13 "frei" 14 "frei" 15 "frei" ;
VAL_ 914 OBD_Fehler_Radsensor_VL 0 "kein_Fehler" 1 "KS-" 2 "KS+" 3 "OC" 4 "OOR+" 5 "OOR-" 6 "RC+" 7 "RC-" 8 "KS+/OC" 9 "KS-/OC" 10 "KS-/KS+" 11 "KS-/KS+/OC" 12 "frei" 13 "frei" 14 "frei" 15 "frei" ;
VAL_ 914 OBD_Fehler_Radsensor_VR 0 "kein_Fehler" 1 "KS-" 2 "KS+" 3 "OC" 4 "OOR+" 5 "OOR-" 6 "RC+" 7 "RC-" 8 "KS+/OC" 9 "KS-/OC" 10 "KS-/KS+" 11 "KS-/KS+/OC" 12 "frei" 13 "frei" 14 "frei" 15 "frei" ;
VAL_ 914 ESP_Qualifizierung_Antriebsart 0 "alte_Bedeutung_Bit_ESP_Quattro_Antrieb" 1 "neue_Bedeutung_Bit_ESP_Quattro_Antrieb" ;
VAL_ 914 ESP_Offroad_Modus 0 "kein_ESP_Offroadmodus" 1 "ESP_Offroadmodus" ;
VAL_ 914 ESP_MKB_ausloesbar 0 "Multikollisionsbremsung_nicht_freigeschaltet" 1 "Multikollisionsbremsung_freigeschaltet" ;
VAL_ 914 ESP_MKB_Status 0 "Multikollisionsbremsung_nicht_aktiv" 1 "Multikollisionsbremsung_aktiv" ;
VAL_ 914 ESP_CM_Variante 0 "Standard" 1 "Erweitert" ;
VAL_ 914 ESP_OBD_Status 0 "MIL_aus" 1 "MIL_ein" ;
VAL_ 1623 ESP_BremsenTemp_hinten 0 "Temp_kleiner_99GradC" 1 "Temp_zwischen_100-199GradC" 2 "Temp_zwischen_200-299GradC" 3 "Temp_zwischen_300-399GradC" 4 "Temp_zwischen_400-499GradC" 5 "Temp_zwischen_500-599GradC" 6 "Temp_groesser_599GradC" 7 "Fehler" ;
VAL_ 924 BCM1_02_alt 0 "aktuell" 1 "veraltet" ;
VAL_ 924 Wischer_01_alt 0 "aktuell" 1 "veraltet" ;
VAL_ 924 Klima_02_alt 0 "aktuell" 1 "veraltet" ;
VAL_ 924 BCM1_01_alt 0 "aktuell" 1 "veraltet" ;
VAL_ 924 ESP_07_alt 0 "aktuell" 1 "veraltet" ;
VAL_ 924 TSG_BT_1_alt 0 "aktuell" 1 "veraltet" ;
VAL_ 924 TSG_HL_1_alt 0 "aktuell" 1 "veraltet" ;
VAL_ 924 TSG_HR_1_alt 0 "aktuell" 1 "veraltet" ;
VAL_ 924 Motor_02_alt 0 "aktuell" 1 "veraltet" ;
VAL_ 924 Klima_Sensor_02_alt 0 "aktuell" 1 "veraltet" ;
VAL_ 924 TSG_FT_1_alt 0 "aktuell" 1 "veraltet" ;
VAL_ 924 Motor_05_alt 0 "aktuell" 1 "veraltet" ;
VAL_ 924 QSP_01_alt 0 "aktuell" 1 "veraltet" ;
VAL_ 924 Parkhilfe_01_alt 0 "aktuell" 1 "veraltet" ;
VAL_ 924 Fahrwerk_02_alt 0 "aktuell" 1 "veraltet" ;
VAL_ 924 BCM1_MH_WIV_Schalter 0 "MH_geschlossen" 1 "MH_offen" ;
VAL_ 924 Wischer_vorne_aktiv 1 "Wischer vorne l�uft" ;
VAL_ 924 BCM1_Rueckfahrlicht_Schalter 0 "aus" 1 "betaetigt" ;
VAL_ 924 MO_Status_Normalbetrieb_01 0 "kein Normalbetrieb" 1 "Normalbetrieb erreicht" ;
VAL_ 924 KL_Zuheizer_Freigabe 0 "keine_Freigabe_Zuheizer" 1 "Zuheizerfreigabe" ;
VAL_ 924 BCM1_Vorwaertsgang_eingelegt 0 "Rueckwaertsgang bzw. restliche Gaenge eingelegt" 1 "Erster oder zweiter Gang eingelegt" ;
VAL_ 924 ESP_Codierung_ADS 0 "Init" 1 "ESP_nicht_ADS_codiert" 2 "ADS_codiert" 3 "tbd" ;
VAL_ 924 QSP_StartStopp_Info 0 "Motorlauf_nicht_notwendig_(Stoppfreigabe)" 1 "Motoranlauf_nicht_zwingend_notwendig_(Stoppverbot,keine_Startanforderung)" 2 "Motoranlauf_zwingend_notwendig_(Startanforderung)" 3 "Systemfehler" ;
VAL_ 924 FA_StartStopp_Info 0 "Motorlauf_nicht_notwendig_(Stoppfreigabe)" 1 "Motoranlauf_nicht_zwingend_notwendig_(Stoppverbot,keine_Startanforderung)" 2 "Motoranlauf_zwingend_notwendig_(Startanforderung)" 3 "Systemfehler" ;
VAL_ 924 PH_StartStopp_Info 0 "Motorlauf_nicht_notwendig_(Stoppfreigabe)" 1 "Motoranlauf_nicht_zwingend_notwendig_(Stoppverbot,keine_Startanforderung)" 2 "Motoranlauf_zwingend_notwendig_(Startanforderung)" 3 "Systemfehler" ;
VAL_ 924 KL_Beschlagsgefahr 0 "keine_Beschlagsgefahr" 1 "Beschlagsgefahr" ;
VAL_ 924 BCM1_GLW_Fernlicht_Anf 0 "Aus" 1 "Ein" ;
VAL_ 924 BCM1_RFahrlicht_Fzg_Anf 0 "Licht_nicht_angefordert" 1 "Licht ist einzuschalten" ;
VAL_ 924 FT_Tuer_geoeffnet 1 "Tuer offen" ;
VAL_ 924 MO_Handshake_STH 0 "keine EKP-Ansteuerung durch STH-Anforderung" 1 "EKP-Ansteuerung durch STH-Anforderung" ;
VAL_ 924 FT_Sperrklinke 0 "Schloss_in_Vorraste_und_Hauptraste" 1 "Tuer_auf_oder_Tuer_Position_zwischen_Vor_und_Hauptraste" ;
VAL_ 924 BCM1_OBD_FStatus_ATemp 0 "kein Fehler" 1 "KS-" 2 "KS+" 3 "OC (Leitungsunterbrechung)" 4 "OOR+ (out of range high)" 5 "OOR- (out of range low)" 6 "RC+ (Signal unplausibel hoch)" 7 "RC- (Signal unplausibel niedrig)" 8 "KS+/OC" 9 "KS-/OC" 10 "KS-/KS+" 11 "KS-/KS+/OC (allgemeiner Fehler)" ;
VAL_ 924 BCM1_Aussen_Temp_ungef 253 "nicht verbaut" 254 "Initwert" 255 "Fehler" ;
VAL_ 924 BCM1_Oeldruck_Schalter 0 "offen" 1 "geschlossen (p > p soll)" ;
VAL_ 924 BCM1_Oeldruck_Schalter_2 0 "offen" 1 "geschlossen" ;
VAL_ 924 BT_Tuer_geoeffnet 1 "Tuer_offen" ;
VAL_ 924 HL_Tuer_geoeffnet 1 "Tuer geoeffnet" ;
VAL_ 924 HR_Tuer_geoeffnet 1 "Tuer offen" ;
VAL_ 924 BCM1_Adaptive_Lichtvert_Anf 0 "Aus" 1 "Ein" ;
VAL_ 924 BCM1_Gleitende_Leuchtw_Anf 0 "Aus" 1 "Ein" ;
VAL_ 924 BCM1_Schalter_StartStopp 0 "Start_Stopp_ueber_Hauptschalter_deaktiviert" 1 "Start_Stopp_ueber_Hauptschalter_aktiviert" ;
VAL_ 924 ESP_Offroad_Modus 0 "kein_ESP_Offroadmodus" 1 "ESP_Offroadmodus" ;
VAL_ 924 MO_Freig_Reku 0 "Rekuperations-Modus aus" 1 "Empfehlung Spannungsanhebung" 2 "Empfehlung Spannungsabsenkung" 3 "Rekuperationsmodus aktiv, Spannungsvariation nicht notwendig" ;
VAL_ 1604 SMLS_01_alt 0 "aktuell" 1 "veraltet" ;
VAL_ 1604 BCM1_01_alt 0 "aktuell" 1 "veraltet" ;
VAL_ 1604 BCM1_02_alt 0 "aktuell" 1 "veraltet" ;
VAL_ 1604 BCM2_02_alt 0 "aktuell" 1 "veraltet" ;
VAL_ 1604 HYB_Anf_E_Mode_alt 0 "aktuell" 1 "veraltet" ;
VAL_ 1604 ESP_04_alt 0 "aktuell" 1 "veraltet" ;
VAL_ 1604 BH_Blinker_li 0 "nicht_betaetigt" 1 "Blinkerhebel_Richtung_links_betaetigt" ;
VAL_ 1604 BH_Blinker_re 0 "nicht_betaetigt" 1 "Blinkerhebel_Richtung_rechts_betaetigt" ;
VAL_ 1604 BM_Autobahn 0 "Autobahnblinken nicht aktiv " 1 "Autobahnblinken aktiv " ;
VAL_ 1604 BH_Fernlicht 0 "nicht_betaetigt" 1 "Blinkerhebel_in_Richtung_Fernlicht_betaetigt" ;
VAL_ 1604 BH_Lichthupe 0 "nicht_betaetigt" 1 "Blinkerhebel in Richtung Lichthupe betaetigt" ;
VAL_ 1604 BCM1_MH_Schalter 0 "MH_geschlossen" 1 "MH_offen" ;
VAL_ 1604 HYB_Anf_E_Mode 0 "Taster_nicht_betaetigt" 1 "Taster_betaetigt" ;
VAL_ 1604 HUD_NV_in_Anzeige 0 "NV_nicht_in_Anzeige" 1 "NV_in_Anzeige" ;
VAL_ 1604 BCM1_Touristen_Licht_Anf 0 "Licht_nicht_angefordert" 1 "Anforderung von Touristenlicht" ;
VAL_ 1604 LV_Abblendlicht_li_def 0 "OK" 1 "defekt" ;
VAL_ 1604 LV_Abblendlicht_re_def 0 "OK" 1 "defekt" ;
VAL_ 1604 LV_Abblendlicht_Anzeige 0 "nicht aktiv" 1 "aktiv" ;
VAL_ 1604 LV_AFL_aktiv_Anzeige 0 "nicht aktiv" 1 "aktiv" ;
VAL_ 1604 BCM1_Licht_Dunkelheit_aktiv 1 "Licht wegen Dunkelheit aktiv, nicht bei Autobahnlicht, Tagfahrlicht oder Regenlicht" ;
VAL_ 1604 LV_Nebelschlusslicht_Anzeige 0 "nicht aktiv" 1 "aktiv" ;
VAL_ 1604 BCM1_Linksverkehr 0 "Rechtsverkehr" 1 "Linksverkehr" ;
VAL_ 1604 BCM2_P_verriegelt 0 "WH nicht in Stellung P" 1 "WH in Stellung P" ;
VAL_ 1604 BCM1_LDS_Stellung 0 "Init" 1 "Stellung_0" 2 "Auto" 3 "Standlicht" 4 "Abblendlicht" 7 "Fehler" ;
VAL_ 1604 BCM1_Allwetterlicht_Anf 0 "Licht_nicht_angefordert" 1 "Licht_ist_einzuschalten" ;
VAL_ 1604 HUD_Anzeigefehler_NV 0 "kein_Fehler" 1 "Anzeigefehler" ;
VAL_ 1604 ESP_Diagnose 0 "ESP_nicht_in_Diagnose" 1 "ESP_in_Diagnose" ;
VAL_ 130 GE_Schaltvorgang 0 "keine Schaltung" 1 "Schaltung aktiv" ;
VAL_ 130 GE_Status_Kupplung 0 "Kupplung ge�ffnet" 1 "Kupplung geregelt" 2 "Kupplung geschlossen" 3 "Fehler" ;
VAL_ 130 GE_Verbot_Ausblendung 0 "kein_Verbot" 1 "Verbot" ;
VAL_ 130 GE_MMom_Soll 1022 "kein Eingriff" 1023 "Fehler" ;
VAL_ 130 GE_MMom_Status 0 "keine Anforderung" 1 "reduzierender Getriebeeingriff" 2 "erh�hender Getriebeeingriff" 3 "�nderung mit Sprung" ;
VAL_ 130 GE_MMom_Vorhalt 1022 "keine_Anforderung" 1023 "Fehler" ;
VAL_ 130 GE_Freig_MMom_Vorhalt 0 "nicht_freigegeben" 1 "freigegeben" ;
VAL_ 130 GE_KD_Fehler 0 "kein_KD_Fehler" 1 "KD_Fehler" ;
VAL_ 131 GE_Anf_Zylabsch 0 "Umschaltung erlaubt" 1 "Umschaltung verboten" 3 "VMB-Empfehlung" ;
VAL_ 131 GE_Synchro_Wunschdrehz 511 "Fehler" ;
VAL_ 131 GE_Synchro_Zeit 255 "Fehler" ;
VAL_ 131 GE_Mom_Begr_Gradient 255 "keine Begrenzung (Init)" ;
VAL_ 131 GE_Anheb_Solldrehz_Leerlauf 255 "Fehler" ;
VAL_ 131 GE_Vorsteuermoment 510 "Init" 511 "Fehler" ;
VAL_ 131 GE_Drehzahlmesser_Daempfung 0 "normale D�mpfung" 1 "dynamische D�mpfung" ;
VAL_ 131 GE_Schubabschalt_Unt 0 "inaktiv" 1 "aktiv" ;
VAL_ 131 GE_Freigabe_Synchro 0 "inaktiv" 1 "aktiv" ;
VAL_ 131 GE_HYB_DZ_Eingriff 0 "kein_Drehzahleingriff" 1 "Slip_Start" 2 "Low_Speed_Modus" ;
VAL_ 258 GE_Freig_Langfr_Schutzmom 0 "nicht freigegeben" 1 "freigegeben" ;
VAL_ 258 GE_Uefkt 1023 "Fehler" ;
VAL_ 258 GE_Zielgang 0 "Gang P/N (ausgekuppelt)" 1 "Gang 1" 2 "Gang 2" 3 "Gang 3" 4 "Gang 4" 5 "Gang 5" 6 "Gang 6" 7 "Gang 7" 8 "Gang R" 11 "Gang 8" 12 "Gang 9" 14 "Istgang nicht definiert" 15 "Fehler" ;
VAL_ 258 GE_StartStopp_Info 0 "Motorlauf_nicht_notwendig_(Stoppfreigabe)" 1 "Motoranlauf_nicht_zwingend_notwendig_(Stoppverbot,keine_Startanforderung)" 2 "Motoranlauf_zwingend_notwendig_(Startanforderung)" 3 "Systemfehler" ;
VAL_ 258 GE_Langfr_Schutzmom 1022 "Init" 1023 "Fehler" ;
VAL_ 258 GE_Waehlhebel 0 "Zwischenstellung (Darf nur f�r Zustandswechsel P/R, R/N, N/D ausgegeben werden, nicht f�r D/S oder D/Tippgasse wegen Abschaltkriterium GRA/ACC)" 1 "Init" 5 "Position P" 6 "Position R" 7 "Position N" 8 "Position D" 9 "Position S" 10 "Effizienz" 13 "Tipp_in_S" 14 "Tipp_in_D" 15 "Fehler" ;
VAL_ 258 GE_Eingangsdrehz 16382 "Init" 16383 "Fehler" ;
VAL_ 258 GE_Notlauf 0 "kein Notlauf / Init" 1 "Getriebe im Notlauf" ;
VAL_ 258 GE_Codierung_MSG 0 "Codierung iO / Init" 1 "Codierung niO" ;
VAL_ 1089 GE_Index_Fahrwid 255 "Fehler" ;
VAL_ 1089 GE_Heizwunsch 0 "maximaler_Waermebedarf" 1 "kein_Waermebedarf" 2 "Kuehlbedarf" 3 "Notfall_(maximaler_Kuehlbedarf)" ;
VAL_ 1089 GE_OBD_Status 0 "MIL aus" 1 "MIL ein" ;
VAL_ 1089 GE_LFR_Adaption 0 "fuer_Adaption_geeignet" 1 "fuer_Adaption_nicht_geeignet" ;
VAL_ 1089 GE_OBD_AbsperrVent 0 "kein_Fehler" 1 "KS-" 2 "KS+" 3 "OC" 4 "OOR+" 5 "OOR-" 6 "RC+" 7 "RC-" 8 "KS+/OC" 9 "KS-/OC" 10 "KS-/KS+" 11 "KS-/KS+/OC" 12 "frei" 13 "frei" 14 "frei" 15 "frei" ;
VAL_ 1089 GE_Grenzkriechmoment 62 "Init" 63 "Fehler" ;
VAL_ 1089 GE_Charisma_FahrPr 0 "nicht_belegt" 1 "Programm_1" 2 "Programm_2" 3 "Programm_3" 4 "Programm_4" 5 "Programm_5" 6 "Programm_6" 7 "Programm_7" ;
VAL_ 1089 GE_Charisma_Status 0 "Init" 1 "verfuegbar" 2 "nicht_verfuegbar" 3 "asynchron_durch_Fahrerwunsch" ;
VAL_ 1089 GE_Charisma_Umschaltung 0 "Idle" 1 "Erkennung_Umschaltaufforderung" 2 "Steuerbotschaft_nicht_definiert" 3 "Umschaltung_verzoegert" ;
VAL_ 1089 GE_Freigabe_Verfallsinfo_WFS 0 "aus" 1 "ein" ;
VAL_ 1089 GE_Verlustmoment 255 "Fehler" ;
VAL_ 1089 GE_amax_moeglich 511 "Wert ist nicht definiert" ;
VAL_ 1089 GE_Sumpftemperatur 255 "Fehler" ;
VAL_ 1424 KY_Funkschl_Nr 0 "kein authorisierter Schluessel erkannt" 1 "aktive_Funkschluessel_Nr_01" 2 "aktive_Funkschluessel_Nr_02" 3 "aktive_Funkschluessel_Nr_03" 4 "aktive_Funkschluessel_Nr_04" 5 "aktive_Funkschluessel_Nr_05" 6 "aktive_Funkschluessel_Nr_06" 7 "aktive_Funkschluessel_Nr_07" 8 "aktive_Funkschluessel_Nr_08" 9 "ungueltig_09" 10 "ungueltig_10" 11 "ungueltig_11" 12 "ungueltig_12" 13 "ungueltig_13" 14 "ungueltig_14" 15 "ungueltig_15" ;
VAL_ 1424 KY_ID_Geb_autorisiert 0 "Schluessel_nicht_authorisiert" 1 "Schluessel authorisiert" ;
VAL_ 1424 KY_ID_Geb_steckt 0 "kein_Schluessel_im_Zuendschloss" 1 " Schluessel steckt im Zuendschloss" ;
VAL_ 1424 KY_FFB_Frequenz 1 "433 MHz" 2 "315 MHz" 3 "868 MHz" ;
VAL_ 1424 KY_HF_Aktiv 0 "Funktempfang_nicht_aktiv" 1 "HF_Funkempfang_aktiv" ;
VAL_ 1424 KY_LF_Aktiv 0 "Funktempfang_nicht_aktiv" 1 "LF_Funkempfang_aktiv" ;
VAL_ 1424 KY_ELV_verr 0 "ELV_nicht_verriegelt" 1 "ELV verriegelt" ;
VAL_ 1424 KY_ELV_entr 0 "ELV_nicht_entriegelt" 1 "ELV entriegelt" ;
VAL_ 1424 KY_ELV_enable_Anforderung 0 "Freigabe_nicht_angefordert" 1 "Freigabe ELV wird angefordert" ;
VAL_ 1424 KY_Valet_Parking 0 "kein_Valet_Schluessel_erkannt" 1 "Valet Schluessel erkannt" ;
VAL_ 1424 KY_Keyless_Verbau 0 "kein_Keyless_verbaut" 1 "Keyless verbaut" ;
VAL_ 1424 FBS_Warn_Lenkung_def 0 "iO" 1 "defekt" ;
VAL_ 1424 FBS_Warn_LenkVerriegelung_def 0 "i.O." 1 "defekt" ;
VAL_ 1424 FBS_Warn_Schluessel_Batt 0 "i.O." 1 "defekt" ;
VAL_ 1424 FBS_Prio_Warn_04 1 "Kombi Prio Warnung FBS 4" ;
VAL_ 1424 FBS_Prio_Warn_05 1 "Kombi Prio Warnung FBS 5" ;
VAL_ 1424 KYL_Warn_kein_Schluessel 1 "kein Schluessel erkannt" ;
VAL_ 1424 KYL_Warn_Kessy_defekt 0 "Kessy_i.O." 1 "Kessy defekt" ;
VAL_ 1424 KY_KYL_Prio_Warn_03 1 "Kombi Prio Warnung Keyless 3" ;
VAL_ 1424 KY_KYL_Prio_Warn_04 1 "Kombi Prio Warnung Keyless 4" ;
VAL_ 1424 KY_KYL_Prio_Warn_05 1 "Kombi Prio Warnung Keyless 5" ;
VAL_ 1424 KY_WFS_Safe 1 "WFS nicht deaktiviert" ;
VAL_ 1424 KY_WFS_LZ 0 "nicht def." 1 "LZ 1" 2 "LZ 2" 3 "LZ 3" ;
VAL_ 1424 KY_StartStopp_Info 0 "Motorlauf_nicht_notwendig_(Stoppfreigabe)" 1 "Motoranlauf_nicht_zwingend_notwendig_(Stoppverbot,keine_Startanforderung)" 2 "Motoranlauf_zwingend_notwendig_(Startanforderung)" 3 "Systemfehler" ;
VAL_ 1424 KYL_Notzuendschloss 0 "nicht_verbaut" 1 "verbaut" ;
VAL_ 1424 KYL_Warn_Notzuendschloss 0 "Aus" 1 "Ein" ;
VAL_ 1424 FBS_KD_Fehler 0 "kein_KD_Fehler" 1 "KD_Fehler" ;
VAL_ 960 ZV_verriegelt_extern_soll_02 1 "Fahrzeug verriegelt extern; Sollzusstand" ;
VAL_ 960 ZAS_Kl_S 0 "aus" 1 "S_Kontakt_ein" ;
VAL_ 960 ZAS_Kl_15 0 "aus" 1 "ein" ;
VAL_ 960 ZAS_Kl_X 0 "aus" 1 "ein" ;
VAL_ 960 ZAS_Kl_50 0 "aus" 1 "KL50_ein_Startwunsch_Fahrer" ;
VAL_ 959 KL_Drehz_Anh 0 "keine_Anhebung" 1 "Drehzahlanhebung_vom_Motor_angefordert" ;
VAL_ 959 KL_Vorwarn_Komp_ein 1 "Vorwarnung Kompressor ein" ;
VAL_ 959 KL_Handshake_BEM 0 "keine_Leistungsaenderung_in_den_Heizsystemen_aktiv" 1 "Heizleistungsaenderung_wird_gerade_durchgefuehrt" ;
VAL_ 959 KL_Komp_Moment_alt 1 "veraltet_bzw_Ermittlung_des_Moments_nicht_moeglich__zB_keine_Drehzahl_kein_Kaeltemitteldruck" ;
VAL_ 959 KL_Vorwarn_HHS_ein 1 "Vorwarnung_Heckscheibenheizung_ein" ;
VAL_ 959 KL_Vorwarn_HFS_ein 1 "Vorwarnung_Frontscheibenheizung_ein" ;
VAL_ 959 KL_Vorwarn_Zuheizer_ein 1 "Vorwarnung_Zuheizer_ein" ;
VAL_ 959 KL_KD_Fehler 0 "kein_KD_Fehler" 1 "KD_Fehler" ;
VAL_ 959 KL_Comp_rev_rq 255 "Fehler" ;
VAL_ 959 KL_Charisma_FahrPr 0 "nicht_belegt" 1 "Programm_1" 2 "Programm_2" 3 "Programm_3" 4 "Programm_4" 5 "Programm_5" 6 "Programm_6" 7 "Programm_7" ;
VAL_ 959 KL_Charisma_Status 0 "Init" 1 "verfuegbar" 2 "nicht_verfuegbar" 3 "asynchron_durch_Fahrerwunsch" ;
VAL_ 959 KL_Charisma_Umschaltung 0 "Idle" 1 "Erkennung_Umschaltaufforderung" 2 "Steuerbotschaft_nicht_definiert" 3 "Umschaltung_verzoegert" ;
VAL_ 959 KL_Last_Kompr 255 "Fehler" ;
VAL_ 959 KL_Anf_KL 255 "Fehler" ;
VAL_ 959 KL_4_Zonen 0 "2_Zonen_Klimaanlage" 1 "4_Zonen_Klimaanlage" ;
VAL_ 959 KL_AC_Schalter 0 "aus" 1 "ein" ;
VAL_ 959 KL_Zustand 0 "aus" 1 "ein" ;
VAL_ 959 KL_Thermomanagement 0 "keine_Freigabe_TMM__max_Heizbedarf" 1 "kleine_Freigabe_TMM" 2 "mittlere_Freigabe_TMM" 3 "volle_Freigabe_TMM__kein_Heizbedarf" ;
VAL_ 959 KL_Comp_enable 0 "Disable" 1 "Enable" ;
VAL_ 959 KL_StartStopp_Info 0 "Motorlauf_nicht_notwendig_(Stoppfreigabe)" 1 "Motoranlauf_nicht_zwingend_notwendig_(Stoppverbot,keine_Startanforderung)" 2 "Motoranlauf_zwingend_notwendig_(Startanforderung)" 3 "Systemfehler" ;
VAL_ 959 KL_Diag_Absperrvent 0 "kein_Fehler" 1 "KS-" 2 "KS+" 3 "OC" 4 "OOR+" 5 "OOR-" 6 "RC+" 7 "RC-" 8 "KS+/OC" 9 "KS-/OC" 10 "KS-/KS+" 11 "KS-/KS+/OC" ;
VAL_ 779 KBI_ABS_Lampe 0 "ABS Lampe aus" 1 "ABS Lampe ein" ;
VAL_ 779 KBI_ESP_Lampe 0 "ESP Lampe aus" 1 "ESP Lampe ein" ;
VAL_ 779 KBI_BKL_Lampe 0 "BKL aus" 1 "BKL ein" ;
VAL_ 779 KBI_Airbag_Lampe 0 "Airbag Lampe aus" 1 "Airbag Lampe ein" ;
VAL_ 779 KBI_SILA_gueltig 0 "ungueltig" 1 "gueltig" ;
VAL_ 779 KBI_Vorglueh_System_Lampe 0 "Lampe aus" 1 "Lampe ein" ;
VAL_ 779 KBI_NV_in_Anzeige 0 "NV_nicht_in_Anzeige" 1 "NV_in_Anzeige" ;
VAL_ 779 KBI_Anzeigestatus_ACC 0 "keine_ACC_Anzeige" 1 "ACC_Anzeige_aktiv" ;
VAL_ 779 KBI_Tankwarnung 0 "Lampe aus" 1 "Lampe ein" ;
VAL_ 779 KBI_MFA_v_Einheit_01 0 "kmh" 1 "mph" ;
VAL_ 779 KBI_im_Stellgliedtest 0 "kein Stellgliedtest" 1 "Kombi im Stellgliedtest" ;
VAL_ 779 KBI_Anzeigefehler_LDW 0 "nicht vorhanden bzw. unterst�tzt" 1 "Anzeige iO" 2 "Anzeigefehler" 3 "nicht definiert" ;
VAL_ 779 KBI_Variante_USA 0 "keine USA-Variante" 1 "USA-Variante" ;
VAL_ 779 KBI_Oeldruckwarnung 0 "inaktiv" 1 "aktiv" ;
VAL_ 779 KBI_Handbremse 0 "nicht_angezogen" 1 "angezogen" ;
VAL_ 779 KBI_PLA_in_Anzeige 0 "PLA_nicht_in_Anzeige" 1 "PLA_in_Anzeige" ;
VAL_ 779 KBI_Anzeigefehler_NV 0 "kein_Anzeigefehler" 1 "Anzeigefehler" ;
VAL_ 779 KBI_Einheit_Tacho 0 "km/h" 1 "mph" ;
VAL_ 779 KBI_Konsistenz_ACC 0 "ACC Botschaft konsistent" 1 "ACC Botschaft inkonsistent    " ;
VAL_ 779 KBI_Fehler_Anzeige_ACC 0 " iO" 1 "Anzeigefehler ACC" ;
VAL_ 779 KBI_Anzeigefehler_SWA 0 "nicht vorhanden bzw. unterst�tzt" 1 "Anzeige iO" 2 "Anzeigefehler" 3 "nicht definiert" ;
VAL_ 779 KBI_KD_Fehler 0 "kein_KD_Fehler" 1 "KD_Fehler" ;
VAL_ 1719 KBI_Kilometerstand 1048574 "Init" 1048575 "Fehler" ;
VAL_ 1719 KBI_Reset_Standzeit 0 "Standzeit iO" 1 "KL30 war weg" ;
VAL_ 1719 KBI_Inhalt_Tank 127 "Fehler" ;
VAL_ 1719 KBI_FStatus_Tank 0 "Tankf�llstand i.O." 1 "Tankf�llstand n.i.O" ;
VAL_ 1719 KBI_QBit_Aussen_Temp_gef 0 "gueltiger_Wert" 1 "Ersatz_Init_oder_Fehlerwert" ;
VAL_ 1719 KBI_Aussen_Temp_gef 253 "nicht verbaut" 254 "Init" 255 "Fehler" ;
VAL_ 1720 WFS_Schluessel_Fahrberecht 0 "kein authorisierter Schluessel erkannt " 1 "aktive_Funkschluessel_Nr_01" 2 "aktive_Funkschluessel_Nr_02" 3 "aktive_Funkschluessel_Nr_03" 4 "aktive_Funkschluessel_Nr_04" 5 "aktive_Funkschluessel_Nr_05" 6 "aktive_Funkschluessel_Nr_06" 7 "aktive_Funkschluessel_Nr_07" 8 "aktive_Funkschluessel_Nr_08" 9 "ungueltig_09" 10 "ungueltig_10" 11 "ungueltig_11" 12 "ungueltig_12" 13 "ungueltig_13" 14 "ungueltig_14" 15 "ungueltig_15" ;
VAL_ 1720 KBI_BCmE_aktiv 0 "Anzeige_nicht_aktiv" 1 "Anzeige_aktiv" ;
VAL_ 1720 KBI_Sparhinweis_quittiert 0 "nicht_quittiert" 1 "quittiert" ;
VAL_ 285 EPS_Notlauf 0 "kein_Notlauf" 1 "Notlauf_Unterspannung" 2 "Notlauf_Ueberspannung" 3 "reserviert" 4 "Notlauf_Uebertemperatur" 5 "Notlauf_Unterspannung_und_Uebertemperatur" 6 "Notlauf_Ueberspannung_und_Uebertemperatur" 7 "reserviert" 8 "reserviert" 9 "reserviert" 10 "reserviert" 11 "reserviert" 12 "reserviert" 13 "reserviert" 14 "reserviert" 15 "reserviert" ;
VAL_ 285 EPS_Lastinfo 255 "Fehler" ;
VAL_ 285 EPS_Unterstuetzungsleistung 255 "Fehler" ;
VAL_ 285 EPS_Drehzahlreserve 127 "Fehler" ;
VAL_ 285 EPS_VZ_Drehzahlreserve 0 "positiv" 1 "negativ" ;
VAL_ 285 EPS_Leistungsanforderung 0 "keine_Anforderung" 1 "Anforderung_hoehere_Spannung_oder_Leistung" ;
VAL_ 1137 BCM2_Bremsl_durch_ECD 0 "Bremslicht_ist_aus" 1 "Bremslicht_durch_ECD_aktiv" ;
VAL_ 1137 LH_Aussenlicht_def 0 "OK" 1 "defekt" ;
VAL_ 1137 LH_Standlicht_H_aktiv 1 "Standlicht hinten aktiv" ;
VAL_ 1137 LH_Parklicht_HL_aktiv 0 "nicht aktiv" 1 "Parklicht hinten links aktiv" ;
VAL_ 1137 LH_Parklicht_HR_aktiv 0 "nicht aktiv" 1 "Parklicht hinten rechts aktiv" ;
VAL_ 1137 LH_Bremslicht_H_aktiv 1 "Bremslicht hinten aktiv" ;
VAL_ 1137 LH_Nebelschluss_aktiv 0 "nicht aktiv" 1 "aktiv" ;
VAL_ 1137 LH_Rueckfahrlicht_aktiv 0 "nicht aktiv" 1 "aktiv" ;
VAL_ 1137 LH_Blinker_HL_akt 1 "Blinker hinten links aktiv" ;
VAL_ 1137 LH_Blinker_HR_akt 1 "Blinker hinten rechts aktiv" ;
VAL_ 1137 LH_Blinker_li_def 0 "OK" 1 "Blinker hinten links defekt" ;
VAL_ 1137 LH_Bremsl_li_def 0 "OK" 1 "mindestens ein Bremslicht hinten links defekt" ;
VAL_ 1137 LH_Schlusslicht_li_def 0 "OK" 1 "mindestens ein Schlusslicht hinten links defekt" ;
VAL_ 1137 LH_Rueckf_li_def 0 "OK" 1 "R�ckfahrlicht hinten links defekt" ;
VAL_ 1137 LH_Nebel_li_def 0 "OK" 1 " Nebelschlusslicht hinten links defekt" ;
VAL_ 1137 LH_Schluss_Brems_Nebel_li_def 0 "iO" 1 "defekt" ;
VAL_ 1137 LH_Schluss_Brems_Nebel_re_def 0 "iO" 1 "defekt" ;
VAL_ 1137 LH_Schluss_Brems_li_def 0 "OK" 1 "defekt" ;
VAL_ 1137 LH_Schluss_Nebel_li_def 0 "OK" 1 "defekt" ;
VAL_ 1137 LH_SL_BRL_BLK_li_def 0 "OK" 1 "defekt" ;
VAL_ 1137 LH_Brems_Blk_li_def 0 "OK" 1 "defekt" ;
VAL_ 1137 LH_Blinker_re_def 0 "OK" 1 "Blinker hinten rechts defekt" ;
VAL_ 1137 LH_Bremsl_re_def 0 "OK" 1 "mindestens ein Bremslicht hinten rechts defekt" ;
VAL_ 1137 LH_Schlusslicht_re_def 0 "OK" 1 "mindestens ein Schlusslicht hinten rechts defekt" ;
VAL_ 1137 LH_Rueckf_re_def 0 "OK" 1 "R�ckfahrlicht hinten rechts defekt" ;
VAL_ 1137 LH_Nebel_re_def 0 "OK" 1 "Nebelschlusslicht hinten rechts defekt" ;
VAL_ 1137 LH_Schluss_Brems_re_def 0 "OK" 1 "defekt" ;
VAL_ 1137 LH_Schluss_Nebel_re_def 0 "OK" 1 "defekt" ;
VAL_ 1137 LH_SL_BRL_BLK_re_def 0 "OK" 1 "defekt" ;
VAL_ 1137 LH_Brems_Blk_re_def 0 "OK" 1 "defekt" ;
VAL_ 1137 LH_Kennzl_def 0 "OK" 1 "Kennzeichenbeleuchtung hinten defekt" ;
VAL_ 1137 LH_3_Bremsl_def 0 "OK" 1 "hochgesetzte  Bremsleuchte defekt" ;
VAL_ 1137 LH_Nebel_mi_def 0 "OK" 1 " Nebelschlusslicht hinten Mitte defekt" ;
VAL_ 1137 LH_Rueckf_mi_def 0 "OK" 1 "R�ckfahllicht Mitte defekt" ;
VAL_ 1137 LH_Bremsl_li_ges_def 0 "OK" 1 "Alle Bremslichter hinten links defekt" ;
VAL_ 1137 LH_Bremsl_re_ges_def 0 "OK" 1 "Alle Bremslichter hinten rechts defekt" ;
VAL_ 780 ACC_Wunschgeschw_02 1023 "keine_Anzeige" ;
VAL_ 780 ACC_Status_Prim_Anz 0 "Symbol nicht beleuchtet" 1 "Farbe 1 (typisch 'gruen')" 2 "Farbe 2 (typisch 'rot')" 3 "Farbe 3 (typisch 'gelb')" ;
VAL_ 780 ACC_Abstandsindex 0 "Sonderanzeige_graue_Fahrbahn" 1022 "Sonderanzeige_graue_Fahrbahn" 1023 "Sonderanzeige_Fahrbahn_mit_gruenem_roten_Bereich" ;
VAL_ 780 ACC_Akustik_02 0 "keine_Akustik" 1 "hochpriore_Akustik" 2 "niederpriore_Akustik" 3 "hochpriore_Dauerakustik" ;
VAL_ 780 ACC_Warnung_Verkehrszeichen_1 0 "keine_Warnung_Initialwert" 1 "Warnung" ;
VAL_ 780 ACC_Gesetzte_Zeitluecke 0 "keine_Anzeige" 1 "Zeitluecke_1" 2 "Zeitluecke_2" 3 "Zeitluecke_3" 4 "Zeitluecke_4" 5 "Zeitluecke_5" 6 "nicht_definiert" 7 "nicht_definiert" ;
VAL_ 780 ACC_Optischer_Fahrerhinweis 0 "optischer_Fahrerhinweis_AUS" 1 "optischer_Fahrerhinweis_EIN" ;
VAL_ 780 ACC_Typ_Tachokranz 0 "Tachokranz_lang" 1 "Tachokranz_kurz" ;
VAL_ 780 ACC_Anzeige_Zeitluecke 0 "Anzeige_Zeitluecke_nicht_angefordert" 1 "Anzeige_Zeitluecke_angefordert" ;
VAL_ 780 ACC_Tachokranz 0 "Tachokranz_nicht_beleuchtet" 1 "Tachokranz_beleuchtet" ;
VAL_ 780 ACC_Display_Prio 0 "hoechste_Prio" 1 "mittlere_Prio" 2 "geringe_Prio" 3 "keine_Prio" ;
VAL_ 780 ACC_Relevantes_Objekt 0 "Symbol_nicht_beleuchtet" 1 "Farbe_1_typisch_gruen" 2 "Farbe_2_typisch_rot" 3 "Farbe_3_typisch_gelb" ;
VAL_ 780 ACC_Texte_Primaeranz 0 "keine Anzeige" 1 "ACC nicht verfuegbar !" 2 "Auto_Auto_ _ _" 3 "Auto_ _Auto_ _" 4 "Auto_ _ _Auto_" 5 "Auto_ _ _ _Auto" 6 "Auto_Auto_ _ _ Gong (durchgestrichen)" 7 "Auto_ _Auto_ _ Gong (durchgestrichen)" 8 "Auto_ _ _Auto_ Gong (durchgestrichen)" 9 "Auto_ _ _ _Auto Gong (durchgestrichen)" 10 "ACC bereit" 11 "keine Abstandsregelung" 12 "ACC Sensor Sicht !" 13 "ACC nicht verfuegbar" 14 "o  o  o" 15 "Hochschalten" 16 "ESP Eingriff" 17 "Herunterschalten" 18 "Parkbremse !" 19 "Geschwindigkeitsgrenze" 20 "Waehlhebelposition !" 21 "VDA ACC-Symbol YYY km/h / mph" 22 "Tempolimit XXX km/h / mph" 23 "Kurve XXX km/h / mph" 24 "ACC Abschaltung" 25 "Symbol 'Eieruhr'" 26 "!" 27 "--- km/h / mph" 28 "XXX km/h / mph (Schriftart 2)" 29 "Lenkradwinkel" 30 "Anfahren bestaetigen" 31 "Fahrzeug verloren" 32 "Im Stand nicht moeglich" 33 "Ungueltiger Anfahrbefehl" 34 "Tuer offen !" 35 "Fahrer Gurtschloss offen !" 36 "Schalthebelposition !" 37 "Drehzahl !" 38 "Kurvenassistent aus" 39 "Tempolimit aus" 40 "Abbiegeassistent" 41 "Ortsanfang XXX km/h / mph" 42 "Ortsende XXX km/h / mph" 43 "Tempolimit Ende XXX km/h / mph" 44 "HDC aktiv" 45 "braking guard Bremsruck" 46 "braking guard aus" 47 "braking guard aus" 48 "Uebernehmen !" 49 "Steigung zu gross" 50 "Stehendes Objekt voraus" 51 "SET / 'GRA Symbol'___xxx km/h / mph" 52 "SET / 'GRA Symbol' xxx km/h / mph" 53 "ACC aus" 54 "ACC startet" 55 "ACC reinigen" 56 "ACC Fehler" 57 "ACC haelt an !" 58 "Bremse betaetigen !" 59 "Kupplung betaetigt" 60 "LIM AUS" 61 "LIM AKTIV" 62 "LIM PASSIV" 63 "LIM FEHLER" 64 "Bremse ueberhitzt !" 65 "Bremse haelt !" 66 "ESP PASSIV !" 67 "ACC_anfahrbereit" 68 "Gang_einlegen" 69 "Rechtsueberholen_verhindert" 70 "Linksueberholen_verhindert" 71 "Achtung_Geschwindigkeitsueberschreitung" 72 "Tempolimit_und_Kurvenassistent_nicht_verfuegbar" ;
VAL_ 780 ACC_Wunschgeschw_erreicht 0 "Wunschgeschwindigkeit_nicht_erreicht" 1 "Wunschgeschwindigkeit_erreicht" ;
VAL_ 780 ACC_Typ_Tachokranz_unten 0 "LEDs_an" 1 "LEDs_aus" ;
VAL_ 780 ACC_Status_Anzeige 0 "ACC_GRA_Hauptschalter_aus" 1 "ACC_in_Init_nicht_bei_GRA" 2 "ACC_GRA_passiv" 3 "ACC_GRA_aktiv" 4 "ACC_GRA_im_Hintergrund_uebertreten" 5 "ACC_GRA_Abschaltreaktion" 6 "ACC_reversibel_aus_nicht_bei_GRA" 7 "ACC_GRA_irreversibel_aus" ;
